VERSION "dbc-export 1 2025.20.8"

NS_ :

BS_:

BU_: BMS CC CMP CMPD CP DAS DI DIF DIR EPBL EPBR EVSE FC GTW HCML HCMR HVP ICR PCS PM PMF PMR PTC SCCM SCM SCS SDCR TAS UMC VC VCFRONT VCLEFT VCRIGHT VCSEC

BO_ 818 BMS_bmbMinMax: 6 BMS
 SG_ BMS_bmbMinMaxMultiplexer M : 0|2@1+ (1,0) [0|3] "" Vector__XXX
 SG_ BMS_thermistorNumTMin m0 : 2|4@1+ (1,0) [0|15] "" Vector__XXX
 SG_ BMS_thermistorNumTMax m0 : 8|4@1+ (1,0) [0|15] "" Vector__XXX
 SG_ BMS_thermistorTMax m0 : 16|8@1+ (0.5,-40) [-40|87.5] "DegC" Vector__XXX
 SG_ BMS_thermistorTMin m0 : 24|8@1+ (0.5,-40) [-40|87.5] "DegC" Vector__XXX
 SG_ BMS_thermistorTAvg m0 : 32|8@1+ (0.5,-40) [-40|87.5] "DegC" Vector__XXX
 SG_ BMS_brickVoltageMax m1 : 2|12@1+ (0.002,0) [0|5] "V" Vector__XXX
 SG_ BMS_brickVoltageMin m1 : 16|12@1+ (0.002,0) [0|5] "V" Vector__XXX
 SG_ BMS_brickNumVoltageMax m1 : 32|7@1+ (1,1) [1|128] "" Vector__XXX
 SG_ BMS_brickNumVoltageMin m1 : 40|7@1+ (1,1) [1|128] "" Vector__XXX

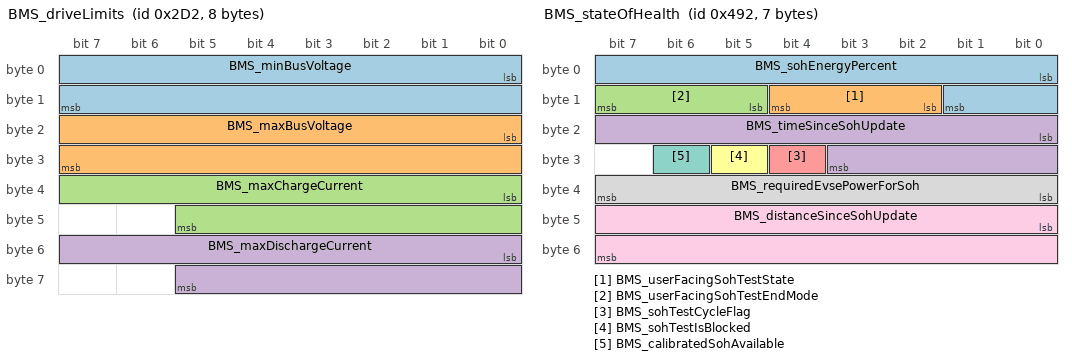
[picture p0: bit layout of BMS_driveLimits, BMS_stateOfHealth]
BO_ 722 BMS_driveLimits: 8 BMS
 SG_ BMS_minBusVoltage : 0|16@1+ (0.02,0) [0|1200] "V" Vector__XXX
 SG_ BMS_maxBusVoltage : 16|16@1+ (0.02,0) [0|1200] "V" Vector__XXX
 SG_ BMS_maxChargeCurrent : 32|14@1+ (0.1,0) [0|1638.2] "A" Vector__XXX
 SG_ BMS_maxDischargeCurrent : 48|14@1+ (0.15,0) [0|2455] "A" Vector__XXX

BO_ 850 BMS_energyStatus: 8 BMS
 SG_ BMS_energyStatusMultiplexer M : 0|2@1+ (1,0) [0|3] "" Vector__XXX
 SG_ BMS_nominalFullPackEnergy m0 : 16|16@1+ (0.02,0) [0|1310.68] "kWh" Vector__XXX
 SG_ BMS_nominalEnergyRemaining m0 : 32|16@1+ (0.02,0) [0|1310.68] "kWh" Vector__XXX
 SG_ BMS_idealEnergyRemaining m0 : 48|16@1+ (0.02,0) [0|1310.68] "kWh" Vector__XXX
 SG_ BMS_fullChargeComplete m1 : 15|1@1+ (1,0) [0|1] "" Vector__XXX
 SG_ BMS_energyBuffer m1 : 16|16@1+ (0.01,0) [0|655.34] "kWh" Vector__XXX
 SG_ BMS_expectedEnergyRemaining m1 : 32|16@1+ (0.02,0) [0|1310.68] "kWh" Vector__XXX
 SG_ BMS_energyToChargeComplete m1 : 48|16@1+ (0.02,0) [0|1310.68] "kWh" Vector__XXX
 SG_ BMS_energyRemainingDisplay m2 : 8|16@1+ (0.02,0) [0|1310.68] "kWh" Vector__XXX
 SG_ BMS_energyRemainingTDisplay m2 : 24|16@1+ (0.02,0) [0|1310.68] "kWh" Vector__XXX
 SG_ BMS_energyDisplayErrorBlendRate m2 : 40|12@1+ (0.0156288165599,0) [0|64] "%" Vector__XXX
 SG_ BMS_userFacingSoe m2 : 52|11@1+ (0.05,0) [0|100] "%" Vector__XXX

BO_ 768 BMS_info: 8 BMS
 SG_ BMS_infoIndex M : 0|8@1+ (1,0) [0|255] "" Vector__XXX
 SG_ BMS_buildType m10 : 8|3@1+ (1,0) [0|7] "" Vector__XXX
 SG_ BMS_buildConfigId m10 : 16|16@1+ (1,0) [0|65535] "" Vector__XXX
 SG_ BMS_hardwareId m10 : 32|16@1+ (1,0) [0|65535] "" Vector__XXX
 SG_ BMS_componentId m10 : 48|16@1+ (1,0) [0|65535] "" Vector__XXX
 SG_ BMS_pcbaId m11 : 16|8@1+ (1,0) [0|255] "" Vector__XXX
 SG_ BMS_assemblyId m11 : 24|8@1+ (1,0) [0|255] "" Vector__XXX
 SG_ BMS_usageId m11 : 32|16@1+ (1,0) [0|65535] "" Vector__XXX
 SG_ BMS_subUsageId m11 : 48|16@1+ (1,0) [0|65535] "" Vector__XXX
 SG_ BMS_platformType m13 : 8|8@1+ (1,0) [0|255] "" Vector__XXX
 SG_ BMS_appCrc m13 : 32|32@1+ (1,0) [0|4294967295] "" Vector__XXX
 SG_ BMS_appGitHash m17 : 8|56@1+ (1,0) [0|7.20575940379e+16] "" Vector__XXX
 SG_ BMS_bootGitHash m18 : 8|56@1+ (1,0) [0|7.20575940379e+16] "" Vector__XXX
 SG_ BMS_bootUdsProtoVersion m20 : 8|8@1+ (1,0) [0|255] "" Vector__XXX
 SG_ BMS_bootCrc m20 : 32|32@1+ (1,0) [0|4294967295] "" Vector__XXX

BO_ 978 BMS_kwhCounter: 8 BMS
 SG_ BMS_kwhDischargeTotal : 0|32@1+ (0.001,0) [0|268435.456] "KWh" Vector__XXX
 SG_ BMS_kwhChargeTotal : 32|32@1+ (0.001,0) [0|268435.456] "KWh" Vector__XXX

BO_ 1010 BMS_kwhCountersMultiplexed: 8 BMS
 SG_ BMS_kwhCounter_Id M : 0|4@1+ (1,0) [0|15] "" Vector__XXX
 SG_ BMS_acChargerKwhTotal m0 : 8|32@1+ (0.001,0) [0|268435.456] "KWh" Vector__XXX
 SG_ BMS_dcChargerKwhTotal m1 : 8|32@1+ (0.001,0) [0|268435.456] "KWh" Vector__XXX
 SG_ BMS_kwhRegenChargeTotal m2 : 8|32@1+ (0.001,0) [0|268435.456] "KWh" Vector__XXX
 SG_ BMS_kwhDriveDischargeTotal m3 : 8|32@1+ (0.001,0) [0|268435.456] "KWh" Vector__XXX
 SG_ BMS_kwhDischargeTotalModule1 m4 : 8|28@1+ (0.001,0) [0|268435.455] "KWh" Vector__XXX
 SG_ BMS_kwhChargeTotalModule1 m4 : 36|28@1+ (0.001,0) [0|268435.455] "KWh" Vector__XXX
 SG_ BMS_kwhAcChargeTotalModule1 m5 : 8|28@1+ (0.001,0) [0|268435.455] "KWh" Vector__XXX
 SG_ BMS_kwhDcChargeTotalModule1 m5 : 36|28@1+ (0.001,0) [0|268435.455] "KWh" Vector__XXX
 SG_ BMS_kwhDischargeTotalModule2 m6 : 8|28@1+ (0.001,0) [0|268435.455] "KWh" Vector__XXX
 SG_ BMS_kwhChargeTotalModule2 m6 : 36|28@1+ (0.001,0) [0|268435.455] "KWh" Vector__XXX
 SG_ BMS_kwhAcChargeTotalModule2 m7 : 8|28@1+ (0.001,0) [0|268435.455] "KWh" Vector__XXX
 SG_ BMS_kwhDcChargeTotalModule2 m7 : 36|28@1+ (0.001,0) [0|268435.455] "KWh" Vector__XXX
 SG_ BMS_kwhDischargeTotalModule3 m8 : 8|28@1+ (0.001,0) [0|268435.455] "KWh" Vector__XXX
 SG_ BMS_kwhChargeTotalModule3 m8 : 36|28@1+ (0.001,0) [0|268435.455] "KWh" Vector__XXX
 SG_ BMS_kwhAcChargeTotalModule3 m9 : 8|28@1+ (0.001,0) [0|268435.455] "KWh" Vector__XXX
 SG_ BMS_kwhDcChargeTotalModule3 m9 : 36|28@1+ (0.001,0) [0|268435.455] "KWh" Vector__XXX
 SG_ BMS_kwhDischargeTotalModule4 m10 : 8|28@1+ (0.001,0) [0|268435.455] "KWh" Vector__XXX
 SG_ BMS_kwhChargeTotalModule4 m10 : 36|28@1+ (0.001,0) [0|268435.455] "KWh" Vector__XXX
 SG_ BMS_kwhAcChargeTotalModule4 m11 : 8|28@1+ (0.001,0) [0|268435.455] "KWh" Vector__XXX
 SG_ BMS_kwhDcChargeTotalModule4 m11 : 36|28@1+ (0.001,0) [0|268435.455] "KWh" Vector__XXX

BO_ 1170 BMS_stateOfHealth: 7 BMS
 SG_ BMS_sohEnergyPercent : 0|10@1+ (0.1,0) [0|100] "%" Vector__XXX
 SG_ BMS_userFacingSohTestState : 10|3@1+ (1,0) [0|7] "" Vector__XXX
 SG_ BMS_userFacingSohTestEndMode : 13|3@1+ (1,0) [0|7] "" Vector__XXX
 SG_ BMS_timeSinceSohUpdate : 16|12@1+ (1,0) [0|3650] "days" Vector__XXX
 SG_ BMS_sohTestCycleFlag : 28|1@1+ (1,0) [0|1] "" Vector__XXX
 SG_ BMS_sohTestIsBlocked : 29|1@1+ (1,0) [0|1] "" Vector__XXX
 SG_ BMS_calibratedSohAvailable : 30|1@1+ (1,0) [0|1] "" Vector__XXX
 SG_ BMS_requiredEvsePowerForSoh : 32|8@1+ (0.125,0) [0|31.75] "kW" Vector__XXX
 SG_ BMS_distanceSinceSohUpdate : 40|16@1+ (1,0) [0|65534] "km" Vector__XXX

BO_ 1116 CC_alertLog: 8 CC
 SG_ CC_alertID M : 0|15@1+ (1,0) [0|32767] "" Vector__XXX
 SG_ CC_alertType : 15|1@1+ (1,0) [0|1] "" Vector__XXX
 SG_ CC_a001_groundResistance m1 : 16|12@1+ (1000,0) [0|4094000] "Ohm" Vector__XXX
 SG_ CC_a003_gfciRmsCurrent m3 : 16|12@1+ (0.001,0) [0|4.095] "A" Vector__XXX
 SG_ CC_a003_gfciRmsCurrentAvg m3 : 28|12@1+ (0.001,0) [0|4.095] "A" Vector__XXX
 SG_ CC_a003_dcGfciCurrent m3 : 40|10@1- (0.001,0) [-0.512|0.511] "A" Vector__XXX
 SG_ CC_a003_gfciFaultReason m3 : 50|4@1+ (1,0) [1|15] "" Vector__XXX
 SG_ CC_a003_gfciFaultBucket m3 : 56|4@1+ (1,0) [0|15] "" Vector__XXX
 SG_ CC_a004_gfciErrorReason m4 : 16|8@1+ (1,0) [1|255] "" Vector__XXX
 SG_ CC_a004_gfciAsicErrorBitfield m4 : 24|8@1+ (1,0) [0|255] "" Vector__XXX
 SG_ CC_a004_gfciSelfTestDuty m4 : 32|16@1- (0.0001,50) [46.7232|53.2767] "A" Vector__XXX
 SG_ CC_a004_gfciSelfTestCurrent m4 : 48|16@1- (0.0001,0) [-3.2768|3.2767] "A" Vector__XXX
 SG_ CC_a006_line1Current m6 : 16|16@1+ (0.01,0) [0|655.35] "A" Vector__XXX
 SG_ CC_a006_line2Current m6 : 32|16@1+ (0.01,0) [0|655.35] "A" Vector__XXX
 SG_ CC_a006_line3Current m6 : 48|16@1+ (0.01,0) [0|655.35] "A" Vector__XXX
 SG_ CC_a007_inputVoltage m7 : 16|16@1+ (0.01,0) [0|655.35] "V" Vector__XXX
 SG_ CC_a007_inputLineVoltage m7 : 32|16@1+ (0.01,0) [0|655.35] "V" Vector__XXX
 SG_ CC_a007_inputNeutralVoltage m7 : 48|16@1+ (0.01,0) [0|655.35] "V" Vector__XXX
 SG_ CC_a008_inputVoltage m8 : 16|16@1+ (0.01,0) [0|655.35] "V" Vector__XXX
 SG_ CC_a008_inputLineVoltage m8 : 32|16@1+ (0.01,0) [0|655.35] "V" Vector__XXX
 SG_ CC_a008_inputNeutralVoltage m8 : 48|16@1+ (0.01,0) [0|655.35] "V" Vector__XXX
 SG_ CC_a010_line1Voltage m10 : 16|12@1+ (0.1,0) [0|409.5] "V" Vector__XXX
 SG_ CC_a010_line2Voltage m10 : 28|12@1+ (0.1,0) [0|409.5] "V" Vector__XXX
 SG_ CC_a010_line3Voltage m10 : 40|12@1+ (0.1,0) [0|409.5] "V" Vector__XXX
 SG_ CC_a010_line1StuckClosed m10 : 52|1@1+ (1,0) [0|1] "" Vector__XXX
 SG_ CC_a010_line2StuckClosed m10 : 53|1@1+ (1,0) [0|1] "" Vector__XXX
 SG_ CC_a010_line3StuckClosed m10 : 54|1@1+ (1,0) [0|1] "" Vector__XXX
 SG_ CC_a011_pcbaTemp m11 : 16|9@1- (1,88) [-168|343] "DegC" Vector__XXX
 SG_ CC_a012_inputThermopile m12 : 16|12@1+ (1.0e-06,0) [0|0.004095] "V" Vector__XXX
 SG_ CC_a012_inputThermopileDvdt m12 : 28|12@1+ (1.0e-06,0) [0|0.004095] "V/sec" Vector__XXX
 SG_ CC_a013_handleTemp m13 : 16|9@1- (1,88) [-168|343] "DegC" Vector__XXX
 SG_ CC_a014_failureCause m14 : 16|9@1+ (1,0) [0|511] "" Vector__XXX
 SG_ CC_a014_meterFaultAddress m14 : 25|16@1+ (1,0) [0|65535] "" Vector__XXX
 SG_ CC_a014_meterFaultData m14 : 41|16@1+ (1,0) [0|65535] "" Vector__XXX
 SG_ CC_a014_meterRetryCount m14 : 57|4@1+ (1,0) [0|15] "" Vector__XXX
 SG_ CC_a015_pilotHighVolage m15 : 16|16@1+ (0.001,0) [0|65.535] "V" Vector__XXX
 SG_ CC_a015_smState m15 : 32|8@1+ (1,0) [0|255] "" Vector__XXX
 SG_ CC_a027_handleTemperature m27 : 16|12@1- (0.1,0) [-204.8|204.7] "DegC" Vector__XXX
 SG_ CC_a027_handleTempFaultReason m27 : 28|4@1+ (1,0) [0|15] "" Vector__XXX
 SG_ CC_a032_meteringSpiCommsFailure m32 : 16|1@1+ (1,0) [0|1] "" Vector__XXX
 SG_ CC_a032_meteringConfigMismatch m32 : 17|1@1+ (1,0) [0|1] "" Vector__XXX
 SG_ CC_a033_nominalVoltage m33 : 16|9@1+ (0.01,0) [0|5.11] "V" Vector__XXX
 SG_ CC_a033_measuredVoltage m33 : 25|9@1+ (0.01,0) [0|5.11] "V" Vector__XXX
 SG_ CC_a036_line1Voltage m36 : 16|12@1+ (0.1,0) [0|409.5] "V" Vector__XXX
 SG_ CC_a036_line2Voltage m36 : 28|12@1+ (0.1,0) [0|409.5] "V" Vector__XXX
 SG_ CC_a036_line3Voltage m36 : 40|12@1+ (0.1,0) [0|409.5] "V" Vector__XXX
 SG_ CC_a036_line1StuckOpen m36 : 52|1@1+ (1,0) [0|1] "" Vector__XXX
 SG_ CC_a036_line2StuckOpen m36 : 53|1@1+ (1,0) [0|1] "" Vector__XXX
 SG_ CC_a036_line3StuckOpen m36 : 54|1@1+ (1,0) [0|1] "" Vector__XXX
 SG_ CC_a037_expiredWatchdogModuleId m37 : 16|8@1+ (1,0) [0|255] "" Vector__XXX
 SG_ CC_a037_expiredWatchdogTaskId m37 : 24|8@1+ (1,0) [0|255] "" Vector__XXX
 SG_ CC_a037_expiredWatchdogAppCRC m37 : 32|32@1+ (1,0) [0|4294967295] "" Vector__XXX
 SG_ CC_a038_moduleMiaModuleId m38 : 16|8@1+ (1,0) [0|255] "" Vector__XXX
 SG_ CC_a038_moduleMiaTaskId m38 : 24|8@1+ (1,0) [0|255] "" Vector__XXX
 SG_ CC_a038_moduleMiaAppCRC m38 : 32|32@1+ (1,0) [0|4294967295] "" Vector__XXX
 SG_ CC_a039_intModuleTemperature m39 : 16|9@1- (1,88) [-168|343] "DegC" Vector__XXX
 SG_ CC_a040_handleTemperature m40 : 16|9@1- (1,88) [-168|343] "DegC" Vector__XXX
 SG_ CC_a041_inputThermopile m41 : 16|16@1- (1.0e-06,0) [-0.032768|0.032767] "V" Vector__XXX
 SG_ CC_a041_inputThermopileDvdt m41 : 32|16@1- (1.0e-06,0) [-0.032768|0.032767] "V/sec" Vector__XXX
 SG_ CC_a042_pcbaTemperature m42 : 16|9@1- (1,88) [-168|343] "DegC" Vector__XXX
 SG_ CC_a044_relayCoilVoltage m44 : 16|8@1+ (0.14,0) [0|35.7] "V" Vector__XXX
 SG_ CC_a044_pcbaTemperature m44 : 24|9@1- (1,88) [-168|343] "DegC" Vector__XXX

BO_ 1132 CC_alertMatrix1: 8 CC
 SG_ CC_a001_gndMonIntrptLineSide : 0|1@1+ (1,0) [0|1] "" Vector__XXX
 SG_ CC_a002_gndMonIntrptLoadSide : 1|1@1+ (1,0) [0|1] "" Vector__XXX
 SG_ CC_a003_CCIDTripped : 2|1@1+ (1,0) [0|1] "" Vector__XXX
 SG_ CC_a004_CCIDSelfTestFault : 3|1@1+ (1,0) [0|1] "" Vector__XXX
 SG_ CC_a005_groundedNeutral : 4|1@1+ (1,0) [0|1] "" Vector__XXX
 SG_ CC_a006_inputOverCurrent : 5|1@1+ (1,0) [0|1] "" Vector__XXX
 SG_ CC_a007_inputOverVoltage : 6|1@1+ (1,0) [0|1] "" Vector__XXX
 SG_ CC_a008_inputUnderVoltage : 7|1@1+ (1,0) [0|1] "" Vector__XXX
 SG_ CC_a009_inputMiswired : 8|1@1+ (1,0) [0|1] "" Vector__XXX
 SG_ CC_a010_contactorWelded : 9|1@1+ (1,0) [0|1] "" Vector__XXX
 SG_ CC_a011_ambientOT : 10|1@1+ (1,0) [0|1] "" Vector__XXX
 SG_ CC_a012_wallPlugOT : 11|1@1+ (1,0) [0|1] "" Vector__XXX
 SG_ CC_a013_vehConnOT : 12|1@1+ (1,0) [0|1] "" Vector__XXX
 SG_ CC_a014_mcuSelfTestFault : 13|1@1+ (1,0) [0|1] "" Vector__XXX
 SG_ CC_a015_PilotAFault : 14|1@1+ (1,0) [0|1] "" Vector__XXX
 SG_ CC_a016_PilotBFault : 15|1@1+ (1,0) [0|1] "" Vector__XXX
 SG_ CC_a017_PilotCFault : 16|1@1+ (1,0) [0|1] "" Vector__XXX
 SG_ CC_a018_PilotDFault : 17|1@1+ (1,0) [0|1] "" Vector__XXX
 SG_ CC_a019_proxDisconnected : 18|1@1+ (1,0) [0|1] "" Vector__XXX
 SG_ CC_a020_3vRailIncorrect : 19|1@1+ (1,0) [0|1] "" Vector__XXX
 SG_ CC_a021_CB_noMaster : 20|1@1+ (1,0) [0|1] "" Vector__XXX
 SG_ CC_a022_CB_tooManyMasters : 21|1@1+ (1,0) [0|1] "" Vector__XXX
 SG_ CC_a023_CB_tooManySlaves : 22|1@1+ (1,0) [0|1] "" Vector__XXX
 SG_ CC_a024_CB_masterISetTooLow : 23|1@1+ (1,0) [0|1] "" Vector__XXX
 SG_ CC_a025_evseTemp : 24|1@1+ (1,0) [0|1] "" Vector__XXX
 SG_ CC_a026_wallPlugTemp : 25|1@1+ (1,0) [0|1] "" Vector__XXX
 SG_ CC_a027_vehicleHandleTemp : 26|1@1+ (1,0) [0|1] "" Vector__XXX
 SG_ CC_a028_CB_rotarySelect : 27|1@1+ (1,0) [0|1] "" Vector__XXX
 SG_ CC_a029_PilotFFault : 28|1@1+ (1,0) [0|1] "" Vector__XXX
 SG_ CC_a030_masterSlaveMismatch : 29|1@1+ (1,0) [0|1] "" Vector__XXX
 SG_ CC_a031_pllLockLost : 30|1@1+ (1,0) [0|1] "" Vector__XXX
 SG_ CC_a032_meteringFailure : 31|1@1+ (1,0) [0|1] "" Vector__XXX
 SG_ CC_a033_vRefOutOfRange : 32|1@1+ (1,0) [0|1] "" Vector__XXX
 SG_ CC_a034_bootAlert : 33|1@1+ (1,0) [0|1] "" Vector__XXX
 SG_ CC_a035_CCIDCalibration : 34|1@1+ (1,0) [0|1] "" Vector__XXX
 SG_ CC_a036_contactorStuckOpen : 35|1@1+ (1,0) [0|1] "" Vector__XXX
 SG_ CC_a037_internalModuleWatchdogEx : 36|1@1+ (1,0) [0|1] "" Vector__XXX
 SG_ CC_a038_internalModuleMia : 37|1@1+ (1,0) [0|1] "" Vector__XXX
 SG_ CC_a039_internalModuleOverTemp : 38|1@1+ (1,0) [0|1] "" Vector__XXX
 SG_ CC_a040_handleTempFoldback : 39|1@1+ (1,0) [0|1] "" Vector__XXX
 SG_ CC_a041_inputWiringFoldback : 40|1@1+ (1,0) [0|1] "" Vector__XXX
 SG_ CC_a042_pcbaTempFoldback : 41|1@1+ (1,0) [0|1] "" Vector__XXX
 SG_ CC_a043_configurationRequired : 42|1@1+ (1,0) [0|1] "" Vector__XXX
 SG_ CC_a044_relayCoilVoltageRational : 43|1@1+ (1,0) [0|1] "" Vector__XXX
 SG_ CC_a045_ACPowerLoss : 44|1@1+ (1,0) [0|1] "" Vector__XXX
 SG_ CC_a046_GFCIConfigInvalid : 45|1@1+ (1,0) [0|1] "" Vector__XXX
 SG_ CC_a047_MDMotorContFault : 46|1@1+ (1,0) [0|1] "" Vector__XXX
 SG_ CC_a048_ACMDAdapterFault : 47|1@1+ (1,0) [0|1] "" Vector__XXX
 SG_ CC_a049_rs485Fault : 48|1@1+ (1,0) [0|1] "" Vector__XXX
 SG_ CC_a050_eFuseFault : 49|1@1+ (1,0) [0|1] "" Vector__XXX
 SG_ CC_a051_chcCriticalFault : 50|1@1+ (1,0) [0|1] "" Vector__XXX
 SG_ CC_a052_vRefOutOfRangePWM : 51|1@1+ (1,0) [0|1] "" Vector__XXX
 SG_ CC_a057_chcVitalsRequestFailure : 56|1@1+ (1,0) [0|1] "" Vector__XXX
 SG_ CC_a060_persistenceFault : 59|1@1+ (1,0) [0|1] "" Vector__XXX
 SG_ CC_a061_unfinishedCommissioning : 60|1@1+ (1,0) [0|1] "" Vector__XXX

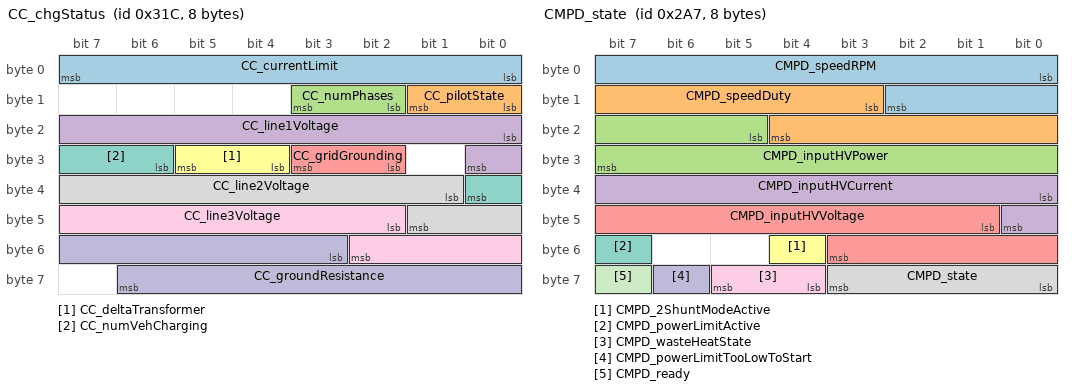
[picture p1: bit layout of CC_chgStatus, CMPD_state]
BO_ 796 CC_chgStatus: 8 CC
 SG_ CC_currentLimit : 0|8@1+ (0.5,0) [0|127] "A" Vector__XXX
 SG_ CC_pilotState : 8|2@1+ (1,0) [0|2] "" Vector__XXX
 SG_ CC_numPhases : 10|2@1+ (1,0) [1|3] "" Vector__XXX
 SG_ CC_line1Voltage : 16|9@1+ (1,0) [0|510] "V" Vector__XXX
 SG_ CC_gridGrounding : 26|2@1+ (1,0) [0|3] "" Vector__XXX
 SG_ CC_deltaTransformer : 28|2@1+ (1,0) [0|3] "" Vector__XXX
 SG_ CC_numVehCharging : 30|3@1+ (1,0) [0|7] "" Vector__XXX
 SG_ CC_line2Voltage : 33|9@1+ (1,0) [0|510] "V" Vector__XXX
 SG_ CC_line3Voltage : 42|9@1+ (1,0) [0|510] "V" Vector__XXX
 SG_ CC_groundResistance : 51|12@1+ (1,0) [0|4094] "kOhm" Vector__XXX

BO_ 812 CC_logData: 8 CC
 SG_ CC_logIndex M : 0|8@1+ (1,0) [0|255] "" Vector__XXX
 SG_ CC_activeConnectorID m0 : 8|8@1+ (1,0) [0|255] "" Vector__XXX
 SG_ CC_temperature1 m0 : 16|8@1- (1,88) [-40|215] "DegC" Vector__XXX
 SG_ CC_temperature2 m0 : 24|8@1- (1,88) [-40|215] "DegC" Vector__XXX
 SG_ CC_temperature3 m0 : 32|8@1- (1,88) [-40|215] "DegC" Vector__XXX
 SG_ CC_contactor1Closed m0 : 40|2@1+ (1,0) [0|3] "" Vector__XXX
 SG_ CC_contactor2Closed m0 : 42|2@1+ (1,0) [0|3] "" Vector__XXX
 SG_ CC_temperature4 m0 : 44|8@1- (1,88) [-40|215] "DegC" Vector__XXX
 SG_ CC_conn1Current m1 : 8|8@1+ (0.5,0) [0|127] "A" Vector__XXX
 SG_ CC_conn2Current m2 : 8|8@1+ (0.5,0) [0|127] "A" Vector__XXX
 SG_ CC_conn3Current m3 : 8|8@1+ (0.5,0) [0|127] "A" Vector__XXX
 SG_ CC_conn4Current m4 : 8|8@1+ (0.5,0) [0|127] "A" Vector__XXX
 SG_ CC_lifetimei2t m10 : 32|32@1+ (0.1,0) [0|429496729.5] "A2h" Vector__XXX
 SG_ CC_lifetimeCtrCycles m11 : 8|28@1+ (1,0) [0|268435455] "" Vector__XXX
 SG_ CC_lifetimeCtrCyclesLoaded m11 : 36|28@1+ (1,0) [0|268435455] "" Vector__XXX
 SG_ CC_lifetimeAlertCount m12 : 8|28@1+ (1,0) [0|268435455] "" Vector__XXX
 SG_ CC_lifetimeThermalFoldbacks m12 : 36|28@1+ (1,0) [0|268435455] "" Vector__XXX
 SG_ CC_lifetimeAvgStartupTemp m13 : 36|28@1- (0.1,0) [-13421772.8|13421772.7] "degC" Vector__XXX

BO_ 870 CMPD_info: 8 CMPD
 SG_ CMPD_infoIndex M : 0|8@1+ (1,0) [0|255] "" Vector__XXX
 SG_ CMPD_infoBuildType m10 : 8|8@1+ (1,0) [0|255] "" Vector__XXX
 SG_ CMPD_infoBuildConfigId m10 : 16|16@1+ (1,0) [0|65535] "" Vector__XXX
 SG_ CMPD_infoHardwareId m10 : 32|16@1+ (1,0) [0|65535] "" Vector__XXX
 SG_ CMPD_infoComponentId m10 : 48|16@1+ (1,0) [0|65535] "" Vector__XXX
 SG_ CMPD_infoPcbaId m11 : 16|8@1+ (1,0) [0|255] "" Vector__XXX
 SG_ CMPD_infoAssemblyId m11 : 24|8@1+ (1,0) [0|254] "" Vector__XXX
 SG_ CMPD_infoUsageId m11 : 32|16@1+ (1,0) [0|65535] "" Vector__XXX
 SG_ CMPD_infoSubUsageId m11 : 48|16@1+ (1,0) [0|65535] "" Vector__XXX

BO_ 679 CMPD_state: 8 CMPD
 SG_ CMPD_speedRPM : 0|11@1+ (10,0) [0|20000] "RPM" Vector__XXX
 SG_ CMPD_speedDuty : 11|10@1+ (0.1,0) [0|100] "%" Vector__XXX
 SG_ CMPD_inputHVPower : 21|11@1+ (10,0) [0|20000] "W" Vector__XXX
 SG_ CMPD_inputHVCurrent : 32|9@1+ (0.1,0) [0|50] "A" Vector__XXX
 SG_ CMPD_inputHVVoltage : 41|11@1+ (0.5,0) [0|1000] "V" Vector__XXX
 SG_ CMPD_2ShuntModeActive : 52|1@1+ (1,0) [0|1] "" Vector__XXX
 SG_ CMPD_powerLimitActive : 55|1@1+ (1,0) [0|1] "" Vector__XXX
 SG_ CMPD_state : 56|4@1+ (1,0) [0|14] "" Vector__XXX
 SG_ CMPD_wasteHeatState : 60|2@1+ (1,0) [0|3] "" Vector__XXX
 SG_ CMPD_powerLimitTooLowToStart : 62|1@1+ (1,0) [0|1] "" Vector__XXX
 SG_ CMPD_ready : 63|1@1+ (1,0) [0|1] "" Vector__XXX

BO_ 867 CMP_info: 8 CMP
 SG_ CMP_infoIndex M : 0|8@1+ (1,0) [0|255] "" Vector__XXX
 SG_ CMP_infoBuildType m10 : 8|8@1+ (1,0) [0|255] "" Vector__XXX
 SG_ CMP_infoBuildConfigId m10 : 16|16@1+ (1,0) [0|65535] "" Vector__XXX
 SG_ CMP_infoHardwareId m10 : 32|16@1+ (1,0) [0|65535] "" Vector__XXX
 SG_ CMP_infoComponentId m10 : 48|16@1+ (1,0) [0|65535] "" Vector__XXX
 SG_ CMP_infoPcbaId m11 : 16|8@1+ (1,0) [0|255] "" Vector__XXX
 SG_ CMP_infoAssemblyId m11 : 24|8@1+ (1,0) [0|254] "" Vector__XXX
 SG_ CMP_infoUsageId m11 : 32|16@1+ (1,0) [0|65535] "" Vector__XXX
 SG_ CMP_infoSubUsageId m11 : 48|16@1+ (1,0) [0|65535] "" Vector__XXX
 SG_ CMP_infoPlatformType m13 : 8|8@1+ (1,0) [0|255] "" Vector__XXX
 SG_ CMP_infoAppCrc m13 : 32|32@1+ (1,0) [0|4294967295] "" Vector__XXX
 SG_ CMP_infoBootUdsProtoVersion m20 : 8|8@1+ (1,0) [0|255] "" Vector__XXX
 SG_ CMP_infoBootCrc m20 : 32|32@1+ (1,0) [0|4294967295] "" Vector__XXX

BO_ 1767 CP_IsoTpPipeToPncd: 8 CP
 SG_ CP_isoTpToPncdData : 0|64@1+ (1,0) [0|1.84467440737e+19] "" Vector__XXX

BO_ 1342 CP_info: 8 CP
 SG_ CP_infoIndex M : 0|8@1+ (1,0) [0|255] "" Vector__XXX
 SG_ CP_buildType m10 : 8|3@1+ (1,0) [0|7] "" Vector__XXX
 SG_ CP_buildConfigId m10 : 16|16@1+ (1,0) [0|65535] "" Vector__XXX
 SG_ CP_hardwareId m10 : 32|16@1+ (1,0) [0|65535] "" Vector__XXX
 SG_ CP_componentId m10 : 48|16@1+ (1,0) [0|65535] "" Vector__XXX
 SG_ CP_pcbaId m11 : 16|8@1+ (1,0) [0|255] "" Vector__XXX
 SG_ CP_assemblyId m11 : 24|8@1+ (1,0) [0|255] "" Vector__XXX
 SG_ CP_usageId m11 : 32|16@1+ (1,0) [0|65535] "" Vector__XXX
 SG_ CP_subUsageId m11 : 48|16@1+ (1,0) [0|65535] "" Vector__XXX
 SG_ CP_platformType m13 : 8|8@1+ (1,0) [0|255] "" Vector__XXX
 SG_ CP_appCrc m13 : 32|32@1+ (1,0) [0|4294967295] "" Vector__XXX
 SG_ CP_appGitHash m17 : 8|56@1+ (1,0) [0|7.20575940379e+16] "" Vector__XXX
 SG_ CP_bootGitHash m18 : 8|56@1+ (1,0) [0|7.20575940379e+16] "" Vector__XXX
 SG_ CP_bootUdsProtoVersion m20 : 8|8@1+ (1,0) [0|255] "" Vector__XXX
 SG_ CP_bootCrc m20 : 32|32@1+ (1,0) [0|4294967295] "" Vector__XXX

BO_ 1001 DAS_bodyControls: 8 DAS
 SG_ DAS_headlightRequest : 0|2@1+ (1,0) [0|3] "" Vector__XXX
 SG_ DAS_hazardLightRequest : 2|2@1+ (1,0) [0|2] "" Vector__XXX
 SG_ DAS_wiperSpeed : 4|4@1+ (1,0) [0|15] "" Vector__XXX
 SG_ DAS_turnIndicatorRequest : 8|3@1+ (1,0) [0|7] "" Vector__XXX
 SG_ DAS_highLowBeamDecision : 11|2@1+ (1,0) [0|2] "" Vector__XXX
 SG_ DAS_heaterRequest : 13|2@1+ (1,0) [1|3] "" Vector__XXX
 SG_ DAS_highLowBeamOffReason : 15|3@1+ (1,0) [0|7] "" Vector__XXX
 SG_ DAS_forwardCamHeaterDutyCycle : 18|4@1+ (0.06666667,0) [0|1] "-" Vector__XXX
 SG_ DAS_dynamicBrakeLightRequest : 22|1@1+ (1,0) [0|1] "" Vector__XXX
 SG_ DAS_radarHeaterRequest : 23|1@1+ (1,0) [0|1] "" Vector__XXX
 SG_ DAS_ahlbOverride : 24|1@1+ (1,0) [0|1] "" Vector__XXX
 SG_ DAS_mirrorFoldRequest : 25|2@1+ (1,0) [0|2] "" Vector__XXX
 SG_ DAS_wiperWashRequest : 27|1@1+ (1,0) [0|1] "" Vector__XXX
 SG_ DAS_ulcConfirmationRequestActive : 28|1@1+ (1,0) [0|1] "" Vector__XXX
 SG_ DAS_overrideWiperSetting : 29|1@1+ (1,0) [0|1] "" Vector__XXX
 SG_ DAS_autoWiperState : 30|3@1+ (1,0) [0|7] "" Vector__XXX
 SG_ DAS_turnIndicatorRequestReason : 33|5@1+ (1,0) [0|31] "" Vector__XXX
 SG_ DAS_forwardRadarPowerRequest : 38|1@1+ (1,0) [0|1] "" Vector__XXX
 SG_ DAS_driverDomeLightRequest : 39|1@1+ (1,0) [0|1] "" Vector__XXX
 SG_ DAS_drivePowerStateRequest : 43|1@1+ (1,0) [0|1] "" Vector__XXX
 SG_ DAS_enableIcrDataCollection : 44|1@1+ (1,0) [0|1] "" Vector__XXX
 SG_ DAS_rPillarCamHeaterDutyCycle : 45|4@1+ (0.06666667,0) [0|1] "-" Vector__XXX
 SG_ DAS_adaptiveHighBeamIsFaulted : 49|1@1+ (1,0) [0|1] "" Vector__XXX
 SG_ DAS_restrictDoorReleaseLeft : 50|1@1+ (1,0) [0|1] "" Vector__XXX
 SG_ DAS_restrictDoorReleaseRight : 51|1@1+ (1,0) [0|1] "" Vector__XXX
 SG_ DAS_bodyControlsCounter : 52|4@1+ (1,0) [0|15] "" Vector__XXX
 SG_ DAS_bodyControlsChecksum : 56|8@1+ (1,0) [0|255] "" Vector__XXX

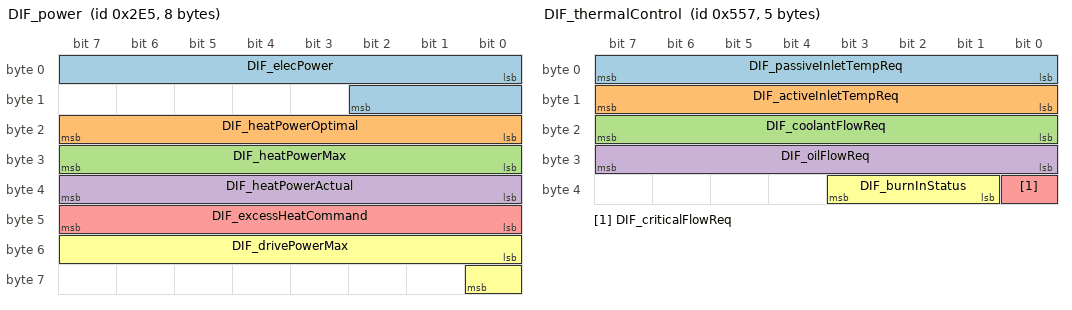
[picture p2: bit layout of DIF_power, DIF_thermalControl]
BO_ 741 DIF_power: 8 DIF
 SG_ DIF_elecPower : 0|11@1- (0.5,0) [-500|500] "kW" Vector__XXX
 SG_ DIF_heatPowerOptimal : 16|8@1+ (0.08,0) [0|20] "kW" Vector__XXX
 SG_ DIF_heatPowerMax : 24|8@1+ (0.08,0) [0|20] "kW" Vector__XXX
 SG_ DIF_heatPowerActual : 32|8@1+ (0.08,0) [0|20] "kW" Vector__XXX
 SG_ DIF_excessHeatCommand : 40|8@1+ (0.08,0) [0|20] "kW" Vector__XXX
 SG_ DIF_drivePowerMax : 48|9@1+ (1,0) [0|400] "kW" Vector__XXX

BO_ 1367 DIF_thermalControl: 5 DIF
 SG_ DIF_passiveInletTempReq : 0|8@1+ (1,-40) [-40|215] "DegC" Vector__XXX
 SG_ DIF_activeInletTempReq : 8|8@1+ (1,-40) [-40|215] "DegC" Vector__XXX
 SG_ DIF_coolantFlowReq : 16|8@1+ (0.2,0) [0|50] "LPM" Vector__XXX
 SG_ DIF_oilFlowReq : 24|8@1+ (0.1,0) [0|25.4] "LPM" Vector__XXX
 SG_ DIF_criticalFlowReq : 32|1@1+ (1,0) [0|1] "" Vector__XXX
 SG_ DIF_burnInStatus : 33|3@1+ (1,0) [0|7] "" Vector__XXX

BO_ 2005 DIR_debug: 8 DIR
 SG_ DIR_debugSelector M : 0|8@1+ (1,0) [0|255] "" Vector__XXX
 SG_ DIR_phaseOutBusbarTemp m70 : 8|8@1+ (1,-40) [-39|215] "DegC" Vector__XXX
 SG_ DIR_phaseOutBusbarWeldTemp m70 : 16|8@1+ (1,-40) [-39|215] "DegC" Vector__XXX
 SG_ DIR_phaseOutLugTemp m70 : 24|8@1+ (1,-40) [-39|215] "DegC" Vector__XXX
 SG_ DIR_dcLinkCapTemp m70 : 32|8@1+ (1,-40) [-39|215] "DegC" Vector__XXX
 SG_ DIR_hvDcCableTemp m70 : 40|8@1+ (1,-40) [-39|215] "DegC" Vector__XXX
 SG_ DIR_negDcBusbarTemp m70 : 48|8@1+ (1,-40) [-39|215] "DegC" Vector__XXX
 SG_ DIR_posDcBusbarTemp m70 : 56|8@1+ (1,-40) [-39|215] "DegC" Vector__XXX
 SG_ DIR_statorEndWindingTemp m72 : 8|8@1+ (1,-40) [-39|215] "DegC" Vector__XXX
 SG_ DIR_rotorMaxMagnetTemp m72 : 16|8@1+ (1,-40) [-39|215] "DegC" Vector__XXX
 SG_ DIR_lightSenseV m72 : 24|6@1+ (0.1,0) [0|3.3] "V" Vector__XXX
 SG_ DIR_pyroSenseV m72 : 30|8@1+ (0.02,0) [0|3.3] "V" Vector__XXX
 SG_ DIR_statorSlotWindingTemp m72 : 46|8@1+ (1,-40) [-39|215] "DegC" Vector__XXX
 SG_ DIR_intervalMaxHvBusV m72 : 54|10@1+ (1,0) [0|1023] "V" Vector__XXX

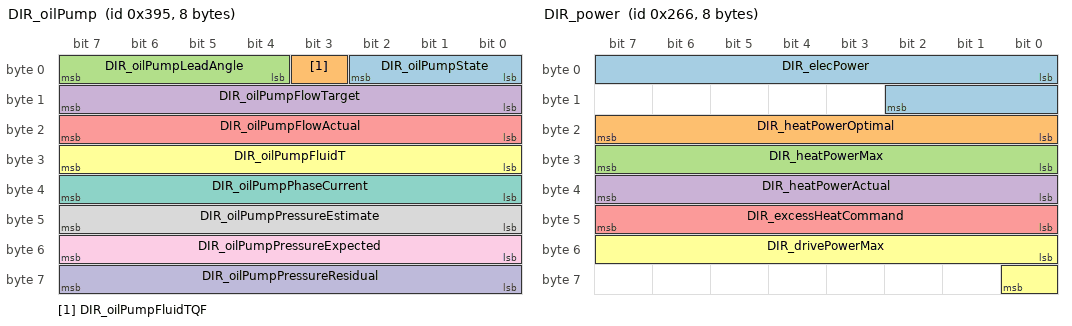
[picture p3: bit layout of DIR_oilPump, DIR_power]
BO_ 917 DIR_oilPump: 8 DIR
 SG_ DIR_oilPumpState : 0|3@1+ (1,0) [0|6] "" Vector__XXX
 SG_ DIR_oilPumpFluidTQF : 3|1@1+ (1,0) [0|1] "" Vector__XXX
 SG_ DIR_oilPumpLeadAngle : 4|4@1+ (1.875,0) [0|28.125] "degrees" Vector__XXX
 SG_ DIR_oilPumpFlowTarget : 8|8@1+ (0.1,0) [0|25.4] "LPM" Vector__XXX
 SG_ DIR_oilPumpFlowActual : 16|8@1+ (0.1,0) [0|25.4] "LPM" Vector__XXX
 SG_ DIR_oilPumpFluidT : 24|8@1+ (1,-40) [-40|214] "DegC" Vector__XXX
 SG_ DIR_oilPumpPhaseCurrent : 32|8@1+ (0.1,0) [0|25.4] "A" Vector__XXX
 SG_ DIR_oilPumpPressureEstimate : 40|8@1+ (2,0) [0|500] "kPa" Vector__XXX
 SG_ DIR_oilPumpPressureExpected : 48|8@1+ (2,0) [0|500] "kPa" Vector__XXX
 SG_ DIR_oilPumpPressureResidual : 56|8@1+ (4,-500) [-500|500] "kPa" Vector__XXX

BO_ 614 DIR_power: 8 DIR
 SG_ DIR_elecPower : 0|11@1- (0.5,0) [-500|500] "kW" Vector__XXX
 SG_ DIR_heatPowerOptimal : 16|8@1+ (0.08,0) [0|20] "kW" Vector__XXX
 SG_ DIR_heatPowerMax : 24|8@1+ (0.08,0) [0|20] "kW" Vector__XXX
 SG_ DIR_heatPowerActual : 32|8@1+ (0.08,0) [0|20] "kW" Vector__XXX
 SG_ DIR_excessHeatCommand : 40|8@1+ (0.08,0) [0|20] "kW" Vector__XXX
 SG_ DIR_drivePowerMax : 48|9@1+ (1,0) [0|400] "kW" Vector__XXX

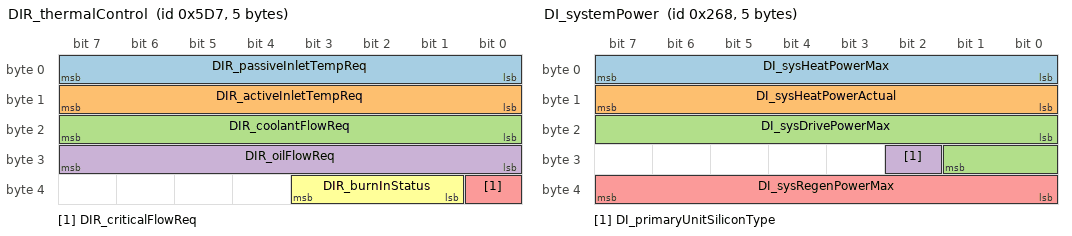
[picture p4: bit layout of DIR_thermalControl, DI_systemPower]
BO_ 1495 DIR_thermalControl: 5 DIR
 SG_ DIR_passiveInletTempReq : 0|8@1+ (1,-40) [-40|215] "DegC" Vector__XXX
 SG_ DIR_activeInletTempReq : 8|8@1+ (1,-40) [-40|215] "DegC" Vector__XXX
 SG_ DIR_coolantFlowReq : 16|8@1+ (0.2,0) [0|50] "LPM" Vector__XXX
 SG_ DIR_oilFlowReq : 24|8@1+ (0.1,0) [0|25.4] "LPM" Vector__XXX
 SG_ DIR_criticalFlowReq : 32|1@1+ (1,0) [0|1] "" Vector__XXX
 SG_ DIR_burnInStatus : 33|3@1+ (1,0) [0|7] "" Vector__XXX

BO_ 2007 DI_debug: 8 DI
 SG_ DI_debugSelector M : 0|8@1+ (1,0) [0|255] "" Vector__XXX
 SG_ DI_regenBackfillCmd m39 : 8|13@1+ (2,0) [0|16382] "Nm" Vector__XXX
 SG_ DI_regenBackfillUnavailableReaso m39 : 21|5@1+ (1,0) [0|31] "" Vector__XXX
 SG_ DI_regenBackfillAbsSatState m39 : 26|2@1+ (1,0) [0|3] "" Vector__XXX
 SG_ DI_sysHeatPowerOptimal m50 : 8|8@1+ (0.08,0) [0|20] "kW" Vector__XXX
 SG_ DI_sysPostPedalMinTorque m53 : 8|15@1+ (0.5,-13000) [-13000|0] "Nm" Vector__XXX
 SG_ DI_sysPostPedalMaxTorque m53 : 24|15@1+ (0.5,0) [0|13000] "Nm" Vector__XXX
 SG_ DI_systemTorqueCommand m53 : 40|16@1- (0.5,0) [-13000|13000] "Nm" Vector__XXX

BO_ 616 DI_systemPower: 5 DI
 SG_ DI_sysHeatPowerMax : 0|8@1+ (0.08,0) [0|20] "kW" Vector__XXX
 SG_ DI_sysHeatPowerActual : 8|8@1+ (0.08,0) [0|20] "kW" Vector__XXX
 SG_ DI_sysDrivePowerMax : 16|10@1+ (1,0) [0|1023] "kW" Vector__XXX
 SG_ DI_primaryUnitSiliconType : 26|1@1+ (1,0) [0|1] "" Vector__XXX
 SG_ DI_sysRegenPowerMax : 32|8@1+ (1,-100) [-100|0] "kW" Vector__XXX

BO_ 1992 EPBL_info: 8 EPBL
 SG_ EPBL_infoIndex M : 0|8@1+ (1,0) [0|255] "" Vector__XXX
 SG_ EPBL_infoBuildType m10 : 8|3@1+ (1,0) [0|7] "" Vector__XXX
 SG_ EPBL_infoBuildConfigId m10 : 16|16@1+ (1,0) [0|65535] "" Vector__XXX
 SG_ EPBL_infoHardwareId m10 : 32|16@1+ (1,0) [0|65535] "" Vector__XXX
 SG_ EPBL_infoComponentId m10 : 48|16@1+ (1,0) [0|65535] "" Vector__XXX
 SG_ EPBL_infoPcbaId m11 : 8|8@1+ (1,0) [0|255] "" Vector__XXX
 SG_ EPBL_infoAssemblyId m11 : 16|8@1+ (1,0) [0|254] "" Vector__XXX
 SG_ EPBL_infoUsageId m11 : 24|16@1+ (1,0) [0|65535] "" Vector__XXX
 SG_ EPBL_infoSubUsageId m11 : 40|16@1+ (1,0) [0|65535] "" Vector__XXX
 SG_ EPBL_infoAppCrc m13 : 8|32@1+ (1,0) [0|4294967295] "" Vector__XXX
 SG_ EPBL_infoAppGitHash m17 : 8|56@1+ (1,0) [0|7.20575940379e+16] "" Vector__XXX
 SG_ EPBL_infoBootGitHash m18 : 8|56@1+ (1,0) [0|7.20575940379e+16] "" Vector__XXX
 SG_ EPBL_infoPlatformType m19 : 8|8@1+ (1,0) [0|255] "" Vector__XXX
 SG_ EPBL_infoBootUdsProtoVersion m20 : 8|16@1+ (1,0) [0|65535] "" Vector__XXX
 SG_ EPBL_infoBootCrc m20 : 24|32@1+ (1,0) [0|4294967295] "" Vector__XXX

BO_ 648 EPBL_internalStatus: 8 EPBL
 SG_ EPBL_unitStatus : 0|5@1+ (1,0) [0|31] "" Vector__XXX
 SG_ EPBL_unitFaultStatus : 5|2@1+ (1,0) [0|3] "" Vector__XXX
 SG_ EPBL_summonState : 8|3@1+ (1,0) [0|7] "" Vector__XXX
 SG_ EPBL_disconnected : 11|1@1+ (1,0) [0|1] "" Vector__XXX
 SG_ EPBL_pistonTouchingRotor : 12|1@1+ (1,0) [0|1] "" Vector__XXX
 SG_ EPBL_csmFaultReason : 13|5@1+ (1,0) [0|31] "" Vector__XXX
 SG_ EPBL_esmOperationTrigger : 18|6@1+ (1,0) [0|63] "" Vector__XXX
 SG_ EPBL_summonFaultReason : 24|5@1+ (1,0) [0|31] "" Vector__XXX
 SG_ EPBL_localServiceModeActive : 29|1@1+ (1,0) [0|1] "" Vector__XXX
 SG_ EPBL_localCdpState : 30|2@1+ (1,0) [0|3] "" Vector__XXX
 SG_ EPBL_chimeRequestLocal : 33|3@1+ (1,0) [0|7] "" Vector__XXX
 SG_ EPBL_telltaleLocal : 39|3@1+ (1,0) [0|6] "" Vector__XXX
 SG_ EPBL_driverIsLeavingLocal : 42|1@1+ (1,0) [0|1] "" Vector__XXX
 SG_ EPBL_driverIsLeavingAnySpeedLoca : 43|1@1+ (1,0) [0|1] "" Vector__XXX
 SG_ EPBL_internalCDPRequest : 44|1@1+ (1,0) [0|1] "" Vector__XXX
 SG_ EPBL_esmSpeedClass : 45|3@1+ (1,0) [0|7] "" Vector__XXX
 SG_ EPBL_learnedEpbConfig : 48|4@1+ (1,0) [0|15] "" Vector__XXX
 SG_ EPBL_internalStatusCounter : 52|4@1+ (1,0) [0|15] "" Vector__XXX
 SG_ EPBL_internalStatusChecksum : 56|8@1+ (1,0) [0|255] "" Vector__XXX

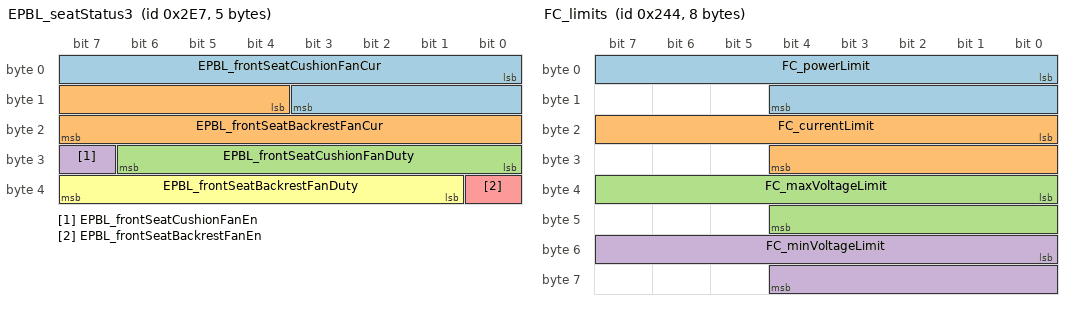
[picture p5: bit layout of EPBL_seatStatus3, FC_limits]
BO_ 743 EPBL_seatStatus3: 5 EPBL
 SG_ EPBL_frontSeatCushionFanCur : 0|12@1+ (0.01,0) [0|40.95] "A" Vector__XXX
 SG_ EPBL_frontSeatBackrestFanCur : 12|12@1+ (0.01,0) [0|40.95] "A" Vector__XXX
 SG_ EPBL_frontSeatCushionFanDuty : 24|7@1+ (1,0) [0|100] "%" Vector__XXX
 SG_ EPBL_frontSeatCushionFanEn : 31|1@1+ (1,0) [0|1] "" Vector__XXX
 SG_ EPBL_frontSeatBackrestFanEn : 32|1@1+ (1,0) [0|1] "" Vector__XXX
 SG_ EPBL_frontSeatBackrestFanDuty : 33|7@1+ (1,0) [0|100] "%" Vector__XXX

BO_ 2024 EPBR_info: 8 EPBR
 SG_ EPBR_infoIndex M : 0|8@1+ (1,0) [0|255] "" Vector__XXX
 SG_ EPBR_infoBuildType m10 : 8|3@1+ (1,0) [0|7] "" Vector__XXX
 SG_ EPBR_infoBuildConfigId m10 : 16|16@1+ (1,0) [0|65535] "" Vector__XXX
 SG_ EPBR_infoHardwareId m10 : 32|16@1+ (1,0) [0|65535] "" Vector__XXX
 SG_ EPBR_infoComponentId m10 : 48|16@1+ (1,0) [0|65535] "" Vector__XXX
 SG_ EPBR_infoPcbaId m11 : 8|8@1+ (1,0) [0|255] "" Vector__XXX
 SG_ EPBR_infoAssemblyId m11 : 16|8@1+ (1,0) [0|254] "" Vector__XXX
 SG_ EPBR_infoUsageId m11 : 24|16@1+ (1,0) [0|65535] "" Vector__XXX
 SG_ EPBR_infoSubUsageId m11 : 40|16@1+ (1,0) [0|65535] "" Vector__XXX
 SG_ EPBR_infoAppCrc m13 : 8|32@1+ (1,0) [0|4294967295] "" Vector__XXX
 SG_ EPBR_infoAppGitHash m17 : 8|56@1+ (1,0) [0|7.20575940379e+16] "" Vector__XXX
 SG_ EPBR_infoBootGitHash m18 : 8|56@1+ (1,0) [0|7.20575940379e+16] "" Vector__XXX
 SG_ EPBR_infoPlatformType m19 : 8|8@1+ (1,0) [0|255] "" Vector__XXX
 SG_ EPBR_infoBootUdsProtoVersion m20 : 8|16@1+ (1,0) [0|65535] "" Vector__XXX
 SG_ EPBR_infoBootCrc m20 : 24|32@1+ (1,0) [0|4294967295] "" Vector__XXX

BO_ 552 EPBR_internalStatus: 8 EPBR
 SG_ EPBR_unitStatus : 0|5@1+ (1,0) [0|31] "" Vector__XXX
 SG_ EPBR_unitFaultStatus : 5|2@1+ (1,0) [0|3] "" Vector__XXX
 SG_ EPBR_summonState : 8|3@1+ (1,0) [0|7] "" Vector__XXX
 SG_ EPBR_disconnected : 11|1@1+ (1,0) [0|1] "" Vector__XXX
 SG_ EPBR_pistonTouchingRotor : 12|1@1+ (1,0) [0|1] "" Vector__XXX
 SG_ EPBR_csmFaultReason : 13|5@1+ (1,0) [0|31] "" Vector__XXX
 SG_ EPBR_esmOperationTrigger : 18|6@1+ (1,0) [0|63] "" Vector__XXX
 SG_ EPBR_summonFaultReason : 24|5@1+ (1,0) [0|31] "" Vector__XXX
 SG_ EPBR_localServiceModeActive : 29|1@1+ (1,0) [0|1] "" Vector__XXX
 SG_ EPBR_localCdpState : 30|2@1+ (1,0) [0|3] "" Vector__XXX
 SG_ EPBR_chimeRequestLocal : 33|3@1+ (1,0) [0|7] "" Vector__XXX
 SG_ EPBR_telltaleLocal : 39|3@1+ (1,0) [0|6] "" Vector__XXX
 SG_ EPBR_driverIsLeavingLocal : 42|1@1+ (1,0) [0|1] "" Vector__XXX
 SG_ EPBR_driverIsLeavingAnySpeedLoca : 43|1@1+ (1,0) [0|1] "" Vector__XXX
 SG_ EPBR_internalCDPRequest : 44|1@1+ (1,0) [0|1] "" Vector__XXX
 SG_ EPBR_esmSpeedClass : 45|3@1+ (1,0) [0|7] "" Vector__XXX
 SG_ EPBR_learnedEpbConfig : 48|4@1+ (1,0) [0|15] "" Vector__XXX
 SG_ EPBR_internalStatusCounter : 52|4@1+ (1,0) [0|15] "" Vector__XXX
 SG_ EPBR_internalStatusChecksum : 56|8@1+ (1,0) [0|255] "" Vector__XXX

BO_ 1662 EVSE_isoTpToVeh: 8 EVSE
 SG_ EVSE_isoTpToVehData : 0|64@1+ (1,0) [0|1.84467440737e+19] "" Vector__XXX

BO_ 1322 FC_alertLog: 8 FC
 SG_ FC_alertID M : 0|15@1+ (1,0) [0|32767] "" Vector__XXX
 SG_ FC_alertType : 15|1@1+ (1,0) [0|1] "" Vector__XXX
 SG_ FC_a130_CA_flybackSwOvType m130 : 16|1@1+ (1,0) [0|1] "" Vector__XXX
 SG_ FC_a146_CA_flybackOnTime m146 : 16|16@1+ (0.0007629511,0) [0|50.0000003385] "uS" Vector__XXX
 SG_ FC_a146_CA_flybackV m146 : 32|16@1+ (0.0128332730383,0) [0|841.028548565] "V" Vector__XXX
 SG_ FC_a146_CA_flybackTargetV m146 : 48|16@1+ (0.0128332730383,0) [0|841.028548565] "V" Vector__XXX
 SG_ FC_a159_CA_wdtTaskList1 m159 : 16|16@1+ (1,0) [0|65535] "" Vector__XXX
 SG_ FC_a159_CA_wdtTaskList2 m159 : 32|16@1+ (1,0) [0|65535] "" Vector__XXX

BO_ 895 FC_alertMatrix3: 8 FC
 SG_ FC_a129_CA_flyback_HW_OC : 0|1@1+ (1,0) [0|1] "" Vector__XXX
 SG_ FC_a130_CA_flyback_SW_OV : 1|1@1+ (1,0) [0|1] "" Vector__XXX
 SG_ FC_a131_CA_flyback_HW_OV : 2|1@1+ (1,0) [0|1] "" Vector__XXX
 SG_ FC_a132_CA_bmsMia : 3|1@1+ (1,0) [0|1] "" Vector__XXX
 SG_ FC_a133_CA_evseMia : 4|1@1+ (1,0) [0|1] "" Vector__XXX
 SG_ FC_a134_CA_vehTxBufOvf : 5|1@1+ (1,0) [0|1] "" Vector__XXX
 SG_ FC_a135_CA_vehRxBufOvf : 6|1@1+ (1,0) [0|1] "" Vector__XXX
 SG_ FC_a136_CA_evseTxBufOvf : 7|1@1+ (1,0) [0|1] "" Vector__XXX
 SG_ FC_a137_CA_evseRxBufOvf : 8|1@1+ (1,0) [0|1] "" Vector__XXX
 SG_ FC_a138_CA_hwProxTrip : 9|1@1+ (1,0) [0|1] "" Vector__XXX
 SG_ FC_a139_CA_ss2NotLow : 10|1@1+ (1,0) [0|1] "" Vector__XXX
 SG_ FC_a140_CA_bmsIncompatible : 11|1@1+ (1,0) [0|1] "" Vector__XXX
 SG_ FC_a141_CA_vehConn_OT : 12|1@1+ (1,0) [0|1] "" Vector__XXX
 SG_ FC_a142_CA_evseConn_OT : 13|1@1+ (1,0) [0|1] "" Vector__XXX
 SG_ FC_a143_CA_pcb_OT : 14|1@1+ (1,0) [0|1] "" Vector__XXX
 SG_ FC_a144_CA_flybackUnstable : 15|1@1+ (1,0) [0|1] "" Vector__XXX
 SG_ FC_a145_CA_flybackDataStale : 16|1@1+ (1,0) [0|1] "" Vector__XXX
 SG_ FC_a146_CA_flybackBusLoadHi : 17|1@1+ (1,0) [0|1] "" Vector__XXX
 SG_ FC_a147_CA_vehConn_UT : 18|1@1+ (1,0) [0|1] "" Vector__XXX
 SG_ FC_a148_CA_evseConn_UT : 19|1@1+ (1,0) [0|1] "" Vector__XXX
 SG_ FC_a149_CA_pcb_UT : 20|1@1+ (1,0) [0|1] "" Vector__XXX
 SG_ FC_a150_CA_vehToEvseDeltaHi : 21|1@1+ (1,0) [0|1] "" Vector__XXX
 SG_ FC_a151_CA_vehToEvseDeltaLo : 22|1@1+ (1,0) [0|1] "" Vector__XXX
 SG_ FC_a152_CA_vehToPcbDeltaHi : 23|1@1+ (1,0) [0|1] "" Vector__XXX
 SG_ FC_a153_CA_evseToPcbDeltaHi : 24|1@1+ (1,0) [0|1] "" Vector__XXX
 SG_ FC_a154_CA_vehToPcbDeltaLo : 25|1@1+ (1,0) [0|1] "" Vector__XXX
 SG_ FC_a155_CA_evseToPcbDeltaLo : 26|1@1+ (1,0) [0|1] "" Vector__XXX
 SG_ FC_a156_CA_flybackRunTimeout : 27|1@1+ (1,0) [0|1] "" Vector__XXX
 SG_ FC_a157_CA_unused : 28|1@1+ (1,0) [0|1] "" Vector__XXX
 SG_ FC_a158_CA_evseOverCurrent : 29|1@1+ (1,0) [0|1] "" Vector__XXX
 SG_ FC_a159_CA_wdtExpired : 30|1@1+ (1,0) [0|1] "" Vector__XXX
 SG_ FC_a160_CA_ss2Deasserted : 31|1@1+ (1,0) [0|1] "" Vector__XXX
 SG_ FC_a161_CA_vehTempHiFoldBk : 32|1@1+ (1,0) [0|1] "" Vector__XXX
 SG_ FC_a162_CA_evseTempHiFoldBk : 33|1@1+ (1,0) [0|1] "" Vector__XXX
 SG_ FC_a163_CA_pcbTempHiFoldBk : 34|1@1+ (1,0) [0|1] "" Vector__XXX
 SG_ FC_a164_CA_proxDisconnected : 35|1@1+ (1,0) [0|1] "" Vector__XXX
 SG_ FC_a165_CA_evseConnUnlocked : 36|1@1+ (1,0) [0|1] "" Vector__XXX
 SG_ FC_a166_CA_vehConnUnlocked : 37|1@1+ (1,0) [0|1] "" Vector__XXX
 SG_ FC_a167_CA_isoVoltageLow : 38|1@1+ (1,0) [0|1] "" Vector__XXX
 SG_ FC_a168_CA_proxTimeout : 39|1@1+ (1,0) [0|1] "" Vector__XXX
 SG_ FC_a169_CA_pilotAcceptTimeout : 40|1@1+ (1,0) [0|1] "" Vector__XXX
 SG_ FC_a170_CA_vehDataTimeout : 41|1@1+ (1,0) [0|1] "" Vector__XXX
 SG_ FC_a171_CA_vehConLockTimeout : 42|1@1+ (1,0) [0|1] "" Vector__XXX
 SG_ FC_a172_CA_ss2LowTimeout : 43|1@1+ (1,0) [0|1] "" Vector__XXX
 SG_ FC_a173_CA_evseDataTimeout : 44|1@1+ (1,0) [0|1] "" Vector__XXX
 SG_ FC_a174_CA_vehReadyTimeout : 45|1@1+ (1,0) [0|1] "" Vector__XXX
 SG_ FC_a175_CA_evseIsoTestTimeout : 46|1@1+ (1,0) [0|1] "" Vector__XXX
 SG_ FC_a176_CA_chargingBusTimeout : 47|1@1+ (1,0) [0|1] "" Vector__XXX
 SG_ FC_a177_CA_bmsCtrCloseTimeout : 48|1@1+ (1,0) [0|1] "" Vector__XXX
 SG_ FC_a178_CA_evseStartTimeout : 49|1@1+ (1,0) [0|1] "" Vector__XXX
 SG_ FC_a179_CA_startupProblem : 50|1@1+ (1,0) [0|1] "" Vector__XXX
 SG_ FC_a180_CA_chargingProblem : 51|1@1+ (1,0) [0|1] "" Vector__XXX
 SG_ FC_a181_CA_vRegBrownout : 52|1@1+ (1,0) [0|1] "" Vector__XXX
 SG_ FC_a182_CA_evseChrMalfunc : 53|1@1+ (1,0) [0|1] "" Vector__XXX
 SG_ FC_a183_CA_evseBatIncompat : 54|1@1+ (1,0) [0|1] "" Vector__XXX
 SG_ FC_a184_CA_evseBatMalfunc : 55|1@1+ (1,0) [0|1] "" Vector__XXX
 SG_ FC_a185_CA_vehReadyDeasserted : 56|1@1+ (1,0) [0|1] "" Vector__XXX
 SG_ FC_a186_CA_fcContOpenTimeout : 57|1@1+ (1,0) [0|1] "" Vector__XXX
 SG_ FC_a187_CA_evseConLockTimeout : 58|1@1+ (1,0) [0|1] "" Vector__XXX

BO_ 927 FC_alertMatrix4: 8 FC
 SG_ FC_a193_FCAlertPlaceholder : 0|1@1+ (1,0) [0|1] "" Vector__XXX

BO_ 958 FC_alertMatrix5: 8 FC
 SG_ FC_a257_GB_bmsMia : 0|1@1+ (1,0) [0|1] "" Vector__XXX
 SG_ FC_a258_GB_evseMia : 1|1@1+ (1,0) [0|1] "" Vector__XXX
 SG_ FC_a259_GB_vehTxBufOvf : 2|1@1+ (1,0) [0|1] "" Vector__XXX
 SG_ FC_a260_GB_vehRxBufOvf : 3|1@1+ (1,0) [0|1] "" Vector__XXX
 SG_ FC_a261_GB_evseTxBufOvf : 4|1@1+ (1,0) [0|1] "" Vector__XXX
 SG_ FC_a262_GB_evseRxBufOvf : 5|1@1+ (1,0) [0|1] "" Vector__XXX
 SG_ FC_a263_GB_hwProxTrip : 6|1@1+ (1,0) [0|1] "" Vector__XXX
 SG_ FC_a264_GB_timeoutCHM : 7|1@1+ (1,0) [0|1] "" Vector__XXX
 SG_ FC_a265_GB_bmsIncompatible : 8|1@1+ (1,0) [0|1] "" Vector__XXX
 SG_ FC_a266_GB_negPin_OT : 9|1@1+ (1,0) [0|1] "" Vector__XXX
 SG_ FC_a267_GB_posPin_OT : 10|1@1+ (1,0) [0|1] "" Vector__XXX
 SG_ FC_a268_GB_pcb_OT : 11|1@1+ (1,0) [0|1] "" Vector__XXX
 SG_ FC_a269_GB_timeoutCRM : 12|1@1+ (1,0) [0|1] "" Vector__XXX
 SG_ FC_a270_GB_timeoutCML : 13|1@1+ (1,0) [0|1] "" Vector__XXX
 SG_ FC_a271_GB_timeoutCRO : 14|1@1+ (1,0) [0|1] "" Vector__XXX
 SG_ FC_a272_GB_negToPosDeltaHi : 15|1@1+ (1,0) [0|1] "" Vector__XXX
 SG_ FC_a273_GB_negToPosDeltaLo : 16|1@1+ (1,0) [0|1] "" Vector__XXX
 SG_ FC_a274_GB_negToPcbDeltaHi : 17|1@1+ (1,0) [0|1] "" Vector__XXX
 SG_ FC_a275_GB_posToPcbDeltaHi : 18|1@1+ (1,0) [0|1] "" Vector__XXX
 SG_ FC_a276_GB_negToPcbDeltaLo : 19|1@1+ (1,0) [0|1] "" Vector__XXX
 SG_ FC_a277_GB_posToPcbDeltaLo : 20|1@1+ (1,0) [0|1] "" Vector__XXX
 SG_ FC_a278_GB_timeoutCCS : 21|1@1+ (1,0) [0|1] "" Vector__XXX
 SG_ FC_a279_GB_evseOverCurrent : 22|1@1+ (1,0) [0|1] "" Vector__XXX
 SG_ FC_a280_GB_retryLimitExceeded : 23|1@1+ (1,0) [0|1] "" Vector__XXX
 SG_ FC_a281_GB_evseOutOfService : 24|1@1+ (1,0) [0|1] "" Vector__XXX
 SG_ FC_a282_GB_negTempHiFoldBk : 25|1@1+ (1,0) [0|1] "" Vector__XXX
 SG_ FC_a283_GB_posTempHiFoldBk : 26|1@1+ (1,0) [0|1] "" Vector__XXX
 SG_ FC_a284_GB_pcbTempHiFoldBk : 27|1@1+ (1,0) [0|1] "" Vector__XXX
 SG_ FC_a285_GB_proxDisconnected : 28|1@1+ (1,0) [0|1] "" Vector__XXX
 SG_ FC_a286_GB_evseConnUnlocked : 29|1@1+ (1,0) [0|1] "" Vector__XXX
 SG_ FC_a287_GB_vehConnUnlocked : 30|1@1+ (1,0) [0|1] "" Vector__XXX
 SG_ FC_a288_GB_evseAbnormalStopReq : 31|1@1+ (1,0) [0|1] "" Vector__XXX
 SG_ FC_a289_GB_proxTimeout : 32|1@1+ (1,0) [0|1] "" Vector__XXX
 SG_ FC_a290_GB_pilotAcceptTimeout : 33|1@1+ (1,0) [0|1] "" Vector__XXX
 SG_ FC_a291_GB_vehDataTimeout : 34|1@1+ (1,0) [0|1] "" Vector__XXX
 SG_ FC_a292_GB_vehConLockTimeout : 35|1@1+ (1,0) [0|1] "" Vector__XXX
 SG_ FC_a293_GB_proxRationality : 36|1@1+ (1,0) [0|1] "" Vector__XXX
 SG_ FC_a294_GB_unused : 37|1@1+ (1,0) [0|1] "" Vector__XXX
 SG_ FC_a295_GB_pilotRationality : 38|1@1+ (1,0) [0|1] "" Vector__XXX
 SG_ FC_a296_GB_invalidPilotTransitio : 39|1@1+ (1,0) [0|1] "" Vector__XXX
 SG_ FC_a297_GB_unused : 40|1@1+ (1,0) [0|1] "" Vector__XXX
 SG_ FC_a298_GB_bmsCtrCloseTimeout : 41|1@1+ (1,0) [0|1] "" Vector__XXX
 SG_ FC_a299_GB_evseReadyTimeout : 42|1@1+ (1,0) [0|1] "" Vector__XXX
 SG_ FC_a300_GB_unused : 43|1@1+ (1,0) [0|1] "" Vector__XXX
 SG_ FC_a301_GB_unused : 44|1@1+ (1,0) [0|1] "" Vector__XXX
 SG_ FC_a302_GB_unused : 45|1@1+ (1,0) [0|1] "" Vector__XXX
 SG_ FC_a303_GB_negRecogTimeout : 46|1@1+ (1,0) [0|1] "" Vector__XXX
 SG_ FC_a304_GB_unused : 47|1@1+ (1,0) [0|1] "" Vector__XXX
 SG_ FC_a305_GB_posRecogTimeout : 48|1@1+ (1,0) [0|1] "" Vector__XXX
 SG_ FC_a306_GB_vehReadyDeasserted : 49|1@1+ (1,0) [0|1] "" Vector__XXX
 SG_ FC_a307_GB_fcContOpenTimeout : 50|1@1+ (1,0) [0|1] "" Vector__XXX
 SG_ FC_a308_GB_evseConLockTimeout : 51|1@1+ (1,0) [0|1] "" Vector__XXX
 SG_ FC_a309_GB_unused : 52|1@1+ (1,0) [0|1] "" Vector__XXX
 SG_ FC_a310_GB_unused : 53|1@1+ (1,0) [0|1] "" Vector__XXX
 SG_ FC_a311_GB_battParamsTimeout : 54|1@1+ (1,0) [0|1] "" Vector__XXX
 SG_ FC_a312_GB_evseLimitsTimeout : 55|1@1+ (1,0) [0|1] "" Vector__XXX
 SG_ FC_a313_GB_inputVoltageRailOv : 56|1@1+ (1,0) [0|1] "" Vector__XXX

BO_ 990 FC_alertMatrix6: 8 FC
 SG_ FC_a321_FCAlertPlaceholder : 0|1@1+ (1,0) [0|1] "" Vector__XXX

BO_ 1117 FC_evseBilling: 8 FC
 SG_ FC_evseBillingDataSelect M : 0|1@1+ (1,0) [0|1] "" Vector__XXX
 SG_ FC_evseBillingEnergy m0 : 4|20@1+ (0.001,0) [0|1048.575] "kWh" Vector__XXX
 SG_ FC_evseMeterPower m0 : 24|20@1+ (0.001,0) [0|1048.575] "kW" Vector__XXX
 SG_ FC_evseMeterCurrent m0 : 44|10@1+ (1,0) [0|1023] "A" Vector__XXX
 SG_ FC_evseMeterVoltage m0 : 54|10@1+ (1,0) [0|1023] "V" Vector__XXX
 SG_ FC_evseMeterFwGitHash m1 : 4|56@1+ (1,0) [0|7.20575940379e+16] "" Vector__XXX

BO_ 1334 FC_evseBilling2: 8 FC
 SG_ FC_evseBilling2DataSelect M : 0|4@1+ (1,0) [0|15] "" Vector__XXX
 SG_ FC_evsePpuEnabled m0 : 4|1@1+ (1,0) [0|1] "" Vector__XXX
 SG_ FC_evseBillingEnergyHighRes m0 : 8|24@1+ (0.0001,0) [0|1677.7214] "kWh" Vector__XXX

BO_ 1303 FC_identifier: 8 FC
 SG_ FC_id : 0|32@1+ (1,0) [0|4294967295] "" Vector__XXX
 SG_ FC_sessionId : 32|32@1+ (1,0) [0|4294967295] "" Vector__XXX

BO_ 1310 FC_info: 8 FC
 SG_ FC_infoIndex M : 0|8@1+ (1,0) [0|255] "" Vector__XXX
 SG_ FC_infoBuildType m10 : 8|8@1+ (1,0) [0|255] "" Vector__XXX
 SG_ FC_infoBuildConfigID m10 : 16|16@1+ (1,0) [0|65535] "" Vector__XXX
 SG_ FC_infoHardwareID m10 : 32|16@1+ (1,0) [0|65535] "" Vector__XXX
 SG_ FC_infoComponentID m10 : 48|16@1+ (1,0) [0|65535] "" Vector__XXX
 SG_ FC_infoPcbaID m11 : 16|8@1+ (1,0) [0|255] "" Vector__XXX
 SG_ FC_infoAssemblyID m11 : 24|8@1+ (1,0) [0|255] "" Vector__XXX
 SG_ FC_infoUsageID m11 : 32|16@1+ (1,0) [0|65535] "" Vector__XXX
 SG_ FC_infoSubUsageID m11 : 48|16@1+ (1,0) [0|65535] "" Vector__XXX
 SG_ FC_infoApplicationCRC m13 : 32|32@1+ (1,0) [0|4294967295] "" Vector__XXX
 SG_ FC_infoAppGitHashBytes m17 : 8|56@1+ (1,0) [0|7.20575940379e+16] "" Vector__XXX
 SG_ FC_infoBootGitHashBytes m18 : 8|56@1+ (1,0) [0|7.20575940379e+16] "" Vector__XXX
 SG_ FC_infoPlatformType m19 : 8|8@1+ (1,0) [0|255] "" Vector__XXX
 SG_ FC_infoMajorVersion m19 : 16|8@1+ (1,0) [0|255] "" Vector__XXX
 SG_ FC_infoBranchOrigin m19 : 24|8@1+ (1,0) [0|255] "" Vector__XXX
 SG_ FC_infoMaturity m19 : 32|8@1+ (1,0) [0|255] "" Vector__XXX
 SG_ FC_infoHardwareRevision m19 : 40|8@1+ (1,0) [0|255] "" Vector__XXX
 SG_ FC_partNumChar01 m25 : 8|8@1+ (1,0) [0|255] "" Vector__XXX
 SG_ FC_partNumChar02 m25 : 16|8@1+ (1,0) [0|255] "" Vector__XXX
 SG_ FC_partNumChar03 m25 : 24|8@1+ (1,0) [0|255] "" Vector__XXX
 SG_ FC_partNumChar04 m25 : 32|8@1+ (1,0) [0|255] "" Vector__XXX
 SG_ FC_partNumChar05 m25 : 40|8@1+ (1,0) [0|255] "" Vector__XXX
 SG_ FC_partNumChar06 m25 : 48|8@1+ (1,0) [0|255] "" Vector__XXX
 SG_ FC_partNumChar07 m25 : 56|8@1+ (1,0) [0|255] "" Vector__XXX
 SG_ FC_partNumChar08 m26 : 8|8@1+ (1,0) [0|255] "" Vector__XXX
 SG_ FC_partNumChar09 m26 : 16|8@1+ (1,0) [0|255] "" Vector__XXX
 SG_ FC_partNumChar10 m26 : 24|8@1+ (1,0) [0|255] "" Vector__XXX
 SG_ FC_partNumChar11 m26 : 32|8@1+ (1,0) [0|255] "" Vector__XXX
 SG_ FC_partNumChar12 m26 : 40|8@1+ (1,0) [0|255] "" Vector__XXX
 SG_ FC_partNumChar13 m26 : 48|8@1+ (1,0) [0|255] "" Vector__XXX
 SG_ FC_partNumChar14 m26 : 56|8@1+ (1,0) [0|255] "" Vector__XXX
 SG_ FC_partNumChar15 m27 : 8|8@1+ (1,0) [0|255] "" Vector__XXX
 SG_ FC_partNumChar16 m27 : 16|8@1+ (1,0) [0|255] "" Vector__XXX
 SG_ FC_partNumChar17 m27 : 24|8@1+ (1,0) [0|255] "" Vector__XXX
 SG_ FC_partNumChar18 m27 : 32|8@1+ (1,0) [0|255] "" Vector__XXX
 SG_ FC_partNumChar19 m27 : 40|8@1+ (1,0) [0|255] "" Vector__XXX
 SG_ FC_partNumChar20 m27 : 48|8@1+ (1,0) [0|255] "" Vector__XXX

BO_ 580 FC_limits: 8 FC
 SG_ FC_powerLimit : 0|13@1+ (0.06225586,0) [0|509.8754934] "kW" Vector__XXX
 SG_ FC_currentLimit : 16|13@1+ (0.07324219,0) [0|599.8535361] "A" Vector__XXX
 SG_ FC_maxVoltageLimit : 32|13@1+ (0.07324219,0) [0|599.8535361] "V" Vector__XXX
 SG_ FC_minVoltageLimit : 48|13@1+ (0.07324219,0) [0|599.8535361] "V" Vector__XXX

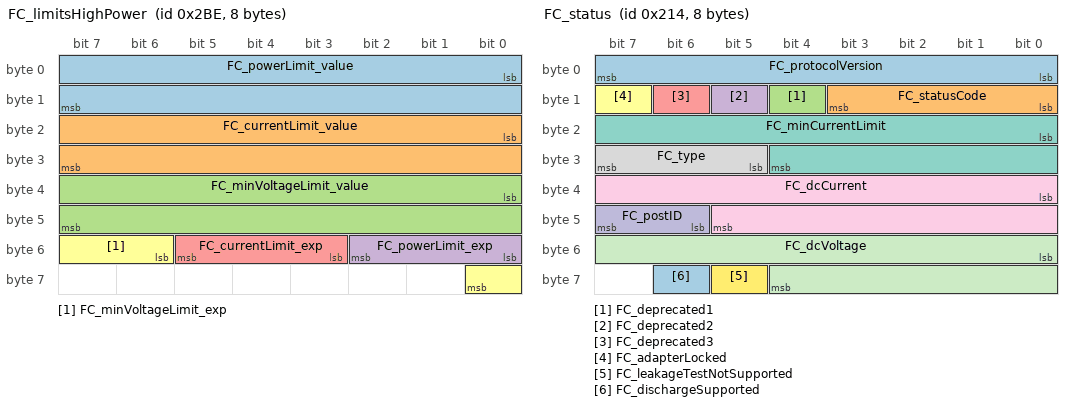
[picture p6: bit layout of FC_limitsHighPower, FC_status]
BO_ 702 FC_limitsHighPower: 8 FC
 SG_ FC_powerLimit_value : 0|16@1- (1,0) [-32767|32767] "*10^exp kW" Vector__XXX
 SG_ FC_currentLimit_value : 16|16@1- (1,0) [-32767|32767] "*10^exp A" Vector__XXX
 SG_ FC_minVoltageLimit_value : 32|16@1- (1,0) [-32767|32767] "*10^exp V" Vector__XXX
 SG_ FC_powerLimit_exp : 48|3@1- (1,0) [-4|3] "" Vector__XXX
 SG_ FC_currentLimit_exp : 51|3@1- (1,0) [-4|3] "" Vector__XXX
 SG_ FC_minVoltageLimit_exp : 54|3@1- (1,0) [-4|3] "" Vector__XXX

BO_ 1345 FC_maxLimits: 8 FC
 SG_ FC_maxPowerLimit : 0|13@1+ (0.06225586,0) [0|509.8754934] "kW" Vector__XXX
 SG_ FC_maxCurrentLimit : 16|13@1+ (0.07324219,0) [0|599.8535361] "A" Vector__XXX

BO_ 1300 FC_serial: 8 FC
 SG_ FC_serialDataSelect M : 0|7@1+ (1,0) [0|127] "" Vector__XXX
 SG_ FC_serialChar01 m0 : 8|8@1+ (1,0) [0|255] "" Vector__XXX
 SG_ FC_serialChar02 m0 : 16|8@1+ (1,0) [0|255] "" Vector__XXX
 SG_ FC_serialChar03 m0 : 24|8@1+ (1,0) [0|255] "" Vector__XXX
 SG_ FC_serialChar04 m0 : 32|8@1+ (1,0) [0|255] "" Vector__XXX
 SG_ FC_serialChar05 m0 : 40|8@1+ (1,0) [0|255] "" Vector__XXX
 SG_ FC_serialChar06 m0 : 48|8@1+ (1,0) [0|255] "" Vector__XXX
 SG_ FC_serialChar07 m0 : 56|8@1+ (1,0) [0|255] "" Vector__XXX
 SG_ FC_serialChar08 m1 : 8|8@1+ (1,0) [0|255] "" Vector__XXX
 SG_ FC_serialChar09 m1 : 16|8@1+ (1,0) [0|255] "" Vector__XXX
 SG_ FC_serialChar10 m1 : 24|8@1+ (1,0) [0|255] "" Vector__XXX
 SG_ FC_serialChar11 m1 : 32|8@1+ (1,0) [0|255] "" Vector__XXX
 SG_ FC_serialChar12 m1 : 40|8@1+ (1,0) [0|255] "" Vector__XXX
 SG_ FC_serialChar13 m1 : 48|8@1+ (1,0) [0|255] "" Vector__XXX
 SG_ FC_serialChar14 m1 : 56|8@1+ (1,0) [0|255] "" Vector__XXX
 SG_ FC_serialChar15 m2 : 8|8@1+ (1,0) [0|255] "" Vector__XXX
 SG_ FC_serialChar16 m2 : 16|8@1+ (1,0) [0|255] "" Vector__XXX
 SG_ FC_serialChar17 m2 : 24|8@1+ (1,0) [0|255] "" Vector__XXX

BO_ 532 FC_status: 8 FC
 SG_ FC_protocolVersion : 0|8@1+ (1,0) [0|255] "" Vector__XXX
 SG_ FC_statusCode : 8|4@1+ (1,0) [1|15] "" Vector__XXX
 SG_ FC_deprecated1 : 12|1@1+ (1,0) [0|1] "" Vector__XXX
 SG_ FC_deprecated2 : 13|1@1+ (1,0) [0|1] "" Vector__XXX
 SG_ FC_deprecated3 : 14|1@1+ (1,0) [0|1] "" Vector__XXX
 SG_ FC_adapterLocked : 15|1@1+ (1,0) [0|1] "" Vector__XXX
 SG_ FC_minCurrentLimit : 16|13@1+ (0.1,0) [0|600] "A" Vector__XXX
 SG_ FC_type : 29|3@1+ (1,0) [0|6] "" Vector__XXX
 SG_ FC_dcCurrent : 32|14@1- (0.07324219,0) [-600|599.92675781] "A" Vector__XXX
 SG_ FC_postID : 46|2@1+ (1,0) [0|2] "" Vector__XXX
 SG_ FC_dcVoltage : 48|13@1+ (0.07324219,0) [0|599.92675822] "V" Vector__XXX
 SG_ FC_leakageTestNotSupported : 61|1@1+ (1,0) [0|1] "" Vector__XXX
 SG_ FC_dischargeSupported : 62|1@1+ (1,0) [0|1] "" Vector__XXX

BO_ 533 FC_status2: 1 FC
 SG_ FC_externalIsolationResistance : 0|8@1+ (40,0) [0|10160] "kOhm" Vector__XXX

BO_ 535 FC_status3: 8 FC
 SG_ FC_status3DataSelect M : 0|7@1+ (1,0) [0|127] "" Vector__XXX
 SG_ FC_status3DummySig : 7|1@1+ (1,0) [0|1] "" Vector__XXX
 SG_ FC_class m0 : 8|8@1+ (1,0) [1|255] "" Vector__XXX
 SG_ FC_brand m0 : 16|4@1+ (1,0) [1|15] "" Vector__XXX
 SG_ FC_coolingType m0 : 20|4@1+ (1,0) [1|15] "" Vector__XXX
 SG_ FC_uiStopType m0 : 24|4@1+ (1,0) [1|15] "" Vector__XXX
 SG_ FC_emergencyShutdownSupported m0 : 28|1@1+ (1,0) [0|1] "" Vector__XXX
 SG_ FC_generation m0 : 32|8@1+ (1,0) [1|255] "" Vector__XXX

BO_ 1650 HCML_info: 8 HCML
 SG_ VC_hcmlInfoIndex M : 0|4@1+ (1,0) [0|15] "" Vector__XXX
 SG_ VC_infoHCMLBuildConfigId m0 : 8|16@1+ (1,0) [0|65535] "" Vector__XXX
 SG_ VC_leftHeadlampLMMVariant m0 : 24|2@1+ (1,0) [1|3] "" Vector__XXX
 SG_ VC_infoHCMLAssemblyId m1 : 8|16@1+ (1,0) [0|65535] "" Vector__XXX
 SG_ VC_infoHCMLPcbaId m1 : 24|16@1+ (1,0) [0|65535] "" Vector__XXX
 SG_ VC_infoHCMLUsageId m1 : 40|16@1+ (1,0) [0|65535] "" Vector__XXX

BO_ 1980 HCMR_info: 8 HCMR
 SG_ VC_hcmrInfoIndex M : 0|4@1+ (1,0) [0|15] "" Vector__XXX
 SG_ VC_infoHCMRBuildConfigId m0 : 8|16@1+ (1,0) [0|65535] "" Vector__XXX
 SG_ VC_rightHeadlampLMMVariant m0 : 24|2@1+ (1,0) [1|3] "" Vector__XXX
 SG_ VC_infoHCMRAssemblyId m1 : 8|16@1+ (1,0) [0|65535] "" Vector__XXX
 SG_ VC_infoHCMRPcbaId m1 : 24|16@1+ (1,0) [0|65535] "" Vector__XXX
 SG_ VC_infoHCMRUsageId m1 : 40|16@1+ (1,0) [0|65535] "" Vector__XXX

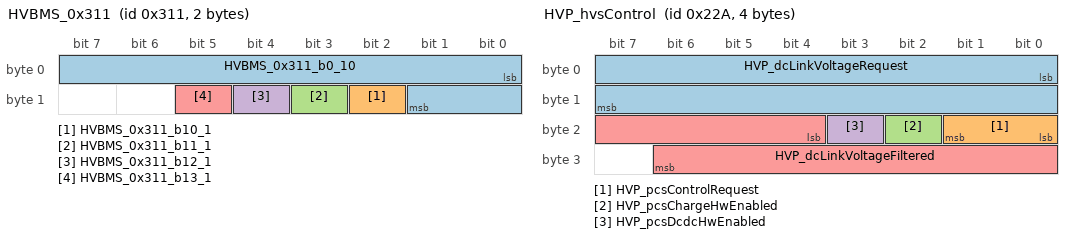
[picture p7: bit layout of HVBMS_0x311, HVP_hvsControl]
BO_ 785 HVBMS_0x311: 2 Vector__XXX
 SG_ HVBMS_0x311_b0_10 : 0|10@1+ (1,0) [0|1023] "" Vector__XXX
 SG_ HVBMS_0x311_b10_1 : 10|1@1+ (1,0) [0|1] "" Vector__XXX
 SG_ HVBMS_0x311_b11_1 : 11|1@1+ (1,0) [0|1] "" Vector__XXX
 SG_ HVBMS_0x311_b12_1 : 12|1@1+ (1,0) [0|1] "" Vector__XXX
 SG_ HVBMS_0x311_b13_1 : 13|1@1+ (1,0) [0|1] "" Vector__XXX

BO_ 1106 HVBMS_0x452: 3 Vector__XXX
 SG_ HVBMS_0x452_b0_10 : 0|10@1+ (1,0) [0|1023] "" Vector__XXX

BO_ 554 HVP_hvsControl: 4 HVP
 SG_ HVP_dcLinkVoltageRequest : 0|16@1- (0.1,0) [-550|550] "V" Vector__XXX
 SG_ HVP_pcsControlRequest : 16|2@1+ (1,0) [0|3] "" Vector__XXX
 SG_ HVP_pcsChargeHwEnabled : 18|1@1+ (1,0) [0|1] "" Vector__XXX
 SG_ HVP_pcsDcdcHwEnabled : 19|1@1+ (1,0) [0|1] "" Vector__XXX
 SG_ HVP_dcLinkVoltageFiltered : 20|11@1- (1,0) [-550|550] "V" Vector__XXX

BO_ 784 HVP_info: 8 HVP
 SG_ HVP_infoIndex M : 0|8@1+ (1,0) [0|255] "" Vector__XXX
 SG_ HVP_buildType m10 : 8|3@1+ (1,0) [0|7] "" Vector__XXX
 SG_ HVP_buildConfigId m10 : 16|16@1+ (1,0) [0|65535] "" Vector__XXX
 SG_ HVP_hardwareId m10 : 32|16@1+ (1,0) [0|65535] "" Vector__XXX
 SG_ HVP_componentId m10 : 48|16@1+ (1,0) [0|65535] "" Vector__XXX
 SG_ HVP_pcbaId m11 : 16|8@1+ (1,0) [0|255] "" Vector__XXX
 SG_ HVP_assemblyId m11 : 24|8@1+ (1,0) [0|255] "" Vector__XXX
 SG_ HVP_usageId m11 : 32|16@1+ (1,0) [0|65535] "" Vector__XXX
 SG_ HVP_subUsageId m11 : 48|16@1+ (1,0) [0|65535] "" Vector__XXX
 SG_ HVP_platformType m13 : 8|8@1+ (1,0) [0|255] "" Vector__XXX
 SG_ HVP_appCrc m13 : 32|32@1+ (1,0) [0|4294967295] "" Vector__XXX
 SG_ HVP_appGitHash m17 : 8|56@1+ (1,0) [0|7.20575940379e+16] "" Vector__XXX
 SG_ HVP_bootGitHash m18 : 8|56@1+ (1,0) [0|7.20575940379e+16] "" Vector__XXX
 SG_ HVP_bootUdsProtoVersion m20 : 8|8@1+ (1,0) [0|255] "" Vector__XXX
 SG_ HVP_bootCrc m20 : 32|32@1+ (1,0) [0|4294967295] "" Vector__XXX

BO_ 1914 HVP_log1hz: 8 HVP
 SG_ HVP_log1HzIndex M : 0|3@1+ (1,0) [0|7] "" Vector__XXX
 SG_ HVP_bmbAsicType m0 : 3|2@1+ (1,0) [0|3] "" Vector__XXX
 SG_ HVP_shuntCurrentAuxLog m0 : 8|24@1- (0.001,0) [-8388.607|8388.607] "A" Vector__XXX
 SG_ HVP_pyroSquibResistance m0 : 32|16@1+ (0.001,0) [0|65.534] "Ohm" Vector__XXX
 SG_ HVP_shuntAsicChipXCoordinate m0 : 48|8@1+ (1,0) [0|255] "" Vector__XXX
 SG_ HVP_shuntAsicChipYCoordinate m0 : 56|8@1+ (1,0) [0|255] "" Vector__XXX
 SG_ HVP_hvilCalType m1 : 3|2@1+ (1,0) [0|3] "" Vector__XXX
 SG_ HVP_gpioPcsDcdcPwmEnable m1 : 5|1@1+ (1,0) [0|1] "" Vector__XXX
 SG_ HVP_gpioPcsChargePwmEnable m1 : 6|1@1+ (1,0) [0|1] "" Vector__XXX
 SG_ HVP_gpioPcsEnable m1 : 7|1@1+ (1,0) [0|1] "" Vector__XXX
 SG_ HVP_shuntAsicChipWaferNumber m1 : 8|8@1+ (1,0) [0|255] "" Vector__XXX
 SG_ HVP_energyReserveMin m1 : 16|16@1- (0.001,0) [-32.768|32.767] "V" Vector__XXX
 SG_ HVP_energyReserveMax m1 : 32|16@1- (0.001,0) [-32.768|32.767] "V" Vector__XXX
 SG_ HVP_energyReserveAvg m1 : 48|16@1- (0.001,0) [-32.768|32.767] "V" Vector__XXX

BO_ 941 ICR_info: 8 ICR
 SG_ ICR_infoIndex M : 0|8@1+ (1,0) [0|255] "" Vector__XXX
 SG_ ICR_infoBuildType m10 : 8|3@1+ (1,0) [0|7] "" Vector__XXX
 SG_ ICR_infoPcbaId m11 : 32|8@1+ (1,0) [0|255] "" Vector__XXX
 SG_ ICR_infoAssemblyId m11 : 40|8@1+ (1,0) [0|255] "" Vector__XXX
 SG_ ICR_infoUsageId m11 : 48|16@1+ (1,0) [0|65535] "" Vector__XXX
 SG_ ICR_infoAppCrc m13 : 8|32@1+ (1,0) [0|4294967295] "" Vector__XXX
 SG_ ICR_infoBoardPartNumber17 m25 : 8|56@1+ (1,0) [0|7.20575940379e+16] "" Vector__XXX
 SG_ ICR_infoBoardPartNumber814 m26 : 8|56@1+ (1,0) [0|7.20575940379e+16] "" Vector__XXX
 SG_ ICR_infoBoardPartNumber1520 m27 : 8|48@1+ (1,0) [0|281474976710655] "" Vector__XXX

BO_TX_BU_ 818 : BMS;
BO_TX_BU_ 722 : BMS;
BO_TX_BU_ 850 : BMS;
BO_TX_BU_ 768 : BMS;
BO_TX_BU_ 978 : BMS;
BO_TX_BU_ 1010 : BMS;
BO_TX_BU_ 1170 : BMS;
BO_TX_BU_ 1116 : CC;
BO_TX_BU_ 1132 : CC;
BO_TX_BU_ 796 : CC;
BO_TX_BU_ 812 : CC;
BO_TX_BU_ 870 : CMPD;
BO_TX_BU_ 679 : CMPD;
BO_TX_BU_ 867 : CMP;
BO_TX_BU_ 1767 : CP;
BO_TX_BU_ 1342 : CP;
BO_TX_BU_ 1001 : DAS;
BO_TX_BU_ 741 : DIF;
BO_TX_BU_ 1367 : DIF;
BO_TX_BU_ 2005 : DIR;
BO_TX_BU_ 917 : DIR;
BO_TX_BU_ 614 : DIR;
BO_TX_BU_ 1495 : DIR;
BO_TX_BU_ 2007 : DI;
BO_TX_BU_ 616 : DI;
BO_TX_BU_ 1992 : EPBL;
BO_TX_BU_ 648 : EPBL;
BO_TX_BU_ 743 : EPBL;
BO_TX_BU_ 2024 : EPBR;
BO_TX_BU_ 552 : EPBR;
BO_TX_BU_ 1662 : EVSE;
BO_TX_BU_ 1322 : FC;
BO_TX_BU_ 895 : FC;
BO_TX_BU_ 927 : FC;
BO_TX_BU_ 958 : FC;
BO_TX_BU_ 990 : FC;
BO_TX_BU_ 1117 : FC;
BO_TX_BU_ 1334 : FC;
BO_TX_BU_ 1303 : FC;
BO_TX_BU_ 1310 : FC;
BO_TX_BU_ 580 : FC;
BO_TX_BU_ 702 : FC;
BO_TX_BU_ 1345 : FC;
BO_TX_BU_ 1300 : FC;
BO_TX_BU_ 532 : FC;
BO_TX_BU_ 533 : FC;
BO_TX_BU_ 535 : FC;
BO_TX_BU_ 1650 : HCML;
BO_TX_BU_ 1980 : HCMR;
BO_TX_BU_ 554 : HVP;
BO_TX_BU_ 784 : HVP;
BO_TX_BU_ 1914 : HVP;
BO_TX_BU_ 941 : ICR;

CM_ "Tesla Model 3 / Model Y CAN bus database; bus VEH (vehicle CAN); firmware 2025.20.8. Decoded CAN signal definitions (layout, scaling, units, value tables).";
CM_ BU_ BMS "High-voltage battery management system";
CM_ BU_ CC "Charge cable controller";
CM_ BU_ CMP "A/C compressor";
CM_ BU_ CMPD "CMPD ECU";
CM_ BU_ CP "Charge port controller";
CM_ BU_ DAS "Driver assistance computer";
CM_ BU_ DI "Drive inverter";
CM_ BU_ DIF "Front drive inverter";
CM_ BU_ DIR "Rear drive inverter";
CM_ BU_ EPBL "Left electric parking brake";
CM_ BU_ EPBR "Right electric parking brake";
CM_ BU_ EVSE "EVSE ECU";
CM_ BU_ FC "FC ECU";
CM_ BU_ GTW "Gateway";
CM_ BU_ HCML "HCML ECU";
CM_ BU_ HCMR "HCMR ECU";
CM_ BU_ HVP "High-voltage processor (pack contactor and isolation controller)";
CM_ BU_ ICR "ICR ECU";
CM_ BU_ PCS "Power conversion system (on-board charger and DC-DC converter)";
CM_ BU_ PM "PM ECU";
CM_ BU_ PMF "PMF ECU";
CM_ BU_ PMR "PMR ECU";
CM_ BU_ PTC "Cabin heater";
CM_ BU_ SCCM "Steering column control module";
CM_ BU_ SCM "SCM ECU";
CM_ BU_ SCS "SCS ECU";
CM_ BU_ SDCR "SDCR ECU";
CM_ BU_ TAS "Air suspension controller";
CM_ BU_ UMC "UMC ECU";
CM_ BU_ VC "VC ECU";
CM_ BU_ VCFRONT "Front body controller";
CM_ BU_ VCLEFT "Left body controller";
CM_ BU_ VCRIGHT "Right body controller";
CM_ BU_ VCSEC "Vehicle security controller";
CM_ BO_ 818 "High-voltage battery management system message: bmb min max; frame length observed on a vehicle bus";
CM_ SG_ 818 BMS_bmbMinMaxMultiplexer "High-voltage battery management system: bmb min max multiplexer";
CM_ SG_ 818 BMS_thermistorNumTMin "BMB module number with minimum temperature.";
CM_ SG_ 818 BMS_thermistorNumTMax "BMB module number with maximum temperature.";
CM_ SG_ 818 BMS_thermistorTMax "Max temperature of all valid filtered thermistors";
CM_ SG_ 818 BMS_thermistorTMin "Min temperature of all valid filtered thermistors";
CM_ SG_ 818 BMS_thermistorTAvg "Average temperature of all valid filtered thermistors";
CM_ SG_ 818 BMS_brickVoltageMax "Brick voltage maximum.";
CM_ SG_ 818 BMS_brickVoltageMin "Brick voltage minimum.";
CM_ SG_ 818 BMS_brickNumVoltageMax "Brick number with maximum voltage (1 indexed)";
CM_ SG_ 818 BMS_brickNumVoltageMin "Brick number with minimum voltage (1 indexed)";
CM_ BO_ 722 "High-voltage battery management system message: drive limits; frame length observed on a vehicle bus";
CM_ SG_ 722 BMS_minBusVoltage "Calculated min bus voltage limit";
CM_ SG_ 722 BMS_maxBusVoltage "Calculated max bus voltage limit for the pack";
CM_ SG_ 722 BMS_maxChargeCurrent "Calculated max charge current limit for the pack";
CM_ SG_ 722 BMS_maxDischargeCurrent "Calculated max discharge current limit for the pack";
CM_ BO_ 850 "High-voltage battery management system message: energy status; frame length observed on a vehicle bus";
CM_ SG_ 850 BMS_energyStatusMultiplexer "High-voltage battery management system: energy status multiplexer";
CM_ SG_ 850 BMS_nominalFullPackEnergy "Full pack energy based on calculated pack energy from the full pack discharge energy walk; raw 65535 = signal not available (SNA)";
CM_ SG_ 850 BMS_nominalEnergyRemaining "Nominal energy remaining based on calculated pack energy from the nominal discharge energy walk; raw 65535 = signal not available (SNA)";
CM_ SG_ 850 BMS_idealEnergyRemaining "Ideal energy remaining based on calculated pack energy from ideal discharge energy walk; raw 65535 = signal not available (SNA)";
CM_ SG_ 850 BMS_fullChargeComplete "Indicates BMS is fully charged";
CM_ SG_ 850 BMS_energyBuffer "Rough indication of confidence in the energy estimation; raw 65535 = signal not available (SNA)";
CM_ SG_ 850 BMS_expectedEnergyRemaining "High-voltage battery management system: expected energy remaining; raw 65535 = signal not available (SNA)";
CM_ SG_ 850 BMS_energyToChargeComplete "Calculated energy required to reach charge complete; raw 65535 = signal not available (SNA)";
CM_ SG_ 850 BMS_energyRemainingDisplay "Rubber-banding energy remaining to be used for the UI facing miles remaining display; raw 65535 = signal not available (SNA)";
CM_ SG_ 850 BMS_energyRemainingTDisplay "Rubber-banding energy remaining to be used for the UI facing miles remaining display; raw 65535 = signal not available (SNA)";
CM_ SG_ 850 BMS_energyDisplayErrorBlendRate "Rubber-banding blend rate to be used to ensure consistency between the gauge display and UI energy algorithms";
CM_ SG_ 850 BMS_userFacingSoe "User facing state of energy; raw 2047 = signal not available (SNA)";
CM_ BO_ 768 "High-voltage battery management system message: info; frame length observed on a vehicle bus";
CM_ SG_ 768 BMS_infoIndex "High-voltage battery management system: info index";
CM_ SG_ 768 BMS_buildType "High-voltage battery management system: build type";
CM_ SG_ 768 BMS_buildConfigId "High-voltage battery management system: build config id";
CM_ SG_ 768 BMS_hardwareId "High-voltage battery management system: hardware id";
CM_ SG_ 768 BMS_componentId "High-voltage battery management system: component id";
CM_ SG_ 768 BMS_pcbaId "BMS' assigned PCBA ID";
CM_ SG_ 768 BMS_assemblyId "BMS' assigned assembly ID";
CM_ SG_ 768 BMS_usageId "BMS' assigned usage ID";
CM_ SG_ 768 BMS_subUsageId "BMS' assigned subusage ID";
CM_ SG_ 768 BMS_platformType "High-voltage battery management system: platform type";
CM_ SG_ 768 BMS_appCrc "High-voltage battery management system: app crc";
CM_ SG_ 768 BMS_appGitHash "High-voltage battery management system: app git hash";
CM_ SG_ 768 BMS_bootGitHash "High-voltage battery management system: boot git hash";
CM_ SG_ 768 BMS_bootUdsProtoVersion "High-voltage battery management system: boot uds proto version";
CM_ SG_ 768 BMS_bootCrc "High-voltage battery management system: boot crc";
CM_ BO_ 978 "High-voltage battery management system message: kwh counter; frame length observed on a vehicle bus";
CM_ SG_ 978 BMS_kwhDischargeTotal "Total energy-lost kWh count during discharging";
CM_ SG_ 978 BMS_kwhChargeTotal "Total energy-gained kWh count during charging";
CM_ BO_ 1010 "High-voltage battery management system message: kwh counters multiplexed; frame length observed on a vehicle bus";
CM_ SG_ 1010 BMS_kwhCounter_Id "High-voltage battery management system: kwh counter id";
CM_ SG_ 1010 BMS_acChargerKwhTotal "Total energy-gained kWh count during AC charge";
CM_ SG_ 1010 BMS_dcChargerKwhTotal "Total energy-gained kWh count during DC charging";
CM_ SG_ 1010 BMS_kwhRegenChargeTotal "Total energy-gained kWh count during charging with regen";
CM_ SG_ 1010 BMS_kwhDriveDischargeTotal "Total energy-lost kWh count during discharging while driving";
CM_ SG_ 1010 BMS_kwhDischargeTotalModule1 "Total energy-lost kWh count during discharging for module number (1 indexed)";
CM_ SG_ 1010 BMS_kwhChargeTotalModule1 "Total energy-gained kWh count for module number (1 indexed)";
CM_ SG_ 1010 BMS_kwhAcChargeTotalModule1 "Total energy-gained kWh count during AC charge for module number (1 indexed)";
CM_ SG_ 1010 BMS_kwhDcChargeTotalModule1 "Total energy-gained kWh count during DC charge for module number (1 indexed)";
CM_ SG_ 1010 BMS_kwhDischargeTotalModule2 "Total energy-lost kWh count during discharging for module number (1 indexed)";
CM_ SG_ 1010 BMS_kwhChargeTotalModule2 "Total energy-gained kWh count for module number (1 indexed)";
CM_ SG_ 1010 BMS_kwhAcChargeTotalModule2 "Total energy-gained kWh count during AC charge for module number (1 indexed)";
CM_ SG_ 1010 BMS_kwhDcChargeTotalModule2 "Total energy-gained kWh count during DC charge for module number (1 indexed)";
CM_ SG_ 1010 BMS_kwhDischargeTotalModule3 "Total energy-lost kWh count during discharging for module number (1 indexed)";
CM_ SG_ 1010 BMS_kwhChargeTotalModule3 "Total energy-gained kWh count for module number (1 indexed)";
CM_ SG_ 1010 BMS_kwhAcChargeTotalModule3 "Total energy-gained kWh count during AC charge for module number (1 indexed)";
CM_ SG_ 1010 BMS_kwhDcChargeTotalModule3 "Total energy-gained kWh count during DC charge for module number (1 indexed)";
CM_ SG_ 1010 BMS_kwhDischargeTotalModule4 "Total energy-lost kWh count during discharging for module number (1 indexed)";
CM_ SG_ 1010 BMS_kwhChargeTotalModule4 "Total energy-gained kWh count for module number (1 indexed)";
CM_ SG_ 1010 BMS_kwhAcChargeTotalModule4 "Total energy-gained kWh count during AC charge for module number (1 indexed)";
CM_ SG_ 1010 BMS_kwhDcChargeTotalModule4 "Total energy-gained kWh count during DC charge for module number (1 indexed)";
CM_ BO_ 1170 "High-voltage battery management system message: state of health; frame length observed on a vehicle bus";
CM_ SG_ 1170 BMS_sohEnergyPercent "Estimate of battery SOH Energy % based on the most accurate capacity estimates the BMS has available; raw 1023 = signal not available (SNA)";
CM_ SG_ 1170 BMS_userFacingSohTestState "High-voltage battery management system: user facing soh test state";
CM_ SG_ 1170 BMS_userFacingSohTestEndMode "High-voltage battery management system: user facing soh test end mode";
CM_ SG_ 1170 BMS_timeSinceSohUpdate "Days since last successful SOH test; raw 4095 = signal not available (SNA)";
CM_ SG_ 1170 BMS_sohTestCycleFlag "Flag that is True from the start of an SOH test until it ends and all relevant signals have been logged";
CM_ SG_ 1170 BMS_sohTestIsBlocked "High-voltage battery management system: soh test is blocked";
CM_ SG_ 1170 BMS_calibratedSohAvailable "SOH Energy is based on valid results from the SOH capacity test";
CM_ SG_ 1170 BMS_requiredEvsePowerForSoh "High-voltage battery management system: required evse power for soh; raw 255 = signal not available (SNA)";
CM_ SG_ 1170 BMS_distanceSinceSohUpdate "Distance since the last State of Health update in km; raw 65535 = signal not available (SNA)";
CM_ BO_ 1116 "Charge cable controller message: alert log; frame length from the layout, not yet observed on a vehicle bus";
CM_ SG_ 1116 CC_alertID "Charge cable controller: alert ID";
CM_ SG_ 1116 CC_alertType "Charge cable controller: alert type";
CM_ SG_ 1116 CC_a001_groundResistance "Charge cable controller: a001 ground resistance; raw 4095 = signal not available (SNA)";
CM_ SG_ 1116 CC_a003_gfciRmsCurrent "Charge cable controller: a003 gfci rms current";
CM_ SG_ 1116 CC_a003_gfciRmsCurrentAvg "Charge cable controller: a003 gfci rms current avg";
CM_ SG_ 1116 CC_a003_dcGfciCurrent "Charge cable controller: a003 dc gfci current";
CM_ SG_ 1116 CC_a003_gfciFaultReason "Charge cable controller: a003 gfci fault reason; raw 0 = signal not available (SNA)";
CM_ SG_ 1116 CC_a003_gfciFaultBucket "Charge cable controller: a003 gfci fault bucket";
CM_ SG_ 1116 CC_a004_gfciErrorReason "Charge cable controller: a004 gfci error reason; raw 0 = signal not available (SNA)";
CM_ SG_ 1116 CC_a004_gfciAsicErrorBitfield "Charge cable controller: a004 gfci asic error bitfield";
CM_ SG_ 1116 CC_a004_gfciSelfTestDuty "Charge cable controller: a004 gfci self test duty";
CM_ SG_ 1116 CC_a004_gfciSelfTestCurrent "Charge cable controller: a004 gfci self test current";
CM_ SG_ 1116 CC_a006_line1Current "Charge cable controller: a006 line1 current";
CM_ SG_ 1116 CC_a006_line2Current "Charge cable controller: a006 line2 current";
CM_ SG_ 1116 CC_a006_line3Current "Charge cable controller: a006 line3 current";
CM_ SG_ 1116 CC_a007_inputVoltage "Charge cable controller: a007 input voltage";
CM_ SG_ 1116 CC_a007_inputLineVoltage "Charge cable controller: a007 input line voltage";
CM_ SG_ 1116 CC_a007_inputNeutralVoltage "Charge cable controller: a007 input neutral voltage";
CM_ SG_ 1116 CC_a008_inputVoltage "Charge cable controller: a008 input voltage";
CM_ SG_ 1116 CC_a008_inputLineVoltage "Charge cable controller: a008 input line voltage";
CM_ SG_ 1116 CC_a008_inputNeutralVoltage "Charge cable controller: a008 input neutral voltage";
CM_ SG_ 1116 CC_a010_line1Voltage "Charge cable controller: a010 line1 voltage";
CM_ SG_ 1116 CC_a010_line2Voltage "Charge cable controller: a010 line2 voltage";
CM_ SG_ 1116 CC_a010_line3Voltage "Charge cable controller: a010 line3 voltage";
CM_ SG_ 1116 CC_a010_line1StuckClosed "Charge cable controller: a010 line1 stuck closed";
CM_ SG_ 1116 CC_a010_line2StuckClosed "Charge cable controller: a010 line2 stuck closed";
CM_ SG_ 1116 CC_a010_line3StuckClosed "Charge cable controller: a010 line3 stuck closed";
CM_ SG_ 1116 CC_a011_pcbaTemp "Charge cable controller: a011 pcba temp";
CM_ SG_ 1116 CC_a012_inputThermopile "Charge cable controller: a012 input thermopile";
CM_ SG_ 1116 CC_a012_inputThermopileDvdt "Charge cable controller: a012 input thermopile dvdt";
CM_ SG_ 1116 CC_a013_handleTemp "Charge cable controller: a013 handle temp";
CM_ SG_ 1116 CC_a014_failureCause "Charge cable controller: a014 failure cause";
CM_ SG_ 1116 CC_a014_meterFaultAddress "Charge cable controller: a014 meter fault address";
CM_ SG_ 1116 CC_a014_meterFaultData "Charge cable controller: a014 meter fault data";
CM_ SG_ 1116 CC_a014_meterRetryCount "Charge cable controller: a014 meter retry count";
CM_ SG_ 1116 CC_a015_pilotHighVolage "Charge cable controller: a015 pilot high volage";
CM_ SG_ 1116 CC_a015_smState "Charge cable controller: a015 sm state";
CM_ SG_ 1116 CC_a027_handleTemperature "Charge cable controller: a027 handle temperature";
CM_ SG_ 1116 CC_a027_handleTempFaultReason "Charge cable controller: a027 handle temp fault reason";
CM_ SG_ 1116 CC_a032_meteringSpiCommsFailure "Charge cable controller: a032 metering spi comms failure";
CM_ SG_ 1116 CC_a032_meteringConfigMismatch "Charge cable controller: a032 metering config mismatch";
CM_ SG_ 1116 CC_a033_nominalVoltage "Charge cable controller: a033 nominal voltage";
CM_ SG_ 1116 CC_a033_measuredVoltage "Charge cable controller: a033 measured voltage";
CM_ SG_ 1116 CC_a036_line1Voltage "Charge cable controller: a036 line1 voltage";
CM_ SG_ 1116 CC_a036_line2Voltage "Charge cable controller: a036 line2 voltage";
CM_ SG_ 1116 CC_a036_line3Voltage "Charge cable controller: a036 line3 voltage";
CM_ SG_ 1116 CC_a036_line1StuckOpen "Charge cable controller: a036 line1 stuck open";
CM_ SG_ 1116 CC_a036_line2StuckOpen "Charge cable controller: a036 line2 stuck open";
CM_ SG_ 1116 CC_a036_line3StuckOpen "Charge cable controller: a036 line3 stuck open";
CM_ SG_ 1116 CC_a037_expiredWatchdogModuleId "Charge cable controller: a037 expired watchdog module id";
CM_ SG_ 1116 CC_a037_expiredWatchdogTaskId "Charge cable controller: a037 expired watchdog task id";
CM_ SG_ 1116 CC_a037_expiredWatchdogAppCRC "Charge cable controller: a037 expired watchdog app CRC";
CM_ SG_ 1116 CC_a038_moduleMiaModuleId "Charge cable controller: a038 module mia module id";
CM_ SG_ 1116 CC_a038_moduleMiaTaskId "Charge cable controller: a038 module mia task id";
CM_ SG_ 1116 CC_a038_moduleMiaAppCRC "Charge cable controller: a038 module mia app CRC";
CM_ SG_ 1116 CC_a039_intModuleTemperature "Charge cable controller: a039 int module temperature";
CM_ SG_ 1116 CC_a040_handleTemperature "Charge cable controller: a040 handle temperature";
CM_ SG_ 1116 CC_a041_inputThermopile "Charge cable controller: a041 input thermopile";
CM_ SG_ 1116 CC_a041_inputThermopileDvdt "Charge cable controller: a041 input thermopile dvdt";
CM_ SG_ 1116 CC_a042_pcbaTemperature "Charge cable controller: a042 pcba temperature";
CM_ SG_ 1116 CC_a044_relayCoilVoltage "Charge cable controller: a044 relay coil voltage";
CM_ SG_ 1116 CC_a044_pcbaTemperature "Charge cable controller: a044 pcba temperature";
CM_ BO_ 1132 "Charge cable controller message: alert matrix1; frame length from the layout, not yet observed on a vehicle bus";
CM_ SG_ 1132 CC_a001_gndMonIntrptLineSide "Charge cable controller: a001 gnd mon intrpt line side";
CM_ SG_ 1132 CC_a002_gndMonIntrptLoadSide "Charge cable controller: a002 gnd mon intrpt load side";
CM_ SG_ 1132 CC_a003_CCIDTripped "Charge cable controller: a003 CCID tripped";
CM_ SG_ 1132 CC_a004_CCIDSelfTestFault "Charge cable controller: a004 CCID self test fault";
CM_ SG_ 1132 CC_a005_groundedNeutral "Charge cable controller: a005 grounded neutral";
CM_ SG_ 1132 CC_a006_inputOverCurrent "Charge cable controller: a006 input over current";
CM_ SG_ 1132 CC_a007_inputOverVoltage "Charge cable controller: a007 input over voltage";
CM_ SG_ 1132 CC_a008_inputUnderVoltage "Charge cable controller: a008 input under voltage";
CM_ SG_ 1132 CC_a009_inputMiswired "Charge cable controller: a009 input miswired";
CM_ SG_ 1132 CC_a010_contactorWelded "Charge cable controller: a010 contactor welded";
CM_ SG_ 1132 CC_a011_ambientOT "Charge cable controller: a011 ambient OT";
CM_ SG_ 1132 CC_a012_wallPlugOT "Charge cable controller: a012 wall plug OT";
CM_ SG_ 1132 CC_a013_vehConnOT "Charge cable controller: a013 veh conn OT";
CM_ SG_ 1132 CC_a014_mcuSelfTestFault "Charge cable controller: a014 mcu self test fault";
CM_ SG_ 1132 CC_a015_PilotAFault "Charge cable controller: a015 pilot a fault";
CM_ SG_ 1132 CC_a016_PilotBFault "Charge cable controller: a016 pilot b fault";
CM_ SG_ 1132 CC_a017_PilotCFault "Charge cable controller: a017 pilot c fault";
CM_ SG_ 1132 CC_a018_PilotDFault "Charge cable controller: a018 pilot d fault";
CM_ SG_ 1132 CC_a019_proxDisconnected "Charge cable controller: a019 prox disconnected";
CM_ SG_ 1132 CC_a020_3vRailIncorrect "Charge cable controller: a020 3v rail incorrect";
CM_ SG_ 1132 CC_a021_CB_noMaster "Charge cable controller: a021 CB no master";
CM_ SG_ 1132 CC_a022_CB_tooManyMasters "Charge cable controller: a022 CB too many masters";
CM_ SG_ 1132 CC_a023_CB_tooManySlaves "Charge cable controller: a023 CB too many slaves";
CM_ SG_ 1132 CC_a024_CB_masterISetTooLow "Charge cable controller: a024 CB master i set too low";
CM_ SG_ 1132 CC_a025_evseTemp "Charge cable controller: a025 evse temp";
CM_ SG_ 1132 CC_a026_wallPlugTemp "Charge cable controller: a026 wall plug temp";
CM_ SG_ 1132 CC_a027_vehicleHandleTemp "Charge cable controller: a027 vehicle handle temp";
CM_ SG_ 1132 CC_a028_CB_rotarySelect "Charge cable controller: a028 CB rotary select";
CM_ SG_ 1132 CC_a029_PilotFFault "Charge cable controller: a029 pilot f fault";
CM_ SG_ 1132 CC_a030_masterSlaveMismatch "Charge cable controller: a030 master slave mismatch";
CM_ SG_ 1132 CC_a031_pllLockLost "Charge cable controller: a031 pll lock lost";
CM_ SG_ 1132 CC_a032_meteringFailure "Charge cable controller: a032 metering failure";
CM_ SG_ 1132 CC_a033_vRefOutOfRange "Charge cable controller: a033 v ref out of range";
CM_ SG_ 1132 CC_a034_bootAlert "Charge cable controller: a034 boot alert";
CM_ SG_ 1132 CC_a035_CCIDCalibration "Charge cable controller: a035 CCID calibration";
CM_ SG_ 1132 CC_a036_contactorStuckOpen "Charge cable controller: a036 contactor stuck open";
CM_ SG_ 1132 CC_a037_internalModuleWatchdogEx "Charge cable controller: a037 internal module watchdog expired";
CM_ SG_ 1132 CC_a038_internalModuleMia "Charge cable controller: a038 internal module mia";
CM_ SG_ 1132 CC_a039_internalModuleOverTemp "Charge cable controller: a039 internal module over temp";
CM_ SG_ 1132 CC_a040_handleTempFoldback "Charge cable controller: a040 handle temp foldback";
CM_ SG_ 1132 CC_a041_inputWiringFoldback "Charge cable controller: a041 input wiring foldback";
CM_ SG_ 1132 CC_a042_pcbaTempFoldback "Charge cable controller: a042 pcba temp foldback";
CM_ SG_ 1132 CC_a043_configurationRequired "Charge cable controller: a043 configuration required";
CM_ SG_ 1132 CC_a044_relayCoilVoltageRational "Charge cable controller: a044 relay coil voltage rationality";
CM_ SG_ 1132 CC_a045_ACPowerLoss "Charge cable controller: a045 AC power loss";
CM_ SG_ 1132 CC_a046_GFCIConfigInvalid "Charge cable controller: a046 GFCI config invalid";
CM_ SG_ 1132 CC_a047_MDMotorContFault "Charge cable controller: a047 MD motor cont fault";
CM_ SG_ 1132 CC_a048_ACMDAdapterFault "Charge cable controller: a048 ACMD adapter fault";
CM_ SG_ 1132 CC_a049_rs485Fault "Charge cable controller: a049 rs485 fault";
CM_ SG_ 1132 CC_a050_eFuseFault "Charge cable controller: a050 e fuse fault";
CM_ SG_ 1132 CC_a051_chcCriticalFault "Charge cable controller: a051 chc critical fault";
CM_ SG_ 1132 CC_a052_vRefOutOfRangePWM "Charge cable controller: a052 v ref out of range PWM";
CM_ SG_ 1132 CC_a057_chcVitalsRequestFailure "Charge cable controller: a057 chc vitals request failure";
CM_ SG_ 1132 CC_a060_persistenceFault "Charge cable controller: a060 persistence fault";
CM_ SG_ 1132 CC_a061_unfinishedCommissioning "Charge cable controller: a061 unfinished commissioning";
CM_ BO_ 796 "Charge cable controller message: chg status; frame length from the layout, not yet observed on a vehicle bus";
CM_ SG_ 796 CC_currentLimit "Maximum allowable AC current the wall connector is willing to provide; raw 255 = signal not available (SNA)";
CM_ SG_ 796 CC_pilotState "State of pilot signal reported by the wall connector; raw 3 = signal not available (SNA)";
CM_ SG_ 796 CC_numPhases "Number of AC phases expected by wall connector; raw 0 = signal not available (SNA)";
CM_ SG_ 796 CC_line1Voltage "RMS voltage on L1 terminal of wall connector; raw 511 = signal not available (SNA)";
CM_ SG_ 796 CC_gridGrounding "Grouding scheme expected by the wall connector; raw 2 = signal not available (SNA)";
CM_ SG_ 796 CC_deltaTransformer "Grid configuration expected by the wall connector";
CM_ SG_ 796 CC_numVehCharging "Number of vehicles charging in wall connector load sharing group";
CM_ SG_ 796 CC_line2Voltage "RMS voltage on L2 terminal of wall connector; raw 511 = signal not available (SNA)";
CM_ SG_ 796 CC_line3Voltage "RMS voltage on L3 terminal of wall connector; raw 511 = signal not available (SNA)";
CM_ SG_ 796 CC_groundResistance "Charge cable controller: ground resistance; raw 4095 = signal not available (SNA)";
CM_ BO_ 812 "Charge cable controller message: log data; frame length from the layout, not yet observed on a vehicle bus";
CM_ SG_ 812 CC_logIndex "Charge cable controller: log index";
CM_ SG_ 812 CC_activeConnectorID "Site identifier of active charge connector";
CM_ SG_ 812 CC_temperature1 "Charge cable vehicle connector temperature";
CM_ SG_ 812 CC_temperature2 "Charge cable vehicle connector temperature";
CM_ SG_ 812 CC_temperature3 "Charge cable vehicle connector temperature";
CM_ SG_ 812 CC_contactor1Closed "State of contactor 1 in wall connector";
CM_ SG_ 812 CC_contactor2Closed "State of contactor 1 in wall connector";
CM_ SG_ 812 CC_temperature4 "Charge cable vehicle connector temperature";
CM_ SG_ 812 CC_conn1Current "AC current on connector 1 in wall charger load sharing group; raw 255 = signal not available (SNA)";
CM_ SG_ 812 CC_conn2Current "AC current on connector 2 in wall charger load sharing group; raw 255 = signal not available (SNA)";
CM_ SG_ 812 CC_conn3Current "AC current on connector 3 in wall charger load sharing group; raw 255 = signal not available (SNA)";
CM_ SG_ 812 CC_conn4Current "AC current on connector 4 in wall charger load sharing group; raw 255 = signal not available (SNA)";
CM_ SG_ 812 CC_lifetimei2t "Charge cable controller: lifetimei2t";
CM_ SG_ 812 CC_lifetimeCtrCycles "Charge cable controller: lifetime ctr cycles";
CM_ SG_ 812 CC_lifetimeCtrCyclesLoaded "Charge cable controller: lifetime ctr cycles loaded";
CM_ SG_ 812 CC_lifetimeAlertCount "Charge cable controller: lifetime alert count";
CM_ SG_ 812 CC_lifetimeThermalFoldbacks "Charge cable controller: lifetime thermal foldbacks";
CM_ SG_ 812 CC_lifetimeAvgStartupTemp "Charge cable controller: lifetime avg startup temp";
CM_ BO_ 870 "CMPD ECU message: info; frame length from the layout, not yet observed on a vehicle bus";
CM_ SG_ 870 CMPD_infoIndex "CMPD ECU: info index";
CM_ SG_ 870 CMPD_infoBuildType "CMPD ECU: info build type";
CM_ SG_ 870 CMPD_infoBuildConfigId "CMPD ECU: info build config id";
CM_ SG_ 870 CMPD_infoHardwareId "CMPD ECU: info hardware id";
CM_ SG_ 870 CMPD_infoComponentId "CMPD ECU: info component id";
CM_ SG_ 870 CMPD_infoPcbaId "CMPD ECU: info pcba id";
CM_ SG_ 870 CMPD_infoAssemblyId "CMPD ECU: info assembly id; raw 255 = signal not available (SNA)";
CM_ SG_ 870 CMPD_infoUsageId "CMPD ECU: info usage id";
CM_ SG_ 870 CMPD_infoSubUsageId "CMPD ECU: info sub usage id";
CM_ BO_ 679 "CMPD ECU message: state; frame length from the layout, not yet observed on a vehicle bus";
CM_ SG_ 679 CMPD_speedRPM "Reports compressor speed.";
CM_ SG_ 679 CMPD_speedDuty "Reports compressor speed duty cycle percentage.";
CM_ SG_ 679 CMPD_inputHVPower "Measures compressor input high voltage (HV) power consumption.";
CM_ SG_ 679 CMPD_inputHVCurrent "Measures compressor input high voltage (HV) current draw.";
CM_ SG_ 679 CMPD_inputHVVoltage "Measures compressor input high voltage (HV) level.";
CM_ SG_ 679 CMPD_2ShuntModeActive "Indicates the compressor motor control is running using only two current shunt resistors instead of three.";
CM_ SG_ 679 CMPD_powerLimitActive "Indicates the compressor power limit is active.";
CM_ SG_ 679 CMPD_state "Reports compressor operational state; raw 15 = signal not available (SNA)";
CM_ SG_ 679 CMPD_wasteHeatState "Reports compressor waste heat recovery state.";
CM_ SG_ 679 CMPD_powerLimitTooLowToStart "Indicates the compressor power limit is too low to start the compressor.";
CM_ SG_ 679 CMPD_ready "Indicates the compressor is ready to start.";
CM_ BO_ 867 "A/C compressor message: info; frame length from the layout, not yet observed on a vehicle bus";
CM_ SG_ 867 CMP_infoIndex "A/C compressor: info index";
CM_ SG_ 867 CMP_infoBuildType "A/C compressor: info build type";
CM_ SG_ 867 CMP_infoBuildConfigId "A/C compressor: info build config id";
CM_ SG_ 867 CMP_infoHardwareId "A/C compressor: info hardware id";
CM_ SG_ 867 CMP_infoComponentId "A/C compressor: info component id";
CM_ SG_ 867 CMP_infoPcbaId "A/C compressor: info pcba id";
CM_ SG_ 867 CMP_infoAssemblyId "A/C compressor: info assembly id; raw 255 = signal not available (SNA)";
CM_ SG_ 867 CMP_infoUsageId "A/C compressor: info usage id";
CM_ SG_ 867 CMP_infoSubUsageId "A/C compressor: info sub usage id";
CM_ SG_ 867 CMP_infoPlatformType "A/C compressor: info platform type";
CM_ SG_ 867 CMP_infoAppCrc "A/C compressor: info app crc";
CM_ SG_ 867 CMP_infoBootUdsProtoVersion "A/C compressor: info boot uds proto version";
CM_ SG_ 867 CMP_infoBootCrc "A/C compressor: info boot crc";
CM_ BO_ 1767 "Charge port controller message: iso tp pipe to pncd; frame length from the layout, not yet observed on a vehicle bus";
CM_ SG_ 1767 CP_isoTpToPncdData "Charge port controller: iso tp to pncd data";
CM_ BO_ 1342 "Charge port controller message: info; frame length observed on a vehicle bus";
CM_ SG_ 1342 CP_infoIndex "Charge port controller: info index";
CM_ SG_ 1342 CP_buildType "Charge port controller: build type";
CM_ SG_ 1342 CP_buildConfigId "Charge port controller: build config id";
CM_ SG_ 1342 CP_hardwareId "Charge port controller: hardware id";
CM_ SG_ 1342 CP_componentId "Charge port controller: component id";
CM_ SG_ 1342 CP_pcbaId "Charge port controller: pcba id";
CM_ SG_ 1342 CP_assemblyId "Charge port controller: assembly id";
CM_ SG_ 1342 CP_usageId "Charge port controller: usage id";
CM_ SG_ 1342 CP_subUsageId "Charge port controller: sub usage id";
CM_ SG_ 1342 CP_platformType "Charge port controller: platform type";
CM_ SG_ 1342 CP_appCrc "Charge port controller: app crc";
CM_ SG_ 1342 CP_appGitHash "Charge port controller: app git hash";
CM_ SG_ 1342 CP_bootGitHash "Charge port controller: boot git hash";
CM_ SG_ 1342 CP_bootUdsProtoVersion "Charge port controller: boot uds proto version";
CM_ SG_ 1342 CP_bootCrc "Charge port controller: boot crc";
CM_ BO_ 1001 "Driver assistance computer message: body controls; frame length observed on a vehicle bus";
CM_ SG_ 1001 DAS_headlightRequest "The DAS request to the body controls ecu to turn on headlights.";
CM_ SG_ 1001 DAS_hazardLightRequest "The command from DAS to body controls to turn on the hazard lights; raw 3 = signal not available (SNA)";
CM_ SG_ 1001 DAS_wiperSpeed "The auto wiper algorithm speed request to the body controller.";
CM_ SG_ 1001 DAS_turnIndicatorRequest "Reports Driver Assistance System (DAS) request to body controls to turn on/off the left or right turn indicator.";
CM_ SG_ 1001 DAS_highLowBeamDecision "The output of the automatic high beam algorithm, to turn the highbeams on or off; raw 3 = signal not available (SNA)";
CM_ SG_ 1001 DAS_heaterRequest "The DAS request to the body controller to turn on the front glass heater in front of the triple camera; raw 0 = signal not available (SNA)";
CM_ SG_ 1001 DAS_highLowBeamOffReason "The reason why automatic high beams are surpressed; raw 5 = signal not available (SNA)";
CM_ SG_ 1001 DAS_forwardCamHeaterDutyCycle "Supplies the requested duty cycle of the front windshield camera heater";
CM_ SG_ 1001 DAS_dynamicBrakeLightRequest "Indicates if the dynamic brake light alogirthm is requesting pulsing brake lights.";
CM_ SG_ 1001 DAS_radarHeaterRequest "Reports the request from Driver Assistance System (DAS) to body controls to turn on heater to clear out fascia in front of the radar.";
CM_ SG_ 1001 DAS_ahlbOverride "Indicates if body controller should override UI switch and stalk state to allow auto high beam functionality";
CM_ SG_ 1001 DAS_mirrorFoldRequest "DAS request to fold or present mirrors; raw 3 = signal not available (SNA)";
CM_ SG_ 1001 DAS_wiperWashRequest "Autowiper requests that the windshield be washed";
CM_ SG_ 1001 DAS_ulcConfirmationRequestActive "Driver assistance computer: ulc confirmation request active";
CM_ SG_ 1001 DAS_overrideWiperSetting "Autopilot wants to override the user's wiper setting to enable auto-wiper";
CM_ SG_ 1001 DAS_autoWiperState "DAS auto wiper internal state; raw 5 = signal not available (SNA)";
CM_ SG_ 1001 DAS_turnIndicatorRequestReason "Reports the reason that Driver Assistance System (DAS) is requesting a change to the turn indicator state from body controls.";
CM_ SG_ 1001 DAS_forwardRadarPowerRequest "Driver assistance computer: forward radar power request";
CM_ SG_ 1001 DAS_driverDomeLightRequest "DAS requests that driver side dome light be illuminated";
CM_ SG_ 1001 DAS_drivePowerStateRequest "Reports DAS request for vehicle power state Drive.";
CM_ SG_ 1001 DAS_enableIcrDataCollection "Driver assistance computer: enable icr data collection";
CM_ SG_ 1001 DAS_rPillarCamHeaterDutyCycle "Supplies the requested duty cycle of the right pillar camera heater";
CM_ SG_ 1001 DAS_adaptiveHighBeamIsFaulted "Indicates malfunctioning or unavailable input to the Adaptive High Beam system.";
CM_ SG_ 1001 DAS_restrictDoorReleaseLeft "Reports requests to inhibit left doors from being released.";
CM_ SG_ 1001 DAS_restrictDoorReleaseRight "Reports requests to inhibit right doors from being released.";
CM_ SG_ 1001 DAS_bodyControlsCounter "Driver assistance computer: body controls counter";
CM_ SG_ 1001 DAS_bodyControlsChecksum "Driver assistance computer: body controls checksum";
CM_ BO_ 741 "Front drive inverter message: power; frame length from the layout, not yet observed on a vehicle bus";
CM_ SG_ 741 DIF_elecPower "Front drive inverter: elec power; raw 1024 = signal not available (SNA)";
CM_ SG_ 741 DIF_heatPowerOptimal "Front drive inverter: heat power optimal";
CM_ SG_ 741 DIF_heatPowerMax "Drive Inverter maximum heat power capability";
CM_ SG_ 741 DIF_heatPowerActual "Drive Inverter heat power";
CM_ SG_ 741 DIF_excessHeatCommand "Drive Inverter excess heat command";
CM_ SG_ 741 DIF_drivePowerMax "Front drive inverter: drive power max; raw 511 = signal not available (SNA)";
CM_ BO_ 1367 "Front drive inverter message: thermal control; frame length from the layout, not yet observed on a vehicle bus";
CM_ SG_ 1367 DIF_passiveInletTempReq "Front drive inverter: passive inlet temp req";
CM_ SG_ 1367 DIF_activeInletTempReq "Front drive inverter: active inlet temp req";
CM_ SG_ 1367 DIF_coolantFlowReq "Coolant flow requested";
CM_ SG_ 1367 DIF_oilFlowReq "Front drive inverter: oil flow req; raw 255 = signal not available (SNA)";
CM_ SG_ 1367 DIF_criticalFlowReq "Front drive inverter: critical flow req";
CM_ SG_ 1367 DIF_burnInStatus "Front drive inverter: burn in status";
CM_ BO_ 2005 "Rear drive inverter message: debug; frame length from the layout, not yet observed on a vehicle bus";
CM_ SG_ 2005 DIR_debugSelector "Rear drive inverter: debug selector";
CM_ SG_ 2005 DIR_phaseOutBusbarTemp "Rear drive inverter: phase out busbar temp; raw 0 = signal not available (SNA)";
CM_ SG_ 2005 DIR_phaseOutBusbarWeldTemp "Rear drive inverter: phase out busbar weld temp; raw 0 = signal not available (SNA)";
CM_ SG_ 2005 DIR_phaseOutLugTemp "Rear drive inverter: phase out lug temp; raw 0 = signal not available (SNA)";
CM_ SG_ 2005 DIR_dcLinkCapTemp "Rear drive inverter: dc link cap temp; raw 0 = signal not available (SNA)";
CM_ SG_ 2005 DIR_hvDcCableTemp "Rear drive inverter: hv dc cable temp; raw 0 = signal not available (SNA)";
CM_ SG_ 2005 DIR_negDcBusbarTemp "Rear drive inverter: neg dc busbar temp; raw 0 = signal not available (SNA)";
CM_ SG_ 2005 DIR_posDcBusbarTemp "Rear drive inverter: pos dc busbar temp; raw 0 = signal not available (SNA)";
CM_ SG_ 2005 DIR_statorEndWindingTemp "Rear drive inverter: stator end winding temp; raw 0 = signal not available (SNA)";
CM_ SG_ 2005 DIR_rotorMaxMagnetTemp "Reports the maximum temperature of the rotor magnet; raw 0 = signal not available (SNA)";
CM_ SG_ 2005 DIR_lightSenseV "Rear drive inverter: light sense v";
CM_ SG_ 2005 DIR_pyroSenseV "Rear drive inverter: pyro sense v";
CM_ SG_ 2005 DIR_statorSlotWindingTemp "Rear drive inverter: stator slot winding temp; raw 0 = signal not available (SNA)";
CM_ SG_ 2005 DIR_intervalMaxHvBusV "Rear drive inverter: interval max hv bus v";
CM_ BO_ 917 "Rear drive inverter message: oil pump; frame length from the layout, not yet observed on a vehicle bus";
CM_ SG_ 917 DIR_oilPumpState "Reports the state of the oil pump; raw 7 = signal not available (SNA)";
CM_ SG_ 917 DIR_oilPumpFluidTQF "Rear drive inverter: oil pump fluid TQF";
CM_ SG_ 917 DIR_oilPumpLeadAngle "Rear drive inverter: oil pump lead angle";
CM_ SG_ 917 DIR_oilPumpFlowTarget "Detects oil pump flow target; raw 255 = signal not available (SNA)";
CM_ SG_ 917 DIR_oilPumpFlowActual "Detects oil pump flow; raw 255 = signal not available (SNA)";
CM_ SG_ 917 DIR_oilPumpFluidT "Detects oil pump fluid tester; raw 255 = signal not available (SNA)";
CM_ SG_ 917 DIR_oilPumpPhaseCurrent "Rear drive inverter: oil pump phase current; raw 255 = signal not available (SNA)";
CM_ SG_ 917 DIR_oilPumpPressureEstimate "Oil pump pressure estimate; raw 255 = signal not available (SNA)";
CM_ SG_ 917 DIR_oilPumpPressureExpected "Oil pump pressure expected; raw 255 = signal not available (SNA)";
CM_ SG_ 917 DIR_oilPumpPressureResidual "Oil pressure error outside of allowed tolerance; raw 255 = signal not available (SNA)";
CM_ BO_ 614 "Rear drive inverter message: power; frame length from the layout, not yet observed on a vehicle bus";
CM_ SG_ 614 DIR_elecPower "Rear drive inverter: elec power; raw 1024 = signal not available (SNA)";
CM_ SG_ 614 DIR_heatPowerOptimal "Rear drive inverter: heat power optimal";
CM_ SG_ 614 DIR_heatPowerMax "Drive Inverter maximum heat power capability";
CM_ SG_ 614 DIR_heatPowerActual "Drive Inverter heat power";
CM_ SG_ 614 DIR_excessHeatCommand "Drive Inverter excess heat command";
CM_ SG_ 614 DIR_drivePowerMax "Rear drive inverter: drive power max; raw 511 = signal not available (SNA)";
CM_ BO_ 1495 "Rear drive inverter message: thermal control; frame length from the layout, not yet observed on a vehicle bus";
CM_ SG_ 1495 DIR_passiveInletTempReq "Rear drive inverter: passive inlet temp req";
CM_ SG_ 1495 DIR_activeInletTempReq "Rear drive inverter: active inlet temp req";
CM_ SG_ 1495 DIR_coolantFlowReq "Coolant flow requested";
CM_ SG_ 1495 DIR_oilFlowReq "Rear drive inverter: oil flow req; raw 255 = signal not available (SNA)";
CM_ SG_ 1495 DIR_criticalFlowReq "Rear drive inverter: critical flow req";
CM_ SG_ 1495 DIR_burnInStatus "Rear drive inverter: burn in status";
CM_ BO_ 2007 "Drive inverter message: debug; frame length from the layout, not yet observed on a vehicle bus";
CM_ SG_ 2007 DI_debugSelector "Drive inverter: debug selector";
CM_ SG_ 2007 DI_regenBackfillCmd "Drive inverter: regen backfill cmd";
CM_ SG_ 2007 DI_regenBackfillUnavailableReaso "Drive inverter: regen backfill unavailable reason";
CM_ SG_ 2007 DI_regenBackfillAbsSatState "Drive inverter: regen backfill abs sat state";
CM_ SG_ 2007 DI_sysHeatPowerOptimal "Drive inverter: sys heat power optimal";
CM_ SG_ 2007 DI_sysPostPedalMinTorque "Drive inverter: sys post pedal min torque";
CM_ SG_ 2007 DI_sysPostPedalMaxTorque "Drive inverter: sys post pedal max torque";
CM_ SG_ 2007 DI_systemTorqueCommand "Drive inverter: system torque command";
CM_ BO_ 616 "Drive inverter message: system power; frame length from the layout, not yet observed on a vehicle bus";
CM_ SG_ 616 DI_sysHeatPowerMax "Drive inverter: sys heat power max";
CM_ SG_ 616 DI_sysHeatPowerActual "Drive Inverter system heat power";
CM_ SG_ 616 DI_sysDrivePowerMax "Maximum drive power output total for all motors; raw 511 = signal not available (SNA)";
CM_ SG_ 616 DI_primaryUnitSiliconType "Drive inverter: primary unit silicon type";
CM_ SG_ 616 DI_sysRegenPowerMax "Maximum regen power output total for all motors; raw 255 = signal not available (SNA)";
CM_ BO_ 1992 "Left electric parking brake message: info; frame length observed on a vehicle bus";
CM_ SG_ 1992 EPBL_infoIndex "Left electric parking brake: info index";
CM_ SG_ 1992 EPBL_infoBuildType "Left electric parking brake: info build type";
CM_ SG_ 1992 EPBL_infoBuildConfigId "Left electric parking brake: info build config id";
CM_ SG_ 1992 EPBL_infoHardwareId "Left electric parking brake: info hardware id";
CM_ SG_ 1992 EPBL_infoComponentId "Left electric parking brake: info component id";
CM_ SG_ 1992 EPBL_infoPcbaId "Left electric parking brake: info pcba id";
CM_ SG_ 1992 EPBL_infoAssemblyId "Left electric parking brake: info assembly id; raw 255 = signal not available (SNA)";
CM_ SG_ 1992 EPBL_infoUsageId "Left electric parking brake: info usage id";
CM_ SG_ 1992 EPBL_infoSubUsageId "Left electric parking brake: info sub usage id";
CM_ SG_ 1992 EPBL_infoAppCrc "Left electric parking brake: info app crc";
CM_ SG_ 1992 EPBL_infoAppGitHash "Left electric parking brake: info app git hash";
CM_ SG_ 1992 EPBL_infoBootGitHash "Left electric parking brake: info boot git hash";
CM_ SG_ 1992 EPBL_infoPlatformType "Left electric parking brake: info platform type";
CM_ SG_ 1992 EPBL_infoBootUdsProtoVersion "Left electric parking brake: info boot uds proto version";
CM_ SG_ 1992 EPBL_infoBootCrc "Left electric parking brake: info boot crc";
CM_ BO_ 648 "Left electric parking brake message: internal status; frame length observed on a vehicle bus";
CM_ SG_ 648 EPBL_unitStatus "Electronic Parking Brake's unit state.";
CM_ SG_ 648 EPBL_unitFaultStatus "Left electric parking brake: unit fault status";
CM_ SG_ 648 EPBL_summonState "Left electric parking brake: summon state";
CM_ SG_ 648 EPBL_disconnected "Left electric parking brake: disconnected";
CM_ SG_ 648 EPBL_pistonTouchingRotor "Left electric parking brake: piston touching rotor";
CM_ SG_ 648 EPBL_csmFaultReason "Left electric parking brake: csm fault reason";
CM_ SG_ 648 EPBL_esmOperationTrigger "Left electric parking brake: esm operation trigger";
CM_ SG_ 648 EPBL_summonFaultReason "Error code associated with previous summon failure.";
CM_ SG_ 648 EPBL_localServiceModeActive "Signal reported by Left electric parking brake";
CM_ SG_ 648 EPBL_localCdpState "Left electric parking brake: local cdp state";
CM_ SG_ 648 EPBL_chimeRequestLocal "Left electric parking brake: chime request local";
CM_ SG_ 648 EPBL_telltaleLocal "Left electric parking brake: telltale local; raw 7 = signal not available (SNA)";
CM_ SG_ 648 EPBL_driverIsLeavingLocal "Left electric parking brake: driver is leaving local";
CM_ SG_ 648 EPBL_driverIsLeavingAnySpeedLoca "Left electric parking brake: driver is leaving any speed local";
CM_ SG_ 648 EPBL_internalCDPRequest "Left electric parking brake: internal CDP request";
CM_ SG_ 648 EPBL_esmSpeedClass "Left electric parking brake: esm speed class";
CM_ SG_ 648 EPBL_learnedEpbConfig "Left electric parking brake: learned epb config";
CM_ SG_ 648 EPBL_internalStatusCounter "Left electric parking brake: internal status counter";
CM_ SG_ 648 EPBL_internalStatusChecksum "Left electric parking brake: internal status checksum";
CM_ BO_ 743 "Left electric parking brake message: seat status3; frame length from the layout, not yet observed on a vehicle bus";
CM_ SG_ 743 EPBL_frontSeatCushionFanCur "Left electric parking brake: front seat cushion fan cur";
CM_ SG_ 743 EPBL_frontSeatBackrestFanCur "Left electric parking brake: front seat backrest fan cur";
CM_ SG_ 743 EPBL_frontSeatCushionFanDuty "Left electric parking brake: front seat cushion fan duty";
CM_ SG_ 743 EPBL_frontSeatCushionFanEn "Left electric parking brake: front seat cushion fan en";
CM_ SG_ 743 EPBL_frontSeatBackrestFanEn "Left electric parking brake: front seat backrest fan en";
CM_ SG_ 743 EPBL_frontSeatBackrestFanDuty "Left electric parking brake: front seat backrest fan duty";
CM_ BO_ 2024 "Right electric parking brake message: info; frame length observed on a vehicle bus";
CM_ SG_ 2024 EPBR_infoIndex "Right electric parking brake: info index";
CM_ SG_ 2024 EPBR_infoBuildType "Right electric parking brake: info build type";
CM_ SG_ 2024 EPBR_infoBuildConfigId "Right electric parking brake: info build config id";
CM_ SG_ 2024 EPBR_infoHardwareId "Right electric parking brake: info hardware id";
CM_ SG_ 2024 EPBR_infoComponentId "Right electric parking brake: info component id";
CM_ SG_ 2024 EPBR_infoPcbaId "Right electric parking brake: info pcba id";
CM_ SG_ 2024 EPBR_infoAssemblyId "Right electric parking brake: info assembly id; raw 255 = signal not available (SNA)";
CM_ SG_ 2024 EPBR_infoUsageId "Right electric parking brake: info usage id";
CM_ SG_ 2024 EPBR_infoSubUsageId "Right electric parking brake: info sub usage id";
CM_ SG_ 2024 EPBR_infoAppCrc "Right electric parking brake: info app crc";
CM_ SG_ 2024 EPBR_infoAppGitHash "Right electric parking brake: info app git hash";
CM_ SG_ 2024 EPBR_infoBootGitHash "Right electric parking brake: info boot git hash";
CM_ SG_ 2024 EPBR_infoPlatformType "Right electric parking brake: info platform type";
CM_ SG_ 2024 EPBR_infoBootUdsProtoVersion "Right electric parking brake: info boot uds proto version";
CM_ SG_ 2024 EPBR_infoBootCrc "Right electric parking brake: info boot crc";
CM_ BO_ 552 "Right electric parking brake message: internal status; frame length observed on a vehicle bus";
CM_ SG_ 552 EPBR_unitStatus "Electronic Parking Brake's unit state.";
CM_ SG_ 552 EPBR_unitFaultStatus "Right electric parking brake: unit fault status";
CM_ SG_ 552 EPBR_summonState "Right electric parking brake: summon state";
CM_ SG_ 552 EPBR_disconnected "Right electric parking brake: disconnected";
CM_ SG_ 552 EPBR_pistonTouchingRotor "Right electric parking brake: piston touching rotor";
CM_ SG_ 552 EPBR_csmFaultReason "Right electric parking brake: csm fault reason";
CM_ SG_ 552 EPBR_esmOperationTrigger "Right electric parking brake: esm operation trigger";
CM_ SG_ 552 EPBR_summonFaultReason "Error code associated with previous summon failure.";
CM_ SG_ 552 EPBR_localServiceModeActive "Signal reported by Right electric parking brake";
CM_ SG_ 552 EPBR_localCdpState "Right electric parking brake: local cdp state";
CM_ SG_ 552 EPBR_chimeRequestLocal "Right electric parking brake: chime request local";
CM_ SG_ 552 EPBR_telltaleLocal "Right electric parking brake: telltale local; raw 7 = signal not available (SNA)";
CM_ SG_ 552 EPBR_driverIsLeavingLocal "Right electric parking brake: driver is leaving local";
CM_ SG_ 552 EPBR_driverIsLeavingAnySpeedLoca "Right electric parking brake: driver is leaving any speed local";
CM_ SG_ 552 EPBR_internalCDPRequest "Right electric parking brake: internal CDP request";
CM_ SG_ 552 EPBR_esmSpeedClass "Right electric parking brake: esm speed class";
CM_ SG_ 552 EPBR_learnedEpbConfig "Right electric parking brake: learned epb config";
CM_ SG_ 552 EPBR_internalStatusCounter "Right electric parking brake: internal status counter";
CM_ SG_ 552 EPBR_internalStatusChecksum "Right electric parking brake: internal status checksum";
CM_ BO_ 1662 "EVSE ECU message: iso tp to veh; frame length from the layout, not yet observed on a vehicle bus";
CM_ SG_ 1662 EVSE_isoTpToVehData "EVSE ECU: iso tp to veh data";
CM_ BO_ 1322 "FC ECU message: alert log; frame length from the layout, not yet observed on a vehicle bus";
CM_ SG_ 1322 FC_alertID "FC ECU: alert ID";
CM_ SG_ 1322 FC_alertType "FC ECU: alert type";
CM_ SG_ 1322 FC_a130_CA_flybackSwOvType "FC ECU: a130 CA flyback sw ov type";
CM_ SG_ 1322 FC_a146_CA_flybackOnTime "FC ECU: a146 CA flyback on time";
CM_ SG_ 1322 FC_a146_CA_flybackV "FC ECU: a146 CA flyback v";
CM_ SG_ 1322 FC_a146_CA_flybackTargetV "FC ECU: a146 CA flyback target v";
CM_ SG_ 1322 FC_a159_CA_wdtTaskList1 "FC ECU: a159 CA wdt task list1";
CM_ SG_ 1322 FC_a159_CA_wdtTaskList2 "FC ECU: a159 CA wdt task list2";
CM_ BO_ 895 "FC ECU message: alert matrix3; frame length from the layout, not yet observed on a vehicle bus";
CM_ SG_ 895 FC_a129_CA_flyback_HW_OC "FC ECU: a129 CA flyback HW OC";
CM_ SG_ 895 FC_a130_CA_flyback_SW_OV "FC ECU: a130 CA flyback SW OV";
CM_ SG_ 895 FC_a131_CA_flyback_HW_OV "FC ECU: a131 CA flyback HW OV";
CM_ SG_ 895 FC_a132_CA_bmsMia "FC ECU: a132 CA bms mia";
CM_ SG_ 895 FC_a133_CA_evseMia "FC ECU: a133 CA evse mia";
CM_ SG_ 895 FC_a134_CA_vehTxBufOvf "FC ECU: a134 CA veh tx buf ovf";
CM_ SG_ 895 FC_a135_CA_vehRxBufOvf "FC ECU: a135 CA veh rx buf ovf";
CM_ SG_ 895 FC_a136_CA_evseTxBufOvf "FC ECU: a136 CA evse tx buf ovf";
CM_ SG_ 895 FC_a137_CA_evseRxBufOvf "FC ECU: a137 CA evse rx buf ovf";
CM_ SG_ 895 FC_a138_CA_hwProxTrip "FC ECU: a138 CA hw prox trip";
CM_ SG_ 895 FC_a139_CA_ss2NotLow "FC ECU: a139 CA ss2 not low";
CM_ SG_ 895 FC_a140_CA_bmsIncompatible "FC ECU: a140 CA bms incompatible";
CM_ SG_ 895 FC_a141_CA_vehConn_OT "FC ECU: a141 CA veh conn OT";
CM_ SG_ 895 FC_a142_CA_evseConn_OT "FC ECU: a142 CA evse conn OT";
CM_ SG_ 895 FC_a143_CA_pcb_OT "FC ECU: a143 CA pcb OT";
CM_ SG_ 895 FC_a144_CA_flybackUnstable "FC ECU: a144 CA flyback unstable";
CM_ SG_ 895 FC_a145_CA_flybackDataStale "FC ECU: a145 CA flyback data stale";
CM_ SG_ 895 FC_a146_CA_flybackBusLoadHi "FC ECU: a146 CA flyback bus load hi";
CM_ SG_ 895 FC_a147_CA_vehConn_UT "FC ECU: a147 CA veh conn UT";
CM_ SG_ 895 FC_a148_CA_evseConn_UT "FC ECU: a148 CA evse conn UT";
CM_ SG_ 895 FC_a149_CA_pcb_UT "FC ECU: a149 CA pcb UT";
CM_ SG_ 895 FC_a150_CA_vehToEvseDeltaHi "FC ECU: a150 CA veh to evse delta hi";
CM_ SG_ 895 FC_a151_CA_vehToEvseDeltaLo "FC ECU: a151 CA veh to evse delta lo";
CM_ SG_ 895 FC_a152_CA_vehToPcbDeltaHi "FC ECU: a152 CA veh to pcb delta hi";
CM_ SG_ 895 FC_a153_CA_evseToPcbDeltaHi "FC ECU: a153 CA evse to pcb delta hi";
CM_ SG_ 895 FC_a154_CA_vehToPcbDeltaLo "FC ECU: a154 CA veh to pcb delta lo";
CM_ SG_ 895 FC_a155_CA_evseToPcbDeltaLo "FC ECU: a155 CA evse to pcb delta lo";
CM_ SG_ 895 FC_a156_CA_flybackRunTimeout "FC ECU: a156 CA flyback run timeout";
CM_ SG_ 895 FC_a157_CA_unused "FC ECU: a157 CA unused";
CM_ SG_ 895 FC_a158_CA_evseOverCurrent "FC ECU: a158 CA evse over current";
CM_ SG_ 895 FC_a159_CA_wdtExpired "FC ECU: a159 CA wdt expired";
CM_ SG_ 895 FC_a160_CA_ss2Deasserted "FC ECU: a160 CA ss2 deasserted";
CM_ SG_ 895 FC_a161_CA_vehTempHiFoldBk "FC ECU: a161 CA veh temp hi fold bk";
CM_ SG_ 895 FC_a162_CA_evseTempHiFoldBk "FC ECU: a162 CA evse temp hi fold bk";
CM_ SG_ 895 FC_a163_CA_pcbTempHiFoldBk "FC ECU: a163 CA pcb temp hi fold bk";
CM_ SG_ 895 FC_a164_CA_proxDisconnected "FC ECU: a164 CA prox disconnected";
CM_ SG_ 895 FC_a165_CA_evseConnUnlocked "FC ECU: a165 CA evse conn unlocked";
CM_ SG_ 895 FC_a166_CA_vehConnUnlocked "FC ECU: a166 CA veh conn unlocked";
CM_ SG_ 895 FC_a167_CA_isoVoltageLow "FC ECU: a167 CA iso voltage low";
CM_ SG_ 895 FC_a168_CA_proxTimeout "FC ECU: a168 CA prox timeout";
CM_ SG_ 895 FC_a169_CA_pilotAcceptTimeout "FC ECU: a169 CA pilot accept timeout";
CM_ SG_ 895 FC_a170_CA_vehDataTimeout "FC ECU: a170 CA veh data timeout";
CM_ SG_ 895 FC_a171_CA_vehConLockTimeout "FC ECU: a171 CA veh con lock timeout";
CM_ SG_ 895 FC_a172_CA_ss2LowTimeout "FC ECU: a172 CA ss2 low timeout";
CM_ SG_ 895 FC_a173_CA_evseDataTimeout "FC ECU: a173 CA evse data timeout";
CM_ SG_ 895 FC_a174_CA_vehReadyTimeout "FC ECU: a174 CA veh ready timeout";
CM_ SG_ 895 FC_a175_CA_evseIsoTestTimeout "FC ECU: a175 CA evse iso test timeout";
CM_ SG_ 895 FC_a176_CA_chargingBusTimeout "FC ECU: a176 CA charging bus timeout";
CM_ SG_ 895 FC_a177_CA_bmsCtrCloseTimeout "FC ECU: a177 CA bms ctr close timeout";
CM_ SG_ 895 FC_a178_CA_evseStartTimeout "FC ECU: a178 CA evse start timeout";
CM_ SG_ 895 FC_a179_CA_startupProblem "FC ECU: a179 CA startup problem";
CM_ SG_ 895 FC_a180_CA_chargingProblem "FC ECU: a180 CA charging problem";
CM_ SG_ 895 FC_a181_CA_vRegBrownout "FC ECU: a181 CA v reg brownout";
CM_ SG_ 895 FC_a182_CA_evseChrMalfunc "FC ECU: a182 CA evse chr malfunc";
CM_ SG_ 895 FC_a183_CA_evseBatIncompat "FC ECU: a183 CA evse bat incompat";
CM_ SG_ 895 FC_a184_CA_evseBatMalfunc "FC ECU: a184 CA evse bat malfunc";
CM_ SG_ 895 FC_a185_CA_vehReadyDeasserted "FC ECU: a185 CA veh ready deasserted";
CM_ SG_ 895 FC_a186_CA_fcContOpenTimeout "FC ECU: a186 CA fc cont open timeout";
CM_ SG_ 895 FC_a187_CA_evseConLockTimeout "FC ECU: a187 CA evse con lock timeout";
CM_ BO_ 927 "FC ECU message: alert matrix4; frame length from the layout, not yet observed on a vehicle bus";
CM_ SG_ 927 FC_a193_FCAlertPlaceholder "FC ECU: a193 FC alert placeholder";
CM_ BO_ 958 "FC ECU message: alert matrix5; frame length from the layout, not yet observed on a vehicle bus";
CM_ SG_ 958 FC_a257_GB_bmsMia "FC ECU: a257 GB bms mia";
CM_ SG_ 958 FC_a258_GB_evseMia "FC ECU: a258 GB evse mia";
CM_ SG_ 958 FC_a259_GB_vehTxBufOvf "FC ECU: a259 GB veh tx buf ovf";
CM_ SG_ 958 FC_a260_GB_vehRxBufOvf "FC ECU: a260 GB veh rx buf ovf";
CM_ SG_ 958 FC_a261_GB_evseTxBufOvf "FC ECU: a261 GB evse tx buf ovf";
CM_ SG_ 958 FC_a262_GB_evseRxBufOvf "FC ECU: a262 GB evse rx buf ovf";
CM_ SG_ 958 FC_a263_GB_hwProxTrip "FC ECU: a263 GB hw prox trip";
CM_ SG_ 958 FC_a264_GB_timeoutCHM "FC ECU: a264 GB timeout CHM";
CM_ SG_ 958 FC_a265_GB_bmsIncompatible "FC ECU: a265 GB bms incompatible";
CM_ SG_ 958 FC_a266_GB_negPin_OT "FC ECU: a266 GB neg pin OT";
CM_ SG_ 958 FC_a267_GB_posPin_OT "FC ECU: a267 GB pos pin OT";
CM_ SG_ 958 FC_a268_GB_pcb_OT "FC ECU: a268 GB pcb OT";
CM_ SG_ 958 FC_a269_GB_timeoutCRM "FC ECU: a269 GB timeout CRM";
CM_ SG_ 958 FC_a270_GB_timeoutCML "FC ECU: a270 GB timeout CML";
CM_ SG_ 958 FC_a271_GB_timeoutCRO "FC ECU: a271 GB timeout CRO";
CM_ SG_ 958 FC_a272_GB_negToPosDeltaHi "FC ECU: a272 GB neg to pos delta hi";
CM_ SG_ 958 FC_a273_GB_negToPosDeltaLo "FC ECU: a273 GB neg to pos delta lo";
CM_ SG_ 958 FC_a274_GB_negToPcbDeltaHi "FC ECU: a274 GB neg to pcb delta hi";
CM_ SG_ 958 FC_a275_GB_posToPcbDeltaHi "FC ECU: a275 GB pos to pcb delta hi";
CM_ SG_ 958 FC_a276_GB_negToPcbDeltaLo "FC ECU: a276 GB neg to pcb delta lo";
CM_ SG_ 958 FC_a277_GB_posToPcbDeltaLo "FC ECU: a277 GB pos to pcb delta lo";
CM_ SG_ 958 FC_a278_GB_timeoutCCS "FC ECU: a278 GB timeout CCS";
CM_ SG_ 958 FC_a279_GB_evseOverCurrent "FC ECU: a279 GB evse over current";
CM_ SG_ 958 FC_a280_GB_retryLimitExceeded "FC ECU: a280 GB retry limit exceeded";
CM_ SG_ 958 FC_a281_GB_evseOutOfService "FC ECU: a281 GB evse out of service";
CM_ SG_ 958 FC_a282_GB_negTempHiFoldBk "FC ECU: a282 GB neg temp hi fold bk";
CM_ SG_ 958 FC_a283_GB_posTempHiFoldBk "FC ECU: a283 GB pos temp hi fold bk";
CM_ SG_ 958 FC_a284_GB_pcbTempHiFoldBk "FC ECU: a284 GB pcb temp hi fold bk";
CM_ SG_ 958 FC_a285_GB_proxDisconnected "FC ECU: a285 GB prox disconnected";
CM_ SG_ 958 FC_a286_GB_evseConnUnlocked "FC ECU: a286 GB evse conn unlocked";
CM_ SG_ 958 FC_a287_GB_vehConnUnlocked "FC ECU: a287 GB veh conn unlocked";
CM_ SG_ 958 FC_a288_GB_evseAbnormalStopReq "FC ECU: a288 GB evse abnormal stop req";
CM_ SG_ 958 FC_a289_GB_proxTimeout "FC ECU: a289 GB prox timeout";
CM_ SG_ 958 FC_a290_GB_pilotAcceptTimeout "FC ECU: a290 GB pilot accept timeout";
CM_ SG_ 958 FC_a291_GB_vehDataTimeout "FC ECU: a291 GB veh data timeout";
CM_ SG_ 958 FC_a292_GB_vehConLockTimeout "FC ECU: a292 GB veh con lock timeout";
CM_ SG_ 958 FC_a293_GB_proxRationality "FC ECU: a293 GB prox rationality";
CM_ SG_ 958 FC_a294_GB_unused "FC ECU: a294 GB unused";
CM_ SG_ 958 FC_a295_GB_pilotRationality "FC ECU: a295 GB pilot rationality";
CM_ SG_ 958 FC_a296_GB_invalidPilotTransitio "FC ECU: a296 GB invalid pilot transitio";
CM_ SG_ 958 FC_a297_GB_unused "FC ECU: a297 GB unused";
CM_ SG_ 958 FC_a298_GB_bmsCtrCloseTimeout "FC ECU: a298 GB bms ctr close timeout";
CM_ SG_ 958 FC_a299_GB_evseReadyTimeout "FC ECU: a299 GB evse ready timeout";
CM_ SG_ 958 FC_a300_GB_unused "FC ECU: a300 GB unused";
CM_ SG_ 958 FC_a301_GB_unused "FC ECU: a301 GB unused";
CM_ SG_ 958 FC_a302_GB_unused "FC ECU: a302 GB unused";
CM_ SG_ 958 FC_a303_GB_negRecogTimeout "FC ECU: a303 GB neg recog timeout";
CM_ SG_ 958 FC_a304_GB_unused "FC ECU: a304 GB unused";
CM_ SG_ 958 FC_a305_GB_posRecogTimeout "FC ECU: a305 GB pos recog timeout";
CM_ SG_ 958 FC_a306_GB_vehReadyDeasserted "FC ECU: a306 GB veh ready deasserted";
CM_ SG_ 958 FC_a307_GB_fcContOpenTimeout "FC ECU: a307 GB fc cont open timeout";
CM_ SG_ 958 FC_a308_GB_evseConLockTimeout "FC ECU: a308 GB evse con lock timeout";
CM_ SG_ 958 FC_a309_GB_unused "FC ECU: a309 GB unused";
CM_ SG_ 958 FC_a310_GB_unused "FC ECU: a310 GB unused";
CM_ SG_ 958 FC_a311_GB_battParamsTimeout "FC ECU: a311 GB batt params timeout";
CM_ SG_ 958 FC_a312_GB_evseLimitsTimeout "FC ECU: a312 GB evse limits timeout";
CM_ SG_ 958 FC_a313_GB_inputVoltageRailOv "FC ECU: a313 GB input voltage rail ov";
CM_ BO_ 990 "FC ECU message: alert matrix6; frame length from the layout, not yet observed on a vehicle bus";
CM_ SG_ 990 FC_a321_FCAlertPlaceholder "FC ECU: a321 FC alert placeholder";
CM_ BO_ 1117 "FC ECU message: evse billing; frame length from the layout, not yet observed on a vehicle bus";
CM_ SG_ 1117 FC_evseBillingDataSelect "FC ECU: evse billing data select";
CM_ SG_ 1117 FC_evseBillingEnergy "FC ECU: evse billing energy";
CM_ SG_ 1117 FC_evseMeterPower "FC ECU: evse meter power";
CM_ SG_ 1117 FC_evseMeterCurrent "FC ECU: evse meter current";
CM_ SG_ 1117 FC_evseMeterVoltage "FC ECU: evse meter voltage";
CM_ SG_ 1117 FC_evseMeterFwGitHash "FC ECU: evse meter fw git hash";
CM_ BO_ 1334 "FC ECU message: evse billing2; frame length from the layout, not yet observed on a vehicle bus";
CM_ SG_ 1334 FC_evseBilling2DataSelect "FC ECU: evse billing2 data select";
CM_ SG_ 1334 FC_evsePpuEnabled "FC ECU: evse ppu enabled";
CM_ SG_ 1334 FC_evseBillingEnergyHighRes "FC ECU: evse billing energy high res; raw 16777215 = signal not available (SNA)";
CM_ BO_ 1303 "FC ECU message: identifier; frame length from the layout, not yet observed on a vehicle bus";
CM_ SG_ 1303 FC_id "Fast charger identifying number";
CM_ SG_ 1303 FC_sessionId "Fast charge session ID";
CM_ BO_ 1310 "FC ECU message: info; frame length from the layout, not yet observed on a vehicle bus";
CM_ SG_ 1310 FC_infoIndex "FC ECU: info index";
CM_ SG_ 1310 FC_infoBuildType "FC ECU: info build type";
CM_ SG_ 1310 FC_infoBuildConfigID "FC ECU: info build config ID";
CM_ SG_ 1310 FC_infoHardwareID "FC ECU: info hardware ID";
CM_ SG_ 1310 FC_infoComponentID "FC ECU: info component ID";
CM_ SG_ 1310 FC_infoPcbaID "FC ECU: info pcba ID";
CM_ SG_ 1310 FC_infoAssemblyID "FC ECU: info assembly ID";
CM_ SG_ 1310 FC_infoUsageID "FC ECU: info usage ID";
CM_ SG_ 1310 FC_infoSubUsageID "FC ECU: info sub usage ID";
CM_ SG_ 1310 FC_infoApplicationCRC "FC ECU: info application CRC";
CM_ SG_ 1310 FC_infoAppGitHashBytes "FC ECU: info app git hash bytes";
CM_ SG_ 1310 FC_infoBootGitHashBytes "FC ECU: info boot git hash bytes";
CM_ SG_ 1310 FC_infoPlatformType "FC ECU: info platform type";
CM_ SG_ 1310 FC_infoMajorVersion "Fast charger firmware major version number";
CM_ SG_ 1310 FC_infoBranchOrigin "Fast charger branch origin";
CM_ SG_ 1310 FC_infoMaturity "Fast charger firmware info";
CM_ SG_ 1310 FC_infoHardwareRevision "FC ECU: info hardware revision";
CM_ SG_ 1310 FC_partNumChar01 "FC ECU: part num char01";
CM_ SG_ 1310 FC_partNumChar02 "FC ECU: part num char02";
CM_ SG_ 1310 FC_partNumChar03 "FC ECU: part num char03";
CM_ SG_ 1310 FC_partNumChar04 "FC ECU: part num char04";
CM_ SG_ 1310 FC_partNumChar05 "FC ECU: part num char05";
CM_ SG_ 1310 FC_partNumChar06 "FC ECU: part num char06";
CM_ SG_ 1310 FC_partNumChar07 "FC ECU: part num char07";
CM_ SG_ 1310 FC_partNumChar08 "FC ECU: part num char08";
CM_ SG_ 1310 FC_partNumChar09 "FC ECU: part num char09";
CM_ SG_ 1310 FC_partNumChar10 "FC ECU: part num char10";
CM_ SG_ 1310 FC_partNumChar11 "FC ECU: part num char11";
CM_ SG_ 1310 FC_partNumChar12 "FC ECU: part num char12";
CM_ SG_ 1310 FC_partNumChar13 "FC ECU: part num char13";
CM_ SG_ 1310 FC_partNumChar14 "FC ECU: part num char14";
CM_ SG_ 1310 FC_partNumChar15 "FC ECU: part num char15";
CM_ SG_ 1310 FC_partNumChar16 "FC ECU: part num char16";
CM_ SG_ 1310 FC_partNumChar17 "FC ECU: part num char17";
CM_ SG_ 1310 FC_partNumChar18 "FC ECU: part num char18";
CM_ SG_ 1310 FC_partNumChar19 "FC ECU: part num char19";
CM_ SG_ 1310 FC_partNumChar20 "FC ECU: part num char20";
CM_ BO_ 580 "FC ECU message: limits; frame length from the layout, not yet observed on a vehicle bus";
CM_ SG_ 580 FC_powerLimit "Instantaneous power charger can deliver; raw 8191 = signal not available (SNA)";
CM_ SG_ 580 FC_currentLimit "Instantaneous current charger can deliver; raw 8191 = signal not available (SNA)";
CM_ SG_ 580 FC_maxVoltageLimit "Max voltage charger can deliver. 600/65536; raw 8191 = signal not available (SNA)";
CM_ SG_ 580 FC_minVoltageLimit "Measures Electric Vehicle Supply Equipment (EVSE) minimum current limit; raw 8191 = signal not available (SNA)";
CM_ BO_ 702 "FC ECU message: limits high power; frame length from the layout, not yet observed on a vehicle bus";
CM_ SG_ 702 FC_powerLimit_value "Instantaneous power charger can deliver. Mantissa portion of extended range version of legacy signal, used with protocol versions 9+. FC_powerLimit = value * 10^exp; raw 32768 = signal not available (SNA)";
CM_ SG_ 702 FC_currentLimit_value "FC ECU: current limit value; raw 32768 = signal not available (SNA)";
CM_ SG_ 702 FC_minVoltageLimit_value "FC ECU: min voltage limit value; raw 32768 = signal not available (SNA)";
CM_ SG_ 702 FC_powerLimit_exp "Instantaneous power charger can deliver. Exponent portion of extended ragne version of legacy signal, used with protocol versions 9+. FC_powerLimit = value * 10^exp.";
CM_ SG_ 702 FC_currentLimit_exp "FC ECU: current limit exp";
CM_ SG_ 702 FC_minVoltageLimit_exp "FC ECU: min voltage limit exp";
CM_ BO_ 1345 "FC ECU message: max limits; frame length from the layout, not yet observed on a vehicle bus";
CM_ SG_ 1345 FC_maxPowerLimit "Max power charger can deliver; raw 8191 = signal not available (SNA)";
CM_ SG_ 1345 FC_maxCurrentLimit "Max current charger can deliver; raw 8191 = signal not available (SNA)";
CM_ BO_ 1300 "FC ECU message: serial; frame length from the layout, not yet observed on a vehicle bus";
CM_ SG_ 1300 FC_serialDataSelect "FC ECU: serial data select";
CM_ SG_ 1300 FC_serialChar01 "FC ECU: serial char01";
CM_ SG_ 1300 FC_serialChar02 "FC ECU: serial char02";
CM_ SG_ 1300 FC_serialChar03 "FC ECU: serial char03";
CM_ SG_ 1300 FC_serialChar04 "FC ECU: serial char04";
CM_ SG_ 1300 FC_serialChar05 "FC ECU: serial char05";
CM_ SG_ 1300 FC_serialChar06 "FC ECU: serial char06";
CM_ SG_ 1300 FC_serialChar07 "FC ECU: serial char07";
CM_ SG_ 1300 FC_serialChar08 "FC ECU: serial char08";
CM_ SG_ 1300 FC_serialChar09 "FC ECU: serial char09";
CM_ SG_ 1300 FC_serialChar10 "FC ECU: serial char10";
CM_ SG_ 1300 FC_serialChar11 "FC ECU: serial char11";
CM_ SG_ 1300 FC_serialChar12 "FC ECU: serial char12";
CM_ SG_ 1300 FC_serialChar13 "FC ECU: serial char13";
CM_ SG_ 1300 FC_serialChar14 "FC ECU: serial char14";
CM_ SG_ 1300 FC_serialChar15 "FC ECU: serial char15";
CM_ SG_ 1300 FC_serialChar16 "FC ECU: serial char16";
CM_ SG_ 1300 FC_serialChar17 "FC ECU: serial char17";
CM_ BO_ 532 "FC ECU message: status; frame length from the layout, not yet observed on a vehicle bus";
CM_ SG_ 532 FC_protocolVersion "FC ECU: protocol version";
CM_ SG_ 532 FC_statusCode "Fast charger status code; raw 0 = signal not available (SNA)";
CM_ SG_ 532 FC_deprecated1 "FC ECU: deprecated1";
CM_ SG_ 532 FC_deprecated2 "FC ECU: deprecated2";
CM_ SG_ 532 FC_deprecated3 "FC ECU: deprecated3";
CM_ SG_ 532 FC_adapterLocked "Indicates if the DC adapter is secure or not";
CM_ SG_ 532 FC_minCurrentLimit "Fast charger min current limit";
CM_ SG_ 532 FC_type "Type of EVSE connected that supports digital communication; raw 7 = signal not available (SNA)";
CM_ SG_ 532 FC_dcCurrent "Fast charger DC output current";
CM_ SG_ 532 FC_postID "Fast charger charging post ID; raw 3 = signal not available (SNA)";
CM_ SG_ 532 FC_dcVoltage "Fast charger DC voltage";
CM_ SG_ 532 FC_leakageTestNotSupported "Indicates if the S/X leakage test can be run on this supercharger";
CM_ SG_ 532 FC_dischargeSupported "FC ECU: discharge supported";
CM_ BO_ 533 "FC ECU message: status2; frame length from the layout, not yet observed on a vehicle bus";
CM_ SG_ 533 FC_externalIsolationResistance "Fast charger external isolation resistance; raw 255 = signal not available (SNA)";
CM_ BO_ 535 "FC ECU message: status3; frame length from the layout, not yet observed on a vehicle bus";
CM_ SG_ 535 FC_status3DataSelect "FC ECU: status3 data select";
CM_ SG_ 535 FC_status3DummySig "FC ECU: status3 dummy sig";
CM_ SG_ 535 FC_class "FC ECU: class; raw 0 = signal not available (SNA)";
CM_ SG_ 535 FC_brand "Fast charger brand; raw 0 = signal not available (SNA)";
CM_ SG_ 535 FC_coolingType "Type of cooling used for the supercharger; raw 0 = signal not available (SNA)";
CM_ SG_ 535 FC_uiStopType "Type of stop type supported from the UI; raw 0 = signal not available (SNA)";
CM_ SG_ 535 FC_emergencyShutdownSupported "Indicates if the supercharger supports fast emergency shutdown requests from vehicle";
CM_ SG_ 535 FC_generation "Hardware generation of the Tesla EVSE; raw 0 = signal not available (SNA)";
CM_ BO_ 1650 "HCML ECU message: info; frame length observed on a vehicle bus";
CM_ SG_ 1650 VC_hcmlInfoIndex "HCML ECU: hcml info index";
CM_ SG_ 1650 VC_infoHCMLBuildConfigId "HCM Diagnostic Field.";
CM_ SG_ 1650 VC_leftHeadlampLMMVariant "Reports the detected left headlamp LED Matrix Manager (LMM) variant; raw 0 = signal not available (SNA)";
CM_ SG_ 1650 VC_infoHCMLAssemblyId "HCM Diagnostic Field.";
CM_ SG_ 1650 VC_infoHCMLPcbaId "HCM Diagnostic Field.";
CM_ SG_ 1650 VC_infoHCMLUsageId "HCM Diagnostic Field.";
CM_ BO_ 1980 "HCMR ECU message: info; frame length observed on a vehicle bus";
CM_ SG_ 1980 VC_hcmrInfoIndex "HCMR ECU: hcmr info index";
CM_ SG_ 1980 VC_infoHCMRBuildConfigId "HCM Diagnostic Field.";
CM_ SG_ 1980 VC_rightHeadlampLMMVariant "Reports the detected right headlamp LED Matrix Manager (LMM) variant; raw 0 = signal not available (SNA)";
CM_ SG_ 1980 VC_infoHCMRAssemblyId "HCM Diagnostic Field.";
CM_ SG_ 1980 VC_infoHCMRPcbaId "HCM Diagnostic Field.";
CM_ SG_ 1980 VC_infoHCMRUsageId "HCM Diagnostic Field.";
CM_ BO_ 785 "Vector__XXX ECU message: 0x311; frame length observed on a vehicle bus";
CM_ SG_ 785 HVBMS_0x311_b0_10 "Battery computer field at bits 0-9; position from firmware, meaning not yet known";
CM_ SG_ 785 HVBMS_0x311_b10_1 "Battery computer field at bits 10-10; position from firmware, meaning not yet known";
CM_ SG_ 785 HVBMS_0x311_b11_1 "Battery computer field at bits 11-11; position from firmware, meaning not yet known";
CM_ SG_ 785 HVBMS_0x311_b12_1 "Battery computer field at bits 12-12; position from firmware, meaning not yet known";
CM_ SG_ 785 HVBMS_0x311_b13_1 "Battery computer field at bits 13-13; position from firmware, meaning not yet known";
CM_ BO_ 1106 "Vector__XXX ECU message: 0x452; frame length observed on a vehicle bus";
CM_ SG_ 1106 HVBMS_0x452_b0_10 "Battery computer field at bits 0-9; position from firmware, meaning not yet known";
CM_ BO_ 554 "High-voltage processor (pack contactor and isolation controller) message: hvs control; frame length observed on a vehicle bus";
CM_ SG_ 554 HVP_dcLinkVoltageRequest "High-voltage processor (pack contactor and isolation controller): dc link voltage request";
CM_ SG_ 554 HVP_pcsControlRequest "The operating state that the HVP would like the PCS to be in";
CM_ SG_ 554 HVP_pcsChargeHwEnabled "The state of the PCS's charge enable line";
CM_ SG_ 554 HVP_pcsDcdcHwEnabled "The state of the PCS's DCDC enable line";
CM_ SG_ 554 HVP_dcLinkVoltageFiltered "High-voltage processor (pack contactor and isolation controller): dc link voltage filtered; raw 1498 = signal not available (SNA)";
CM_ BO_ 784 "High-voltage processor (pack contactor and isolation controller) message: info; frame length observed on a vehicle bus";
CM_ SG_ 784 HVP_infoIndex "High-voltage processor (pack contactor and isolation controller): info index";
CM_ SG_ 784 HVP_buildType "High-voltage processor (pack contactor and isolation controller): build type";
CM_ SG_ 784 HVP_buildConfigId "High-voltage processor (pack contactor and isolation controller): build config id";
CM_ SG_ 784 HVP_hardwareId "High-voltage processor (pack contactor and isolation controller): hardware id";
CM_ SG_ 784 HVP_componentId "High-voltage processor (pack contactor and isolation controller): component id";
CM_ SG_ 784 HVP_pcbaId "High-voltage processor (pack contactor and isolation controller): pcba id";
CM_ SG_ 784 HVP_assemblyId "HVP's assigned assembly ID";
CM_ SG_ 784 HVP_usageId "HVP's assigned usage ID";
CM_ SG_ 784 HVP_subUsageId "HVP's assigned subusage ID";
CM_ SG_ 784 HVP_platformType "High-voltage processor (pack contactor and isolation controller): platform type";
CM_ SG_ 784 HVP_appCrc "High-voltage processor (pack contactor and isolation controller): app crc";
CM_ SG_ 784 HVP_appGitHash "High-voltage processor (pack contactor and isolation controller): app git hash";
CM_ SG_ 784 HVP_bootGitHash "High-voltage processor (pack contactor and isolation controller): boot git hash";
CM_ SG_ 784 HVP_bootUdsProtoVersion "High-voltage processor (pack contactor and isolation controller): boot uds proto version";
CM_ SG_ 784 HVP_bootCrc "High-voltage processor (pack contactor and isolation controller): boot crc";
CM_ BO_ 1914 "High-voltage processor (pack contactor and isolation controller) message: log1hz; frame length observed on a vehicle bus";
CM_ SG_ 1914 HVP_log1HzIndex "High-voltage processor (pack contactor and isolation controller): log1 hz index";
CM_ SG_ 1914 HVP_bmbAsicType "The BMB Asic type being used by this battery pack for reading brick data";
CM_ SG_ 1914 HVP_shuntCurrentAuxLog "High-voltage processor (pack contactor and isolation controller): shunt current aux log";
CM_ SG_ 1914 HVP_pyroSquibResistance "The pyro resistance measured on attempt to close contactor or by the Pyro selftest; raw 65535 = signal not available (SNA)";
CM_ SG_ 1914 HVP_shuntAsicChipXCoordinate "High-voltage processor (pack contactor and isolation controller): shunt asic chip x coordinate";
CM_ SG_ 1914 HVP_shuntAsicChipYCoordinate "High-voltage processor (pack contactor and isolation controller): shunt asic chip y coordinate";
CM_ SG_ 1914 HVP_hvilCalType "High-voltage processor (pack contactor and isolation controller): hvil cal type";
CM_ SG_ 1914 HVP_gpioPcsDcdcPwmEnable "High-voltage processor (pack contactor and isolation controller): gpio pcs dcdc pwm enable";
CM_ SG_ 1914 HVP_gpioPcsChargePwmEnable "High-voltage processor (pack contactor and isolation controller): gpio pcs charge pwm enable";
CM_ SG_ 1914 HVP_gpioPcsEnable "HVP GPIO control for PCS logic power enable line";
CM_ SG_ 1914 HVP_shuntAsicChipWaferNumber "High-voltage processor (pack contactor and isolation controller): shunt asic chip wafer number";
CM_ SG_ 1914 HVP_energyReserveMin "a lowest energy reserve value measured over sliding window";
CM_ SG_ 1914 HVP_energyReserveMax "a highest energy reserve value measured over sliding window";
CM_ SG_ 1914 HVP_energyReserveAvg "an average energy reserve value measured over sliding window";
CM_ BO_ 941 "ICR ECU message: info; frame length from the layout, not yet observed on a vehicle bus";
CM_ SG_ 941 ICR_infoIndex "ICR ECU: info index";
CM_ SG_ 941 ICR_infoBuildType "ICR ECU: info build type";
CM_ SG_ 941 ICR_infoPcbaId "ICR ECU: info pcba id";
CM_ SG_ 941 ICR_infoAssemblyId "ICR ECU: info assembly id";
CM_ SG_ 941 ICR_infoUsageId "ICR ECU: info usage id";
CM_ SG_ 941 ICR_infoAppCrc "ICR ECU: info app crc";
CM_ SG_ 941 ICR_infoBoardPartNumber17 "ICR ECU: info board part number17";
CM_ SG_ 941 ICR_infoBoardPartNumber814 "ICR ECU: info board part number814";
CM_ SG_ 941 ICR_infoBoardPartNumber1520 "ICR ECU: info board part number1520";
BA_DEF_ "BusType" STRING;
BA_DEF_ "DBName" STRING;
BA_DEF_ "Baudrate" INT 0 1000000;
BA_DEF_ "BaudrateCANFD" INT 0 16000000;
BA_DEF_ "Manufacturer" STRING;
BA_DEF_ "FirmwareVersion" STRING;
BA_DEF_ "VehicleModel" STRING;
BA_DEF_ BU_ "ECU" STRING;
BA_DEF_ BO_ "GenMsgCycleTime" INT 0 3600000;
BA_DEF_ BO_ "GenMsgSendType" ENUM "Cyclic","NotUsed","NotUsed","NotUsed","NotUsed","NotUsed","NotUsed","IfActive","NoMsgSendType","NotUsed";
BA_DEF_ BO_ "VFrameFormat" ENUM "StandardCAN","ExtendedCAN","reserved","J1939PG","reserved","reserved","reserved","reserved","reserved","reserved","reserved","reserved","reserved","reserved","StandardCAN_FD","ExtendedCAN_FD";
BA_DEF_ BO_ "CANFD_BRS" ENUM "0","1";
BA_DEF_ SG_ "GenSigSNA" STRING;
BA_DEF_ SG_ "SystemSignalLongSymbol" STRING;
BA_DEF_ SG_ "Confidence" ENUM "validated","plausible","layout-only","contradicted";
BA_DEF_DEF_ "BusType" "CAN";
BA_DEF_DEF_ "DBName" "";
BA_DEF_DEF_ "Baudrate" 500000;
BA_DEF_DEF_ "BaudrateCANFD" 2000000;
BA_DEF_DEF_ "Manufacturer" "";
BA_DEF_DEF_ "FirmwareVersion" "";
BA_DEF_DEF_ "VehicleModel" "";
BA_DEF_DEF_ "ECU" "";
BA_DEF_DEF_ "GenMsgCycleTime" 0;
BA_DEF_DEF_ "GenMsgSendType" "NoMsgSendType";
BA_DEF_DEF_ "VFrameFormat" "StandardCAN";
BA_DEF_DEF_ "CANFD_BRS" "1";
BA_DEF_DEF_ "GenSigSNA" "";
BA_DEF_DEF_ "SystemSignalLongSymbol" "";
BA_DEF_DEF_ "Confidence" "layout-only";
BA_ "DBName" "AllModels_VEH";
BA_ "Manufacturer" "Tesla";
BA_ "FirmwareVersion" "2025.20.8";
BA_ "VehicleModel" "Model 3 / Model Y";
BA_ "ECU" BU_ BMS "BMS";
BA_ "ECU" BU_ CC "CC";
BA_ "ECU" BU_ CMP "CMP";
BA_ "ECU" BU_ CMPD "CMPD";
BA_ "ECU" BU_ CP "CP";
BA_ "ECU" BU_ DAS "DAS";
BA_ "ECU" BU_ DI "DI";
BA_ "ECU" BU_ DIF "DIF";
BA_ "ECU" BU_ DIR "DIR";
BA_ "ECU" BU_ EPBL "EPBL";
BA_ "ECU" BU_ EPBR "EPBR";
BA_ "ECU" BU_ EVSE "EVSE";
BA_ "ECU" BU_ FC "FC";
BA_ "ECU" BU_ GTW "GTW";
BA_ "ECU" BU_ HCML "HCML";
BA_ "ECU" BU_ HCMR "HCMR";
BA_ "ECU" BU_ HVP "HVP";
BA_ "ECU" BU_ ICR "ICR";
BA_ "ECU" BU_ PCS "PCS";
BA_ "ECU" BU_ PM "PM";
BA_ "ECU" BU_ PMF "PMF";
BA_ "ECU" BU_ PMR "PMR";
BA_ "ECU" BU_ PTC "PTC";
BA_ "ECU" BU_ SCCM "SCCM";
BA_ "ECU" BU_ SCM "SCM";
BA_ "ECU" BU_ SCS "SCS";
BA_ "ECU" BU_ SDCR "SDCR";
BA_ "ECU" BU_ TAS "TAS";
BA_ "ECU" BU_ UMC "UMC";
BA_ "ECU" BU_ VC "VC";
BA_ "ECU" BU_ VCFRONT "VCFRONT";
BA_ "ECU" BU_ VCLEFT "VCLEFT";
BA_ "ECU" BU_ VCRIGHT "VCRIGHT";
BA_ "ECU" BU_ VCSEC "VCSEC";
BA_ "GenMsgCycleTime" BO_ 818 1000;
BA_ "GenMsgSendType" BO_ 818 0;
BA_ "GenMsgCycleTime" BO_ 722 100;
BA_ "GenMsgSendType" BO_ 722 0;
BA_ "GenMsgCycleTime" BO_ 850 2000;
BA_ "GenMsgSendType" BO_ 850 0;
BA_ "GenMsgCycleTime" BO_ 768 1000;
BA_ "GenMsgSendType" BO_ 768 0;
BA_ "GenMsgCycleTime" BO_ 978 1000;
BA_ "GenMsgSendType" BO_ 978 0;
BA_ "GenMsgCycleTime" BO_ 1010 1000;
BA_ "GenMsgSendType" BO_ 1010 0;
BA_ "GenMsgCycleTime" BO_ 1170 1000;
BA_ "GenMsgSendType" BO_ 1170 0;
BA_ "GenMsgCycleTime" BO_ 1132 1000;
BA_ "GenMsgSendType" BO_ 1132 0;
BA_ "GenMsgCycleTime" BO_ 796 100;
BA_ "GenMsgSendType" BO_ 796 0;
BA_ "GenMsgCycleTime" BO_ 812 1000;
BA_ "GenMsgSendType" BO_ 812 0;
BA_ "GenMsgCycleTime" BO_ 870 1000;
BA_ "GenMsgSendType" BO_ 870 0;
BA_ "GenMsgCycleTime" BO_ 679 100;
BA_ "GenMsgSendType" BO_ 679 0;
BA_ "GenMsgCycleTime" BO_ 867 1000;
BA_ "GenMsgSendType" BO_ 867 0;
BA_ "GenMsgCycleTime" BO_ 1342 1000;
BA_ "GenMsgSendType" BO_ 1342 0;
BA_ "GenMsgCycleTime" BO_ 1001 500;
BA_ "GenMsgSendType" BO_ 1001 0;
BA_ "GenMsgCycleTime" BO_ 741 1000;
BA_ "GenMsgSendType" BO_ 741 0;
BA_ "GenMsgCycleTime" BO_ 1367 1000;
BA_ "GenMsgSendType" BO_ 1367 0;
BA_ "GenMsgCycleTime" BO_ 2005 100;
BA_ "GenMsgSendType" BO_ 2005 0;
BA_ "GenMsgCycleTime" BO_ 917 100;
BA_ "GenMsgSendType" BO_ 917 0;
BA_ "GenMsgCycleTime" BO_ 614 1000;
BA_ "GenMsgSendType" BO_ 614 0;
BA_ "GenMsgCycleTime" BO_ 1495 1000;
BA_ "GenMsgSendType" BO_ 1495 0;
BA_ "GenMsgCycleTime" BO_ 2007 100;
BA_ "GenMsgSendType" BO_ 2007 0;
BA_ "GenMsgCycleTime" BO_ 616 100;
BA_ "GenMsgSendType" BO_ 616 0;
BA_ "GenMsgCycleTime" BO_ 1992 1000;
BA_ "GenMsgSendType" BO_ 1992 0;
BA_ "GenMsgCycleTime" BO_ 648 100;
BA_ "GenMsgSendType" BO_ 648 0;
BA_ "GenMsgCycleTime" BO_ 743 1000;
BA_ "GenMsgSendType" BO_ 743 0;
BA_ "GenMsgCycleTime" BO_ 2024 1000;
BA_ "GenMsgSendType" BO_ 2024 0;
BA_ "GenMsgCycleTime" BO_ 552 100;
BA_ "GenMsgSendType" BO_ 552 0;
BA_ "GenMsgCycleTime" BO_ 895 1000;
BA_ "GenMsgSendType" BO_ 895 0;
BA_ "GenMsgCycleTime" BO_ 927 1000;
BA_ "GenMsgSendType" BO_ 927 0;
BA_ "GenMsgCycleTime" BO_ 958 1000;
BA_ "GenMsgSendType" BO_ 958 0;
BA_ "GenMsgCycleTime" BO_ 990 1000;
BA_ "GenMsgSendType" BO_ 990 0;
BA_ "GenMsgCycleTime" BO_ 1117 1000;
BA_ "GenMsgSendType" BO_ 1117 0;
BA_ "GenMsgCycleTime" BO_ 1334 1000;
BA_ "GenMsgSendType" BO_ 1334 0;
BA_ "GenMsgCycleTime" BO_ 1303 1000;
BA_ "GenMsgSendType" BO_ 1303 0;
BA_ "GenMsgCycleTime" BO_ 1310 1000;
BA_ "GenMsgSendType" BO_ 1310 0;
BA_ "GenMsgCycleTime" BO_ 580 100;
BA_ "GenMsgSendType" BO_ 580 0;
BA_ "GenMsgCycleTime" BO_ 702 100;
BA_ "GenMsgSendType" BO_ 702 0;
BA_ "GenMsgCycleTime" BO_ 1345 100;
BA_ "GenMsgSendType" BO_ 1345 0;
BA_ "GenMsgCycleTime" BO_ 1300 1000;
BA_ "GenMsgSendType" BO_ 1300 0;
BA_ "GenMsgCycleTime" BO_ 532 100;
BA_ "GenMsgSendType" BO_ 532 0;
BA_ "GenMsgCycleTime" BO_ 533 1000;
BA_ "GenMsgSendType" BO_ 533 0;
BA_ "GenMsgCycleTime" BO_ 535 1000;
BA_ "GenMsgSendType" BO_ 535 0;
BA_ "GenMsgCycleTime" BO_ 1650 10000;
BA_ "GenMsgSendType" BO_ 1650 0;
BA_ "GenMsgCycleTime" BO_ 1980 10000;
BA_ "GenMsgSendType" BO_ 1980 0;
BA_ "GenMsgCycleTime" BO_ 554 100;
BA_ "GenMsgSendType" BO_ 554 0;
BA_ "GenMsgCycleTime" BO_ 784 10000;
BA_ "GenMsgSendType" BO_ 784 0;
BA_ "GenMsgCycleTime" BO_ 1914 1000;
BA_ "GenMsgSendType" BO_ 1914 0;
BA_ "GenMsgCycleTime" BO_ 941 10000;
BA_ "GenMsgSendType" BO_ 941 0;
BA_ "Confidence" SG_ 818 BMS_bmbMinMaxMultiplexer 1;
BA_ "Confidence" SG_ 818 BMS_thermistorNumTMin 0;
BA_ "Confidence" SG_ 818 BMS_thermistorNumTMax 0;
BA_ "Confidence" SG_ 818 BMS_thermistorTMax 0;
BA_ "Confidence" SG_ 818 BMS_thermistorTMin 0;
BA_ "Confidence" SG_ 818 BMS_thermistorTAvg 0;
BA_ "Confidence" SG_ 818 BMS_brickVoltageMax 0;
BA_ "Confidence" SG_ 818 BMS_brickVoltageMin 0;
BA_ "Confidence" SG_ 818 BMS_brickNumVoltageMax 0;
BA_ "Confidence" SG_ 818 BMS_brickNumVoltageMin 0;
BA_ "Confidence" SG_ 722 BMS_minBusVoltage 0;
BA_ "Confidence" SG_ 722 BMS_maxBusVoltage 0;
BA_ "Confidence" SG_ 722 BMS_maxChargeCurrent 0;
BA_ "Confidence" SG_ 722 BMS_maxDischargeCurrent 0;
BA_ "Confidence" SG_ 850 BMS_energyStatusMultiplexer 1;
BA_ "Confidence" SG_ 850 BMS_nominalFullPackEnergy 0;
BA_ "GenSigSNA" SG_ 850 BMS_nominalFullPackEnergy "65535";
BA_ "Confidence" SG_ 850 BMS_nominalEnergyRemaining 0;
BA_ "GenSigSNA" SG_ 850 BMS_nominalEnergyRemaining "65535";
BA_ "Confidence" SG_ 850 BMS_idealEnergyRemaining 0;
BA_ "GenSigSNA" SG_ 850 BMS_idealEnergyRemaining "65535";
BA_ "Confidence" SG_ 850 BMS_fullChargeComplete 0;
BA_ "Confidence" SG_ 850 BMS_energyBuffer 0;
BA_ "GenSigSNA" SG_ 850 BMS_energyBuffer "65535";
BA_ "Confidence" SG_ 850 BMS_expectedEnergyRemaining 0;
BA_ "GenSigSNA" SG_ 850 BMS_expectedEnergyRemaining "65535";
BA_ "Confidence" SG_ 850 BMS_energyToChargeComplete 0;
BA_ "GenSigSNA" SG_ 850 BMS_energyToChargeComplete "65535";
BA_ "Confidence" SG_ 850 BMS_energyRemainingDisplay 0;
BA_ "GenSigSNA" SG_ 850 BMS_energyRemainingDisplay "65535";
BA_ "Confidence" SG_ 850 BMS_energyRemainingTDisplay 0;
BA_ "GenSigSNA" SG_ 850 BMS_energyRemainingTDisplay "65535";
BA_ "Confidence" SG_ 850 BMS_energyDisplayErrorBlendRate 0;
BA_ "Confidence" SG_ 850 BMS_userFacingSoe 0;
BA_ "GenSigSNA" SG_ 850 BMS_userFacingSoe "2047";
BA_ "Confidence" SG_ 768 BMS_infoIndex 1;
BA_ "Confidence" SG_ 768 BMS_buildType 0;
BA_ "Confidence" SG_ 768 BMS_buildConfigId 0;
BA_ "Confidence" SG_ 768 BMS_hardwareId 0;
BA_ "Confidence" SG_ 768 BMS_componentId 0;
BA_ "Confidence" SG_ 768 BMS_pcbaId 0;
BA_ "Confidence" SG_ 768 BMS_assemblyId 0;
BA_ "Confidence" SG_ 768 BMS_usageId 0;
BA_ "Confidence" SG_ 768 BMS_subUsageId 0;
BA_ "Confidence" SG_ 768 BMS_platformType 0;
BA_ "Confidence" SG_ 768 BMS_appCrc 0;
BA_ "Confidence" SG_ 768 BMS_appGitHash 0;
BA_ "Confidence" SG_ 768 BMS_bootGitHash 0;
BA_ "Confidence" SG_ 768 BMS_bootUdsProtoVersion 0;
BA_ "Confidence" SG_ 768 BMS_bootCrc 0;
BA_ "Confidence" SG_ 978 BMS_kwhDischargeTotal 0;
BA_ "Confidence" SG_ 978 BMS_kwhChargeTotal 0;
BA_ "Confidence" SG_ 1010 BMS_kwhCounter_Id 1;
BA_ "Confidence" SG_ 1010 BMS_acChargerKwhTotal 0;
BA_ "Confidence" SG_ 1010 BMS_dcChargerKwhTotal 0;
BA_ "Confidence" SG_ 1010 BMS_kwhRegenChargeTotal 0;
BA_ "Confidence" SG_ 1010 BMS_kwhDriveDischargeTotal 0;
BA_ "Confidence" SG_ 1010 BMS_kwhDischargeTotalModule1 0;
BA_ "Confidence" SG_ 1010 BMS_kwhChargeTotalModule1 0;
BA_ "Confidence" SG_ 1010 BMS_kwhAcChargeTotalModule1 0;
BA_ "Confidence" SG_ 1010 BMS_kwhDcChargeTotalModule1 0;
BA_ "Confidence" SG_ 1010 BMS_kwhDischargeTotalModule2 0;
BA_ "Confidence" SG_ 1010 BMS_kwhChargeTotalModule2 0;
BA_ "Confidence" SG_ 1010 BMS_kwhAcChargeTotalModule2 0;
BA_ "Confidence" SG_ 1010 BMS_kwhDcChargeTotalModule2 0;
BA_ "Confidence" SG_ 1010 BMS_kwhDischargeTotalModule3 0;
BA_ "Confidence" SG_ 1010 BMS_kwhChargeTotalModule3 0;
BA_ "Confidence" SG_ 1010 BMS_kwhAcChargeTotalModule3 0;
BA_ "Confidence" SG_ 1010 BMS_kwhDcChargeTotalModule3 0;
BA_ "Confidence" SG_ 1010 BMS_kwhDischargeTotalModule4 0;
BA_ "Confidence" SG_ 1010 BMS_kwhChargeTotalModule4 0;
BA_ "Confidence" SG_ 1010 BMS_kwhAcChargeTotalModule4 0;
BA_ "Confidence" SG_ 1010 BMS_kwhDcChargeTotalModule4 0;
BA_ "Confidence" SG_ 1170 BMS_sohEnergyPercent 0;
BA_ "GenSigSNA" SG_ 1170 BMS_sohEnergyPercent "1023";
BA_ "Confidence" SG_ 1170 BMS_userFacingSohTestState 0;
BA_ "Confidence" SG_ 1170 BMS_userFacingSohTestEndMode 0;
BA_ "Confidence" SG_ 1170 BMS_timeSinceSohUpdate 0;
BA_ "GenSigSNA" SG_ 1170 BMS_timeSinceSohUpdate "4095";
BA_ "Confidence" SG_ 1170 BMS_sohTestCycleFlag 0;
BA_ "Confidence" SG_ 1170 BMS_sohTestIsBlocked 0;
BA_ "Confidence" SG_ 1170 BMS_calibratedSohAvailable 0;
BA_ "Confidence" SG_ 1170 BMS_requiredEvsePowerForSoh 0;
BA_ "GenSigSNA" SG_ 1170 BMS_requiredEvsePowerForSoh "255";
BA_ "Confidence" SG_ 1170 BMS_distanceSinceSohUpdate 0;
BA_ "GenSigSNA" SG_ 1170 BMS_distanceSinceSohUpdate "65535";
BA_ "Confidence" SG_ 1116 CC_alertID 1;
BA_ "Confidence" SG_ 1116 CC_alertType 1;
BA_ "Confidence" SG_ 1116 CC_a001_groundResistance 1;
BA_ "GenSigSNA" SG_ 1116 CC_a001_groundResistance "4095";
BA_ "Confidence" SG_ 1116 CC_a003_gfciRmsCurrent 1;
BA_ "Confidence" SG_ 1116 CC_a003_gfciRmsCurrentAvg 1;
BA_ "Confidence" SG_ 1116 CC_a003_dcGfciCurrent 1;
BA_ "Confidence" SG_ 1116 CC_a003_gfciFaultReason 1;
BA_ "GenSigSNA" SG_ 1116 CC_a003_gfciFaultReason "0";
BA_ "Confidence" SG_ 1116 CC_a004_gfciErrorReason 1;
BA_ "GenSigSNA" SG_ 1116 CC_a004_gfciErrorReason "0";
BA_ "Confidence" SG_ 1116 CC_a004_gfciSelfTestDuty 1;
BA_ "Confidence" SG_ 1116 CC_a004_gfciSelfTestCurrent 1;
BA_ "Confidence" SG_ 1116 CC_a006_line1Current 1;
BA_ "Confidence" SG_ 1116 CC_a006_line2Current 1;
BA_ "Confidence" SG_ 1116 CC_a006_line3Current 1;
BA_ "Confidence" SG_ 1116 CC_a007_inputVoltage 1;
BA_ "Confidence" SG_ 1116 CC_a007_inputLineVoltage 1;
BA_ "Confidence" SG_ 1116 CC_a007_inputNeutralVoltage 1;
BA_ "Confidence" SG_ 1116 CC_a008_inputVoltage 1;
BA_ "Confidence" SG_ 1116 CC_a008_inputLineVoltage 1;
BA_ "Confidence" SG_ 1116 CC_a008_inputNeutralVoltage 1;
BA_ "Confidence" SG_ 1116 CC_a010_line1Voltage 1;
BA_ "Confidence" SG_ 1116 CC_a010_line2Voltage 1;
BA_ "Confidence" SG_ 1116 CC_a010_line3Voltage 1;
BA_ "Confidence" SG_ 1116 CC_a011_pcbaTemp 1;
BA_ "Confidence" SG_ 1116 CC_a012_inputThermopile 1;
BA_ "Confidence" SG_ 1116 CC_a012_inputThermopileDvdt 1;
BA_ "Confidence" SG_ 1116 CC_a013_handleTemp 1;
BA_ "Confidence" SG_ 1116 CC_a014_failureCause 1;
BA_ "Confidence" SG_ 1116 CC_a015_pilotHighVolage 1;
BA_ "Confidence" SG_ 1116 CC_a027_handleTemperature 1;
BA_ "Confidence" SG_ 1116 CC_a027_handleTempFaultReason 1;
BA_ "Confidence" SG_ 1116 CC_a033_nominalVoltage 1;
BA_ "Confidence" SG_ 1116 CC_a033_measuredVoltage 1;
BA_ "Confidence" SG_ 1116 CC_a036_line1Voltage 1;
BA_ "Confidence" SG_ 1116 CC_a036_line2Voltage 1;
BA_ "Confidence" SG_ 1116 CC_a036_line3Voltage 1;
BA_ "Confidence" SG_ 1116 CC_a039_intModuleTemperature 1;
BA_ "Confidence" SG_ 1116 CC_a040_handleTemperature 1;
BA_ "Confidence" SG_ 1116 CC_a041_inputThermopile 1;
BA_ "Confidence" SG_ 1116 CC_a041_inputThermopileDvdt 1;
BA_ "Confidence" SG_ 1116 CC_a042_pcbaTemperature 1;
BA_ "Confidence" SG_ 1116 CC_a044_relayCoilVoltage 1;
BA_ "Confidence" SG_ 1116 CC_a044_pcbaTemperature 1;
BA_ "SystemSignalLongSymbol" SG_ 1132 CC_a037_internalModuleWatchdogEx "CC_a037_internalModuleWatchdogExpired";
BA_ "SystemSignalLongSymbol" SG_ 1132 CC_a044_relayCoilVoltageRational "CC_a044_relayCoilVoltageRationality";
BA_ "Confidence" SG_ 796 CC_currentLimit 0;
BA_ "GenSigSNA" SG_ 796 CC_currentLimit "255";
BA_ "Confidence" SG_ 796 CC_pilotState 0;
BA_ "GenSigSNA" SG_ 796 CC_pilotState "3";
BA_ "Confidence" SG_ 796 CC_numPhases 0;
BA_ "GenSigSNA" SG_ 796 CC_numPhases "0";
BA_ "Confidence" SG_ 796 CC_line1Voltage 0;
BA_ "GenSigSNA" SG_ 796 CC_line1Voltage "511";
BA_ "Confidence" SG_ 796 CC_gridGrounding 0;
BA_ "GenSigSNA" SG_ 796 CC_gridGrounding "2";
BA_ "Confidence" SG_ 796 CC_deltaTransformer 0;
BA_ "Confidence" SG_ 796 CC_numVehCharging 0;
BA_ "Confidence" SG_ 796 CC_line2Voltage 0;
BA_ "GenSigSNA" SG_ 796 CC_line2Voltage "511";
BA_ "Confidence" SG_ 796 CC_line3Voltage 0;
BA_ "GenSigSNA" SG_ 796 CC_line3Voltage "511";
BA_ "Confidence" SG_ 796 CC_groundResistance 0;
BA_ "GenSigSNA" SG_ 796 CC_groundResistance "4095";
BA_ "Confidence" SG_ 812 CC_logIndex 1;
BA_ "Confidence" SG_ 812 CC_activeConnectorID 0;
BA_ "Confidence" SG_ 812 CC_temperature1 0;
BA_ "Confidence" SG_ 812 CC_temperature2 0;
BA_ "Confidence" SG_ 812 CC_temperature3 0;
BA_ "Confidence" SG_ 812 CC_contactor1Closed 0;
BA_ "Confidence" SG_ 812 CC_contactor2Closed 0;
BA_ "Confidence" SG_ 812 CC_temperature4 0;
BA_ "Confidence" SG_ 812 CC_conn1Current 0;
BA_ "GenSigSNA" SG_ 812 CC_conn1Current "255";
BA_ "Confidence" SG_ 812 CC_conn2Current 0;
BA_ "GenSigSNA" SG_ 812 CC_conn2Current "255";
BA_ "Confidence" SG_ 812 CC_conn3Current 0;
BA_ "GenSigSNA" SG_ 812 CC_conn3Current "255";
BA_ "Confidence" SG_ 812 CC_conn4Current 0;
BA_ "GenSigSNA" SG_ 812 CC_conn4Current "255";
BA_ "Confidence" SG_ 812 CC_lifetimei2t 0;
BA_ "Confidence" SG_ 812 CC_lifetimeCtrCycles 0;
BA_ "Confidence" SG_ 812 CC_lifetimeCtrCyclesLoaded 0;
BA_ "Confidence" SG_ 812 CC_lifetimeAlertCount 0;
BA_ "Confidence" SG_ 812 CC_lifetimeThermalFoldbacks 0;
BA_ "Confidence" SG_ 812 CC_lifetimeAvgStartupTemp 0;
BA_ "Confidence" SG_ 870 CMPD_infoIndex 1;
BA_ "Confidence" SG_ 870 CMPD_infoBuildType 0;
BA_ "Confidence" SG_ 870 CMPD_infoBuildConfigId 0;
BA_ "Confidence" SG_ 870 CMPD_infoHardwareId 0;
BA_ "Confidence" SG_ 870 CMPD_infoComponentId 0;
BA_ "Confidence" SG_ 870 CMPD_infoPcbaId 0;
BA_ "Confidence" SG_ 870 CMPD_infoAssemblyId 0;
BA_ "GenSigSNA" SG_ 870 CMPD_infoAssemblyId "255";
BA_ "Confidence" SG_ 870 CMPD_infoUsageId 0;
BA_ "Confidence" SG_ 870 CMPD_infoSubUsageId 0;
BA_ "Confidence" SG_ 679 CMPD_speedRPM 0;
BA_ "Confidence" SG_ 679 CMPD_speedDuty 0;
BA_ "Confidence" SG_ 679 CMPD_inputHVPower 0;
BA_ "Confidence" SG_ 679 CMPD_inputHVCurrent 0;
BA_ "Confidence" SG_ 679 CMPD_inputHVVoltage 0;
BA_ "Confidence" SG_ 679 CMPD_2ShuntModeActive 0;
BA_ "Confidence" SG_ 679 CMPD_powerLimitActive 0;
BA_ "Confidence" SG_ 679 CMPD_state 0;
BA_ "GenSigSNA" SG_ 679 CMPD_state "15";
BA_ "Confidence" SG_ 679 CMPD_wasteHeatState 0;
BA_ "Confidence" SG_ 679 CMPD_powerLimitTooLowToStart 0;
BA_ "Confidence" SG_ 679 CMPD_ready 0;
BA_ "Confidence" SG_ 867 CMP_infoIndex 1;
BA_ "Confidence" SG_ 867 CMP_infoBuildType 0;
BA_ "Confidence" SG_ 867 CMP_infoBuildConfigId 0;
BA_ "Confidence" SG_ 867 CMP_infoHardwareId 0;
BA_ "Confidence" SG_ 867 CMP_infoComponentId 0;
BA_ "Confidence" SG_ 867 CMP_infoPcbaId 0;
BA_ "Confidence" SG_ 867 CMP_infoAssemblyId 0;
BA_ "GenSigSNA" SG_ 867 CMP_infoAssemblyId "255";
BA_ "Confidence" SG_ 867 CMP_infoUsageId 0;
BA_ "Confidence" SG_ 867 CMP_infoSubUsageId 0;
BA_ "Confidence" SG_ 867 CMP_infoPlatformType 0;
BA_ "Confidence" SG_ 867 CMP_infoAppCrc 0;
BA_ "Confidence" SG_ 867 CMP_infoBootUdsProtoVersion 0;
BA_ "Confidence" SG_ 867 CMP_infoBootCrc 0;
BA_ "Confidence" SG_ 1342 CP_infoIndex 1;
BA_ "Confidence" SG_ 1342 CP_buildType 0;
BA_ "Confidence" SG_ 1342 CP_buildConfigId 0;
BA_ "Confidence" SG_ 1342 CP_hardwareId 0;
BA_ "Confidence" SG_ 1342 CP_componentId 0;
BA_ "Confidence" SG_ 1342 CP_pcbaId 0;
BA_ "Confidence" SG_ 1342 CP_assemblyId 0;
BA_ "Confidence" SG_ 1342 CP_usageId 0;
BA_ "Confidence" SG_ 1342 CP_subUsageId 0;
BA_ "Confidence" SG_ 1342 CP_platformType 0;
BA_ "Confidence" SG_ 1342 CP_appCrc 0;
BA_ "Confidence" SG_ 1342 CP_appGitHash 0;
BA_ "Confidence" SG_ 1342 CP_bootGitHash 0;
BA_ "Confidence" SG_ 1342 CP_bootUdsProtoVersion 0;
BA_ "Confidence" SG_ 1342 CP_bootCrc 0;
BA_ "Confidence" SG_ 1001 DAS_headlightRequest 0;
BA_ "Confidence" SG_ 1001 DAS_hazardLightRequest 0;
BA_ "GenSigSNA" SG_ 1001 DAS_hazardLightRequest "3";
BA_ "Confidence" SG_ 1001 DAS_wiperSpeed 0;
BA_ "Confidence" SG_ 1001 DAS_turnIndicatorRequest 0;
BA_ "Confidence" SG_ 1001 DAS_highLowBeamDecision 0;
BA_ "GenSigSNA" SG_ 1001 DAS_highLowBeamDecision "3";
BA_ "Confidence" SG_ 1001 DAS_heaterRequest 0;
BA_ "GenSigSNA" SG_ 1001 DAS_heaterRequest "0";
BA_ "Confidence" SG_ 1001 DAS_highLowBeamOffReason 0;
BA_ "GenSigSNA" SG_ 1001 DAS_highLowBeamOffReason "5";
BA_ "Confidence" SG_ 1001 DAS_forwardCamHeaterDutyCycle 0;
BA_ "Confidence" SG_ 1001 DAS_dynamicBrakeLightRequest 0;
BA_ "Confidence" SG_ 1001 DAS_radarHeaterRequest 0;
BA_ "Confidence" SG_ 1001 DAS_ahlbOverride 0;
BA_ "Confidence" SG_ 1001 DAS_mirrorFoldRequest 0;
BA_ "GenSigSNA" SG_ 1001 DAS_mirrorFoldRequest "3";
BA_ "Confidence" SG_ 1001 DAS_wiperWashRequest 0;
BA_ "Confidence" SG_ 1001 DAS_ulcConfirmationRequestActive 0;
BA_ "Confidence" SG_ 1001 DAS_overrideWiperSetting 0;
BA_ "Confidence" SG_ 1001 DAS_autoWiperState 0;
BA_ "GenSigSNA" SG_ 1001 DAS_autoWiperState "5";
BA_ "Confidence" SG_ 1001 DAS_turnIndicatorRequestReason 0;
BA_ "Confidence" SG_ 1001 DAS_forwardRadarPowerRequest 0;
BA_ "Confidence" SG_ 1001 DAS_driverDomeLightRequest 0;
BA_ "Confidence" SG_ 1001 DAS_drivePowerStateRequest 0;
BA_ "Confidence" SG_ 1001 DAS_enableIcrDataCollection 0;
BA_ "Confidence" SG_ 1001 DAS_rPillarCamHeaterDutyCycle 0;
BA_ "Confidence" SG_ 1001 DAS_adaptiveHighBeamIsFaulted 0;
BA_ "Confidence" SG_ 1001 DAS_restrictDoorReleaseLeft 0;
BA_ "Confidence" SG_ 1001 DAS_restrictDoorReleaseRight 0;
BA_ "Confidence" SG_ 1001 DAS_bodyControlsCounter 0;
BA_ "Confidence" SG_ 1001 DAS_bodyControlsChecksum 0;
BA_ "Confidence" SG_ 741 DIF_elecPower 0;
BA_ "GenSigSNA" SG_ 741 DIF_elecPower "1024";
BA_ "Confidence" SG_ 741 DIF_heatPowerOptimal 0;
BA_ "Confidence" SG_ 741 DIF_heatPowerMax 0;
BA_ "Confidence" SG_ 741 DIF_heatPowerActual 0;
BA_ "Confidence" SG_ 741 DIF_excessHeatCommand 0;
BA_ "Confidence" SG_ 741 DIF_drivePowerMax 0;
BA_ "GenSigSNA" SG_ 741 DIF_drivePowerMax "511";
BA_ "Confidence" SG_ 1367 DIF_passiveInletTempReq 0;
BA_ "Confidence" SG_ 1367 DIF_activeInletTempReq 0;
BA_ "Confidence" SG_ 1367 DIF_coolantFlowReq 0;
BA_ "Confidence" SG_ 1367 DIF_oilFlowReq 0;
BA_ "GenSigSNA" SG_ 1367 DIF_oilFlowReq "255";
BA_ "Confidence" SG_ 1367 DIF_criticalFlowReq 0;
BA_ "Confidence" SG_ 1367 DIF_burnInStatus 0;
BA_ "Confidence" SG_ 2005 DIR_debugSelector 1;
BA_ "Confidence" SG_ 2005 DIR_phaseOutBusbarTemp 0;
BA_ "GenSigSNA" SG_ 2005 DIR_phaseOutBusbarTemp "0";
BA_ "Confidence" SG_ 2005 DIR_phaseOutBusbarWeldTemp 0;
BA_ "GenSigSNA" SG_ 2005 DIR_phaseOutBusbarWeldTemp "0";
BA_ "Confidence" SG_ 2005 DIR_phaseOutLugTemp 0;
BA_ "GenSigSNA" SG_ 2005 DIR_phaseOutLugTemp "0";
BA_ "Confidence" SG_ 2005 DIR_dcLinkCapTemp 0;
BA_ "GenSigSNA" SG_ 2005 DIR_dcLinkCapTemp "0";
BA_ "Confidence" SG_ 2005 DIR_hvDcCableTemp 0;
BA_ "GenSigSNA" SG_ 2005 DIR_hvDcCableTemp "0";
BA_ "Confidence" SG_ 2005 DIR_negDcBusbarTemp 0;
BA_ "GenSigSNA" SG_ 2005 DIR_negDcBusbarTemp "0";
BA_ "Confidence" SG_ 2005 DIR_posDcBusbarTemp 0;
BA_ "GenSigSNA" SG_ 2005 DIR_posDcBusbarTemp "0";
BA_ "Confidence" SG_ 2005 DIR_statorEndWindingTemp 0;
BA_ "GenSigSNA" SG_ 2005 DIR_statorEndWindingTemp "0";
BA_ "Confidence" SG_ 2005 DIR_rotorMaxMagnetTemp 0;
BA_ "GenSigSNA" SG_ 2005 DIR_rotorMaxMagnetTemp "0";
BA_ "Confidence" SG_ 2005 DIR_lightSenseV 0;
BA_ "Confidence" SG_ 2005 DIR_pyroSenseV 0;
BA_ "Confidence" SG_ 2005 DIR_statorSlotWindingTemp 0;
BA_ "GenSigSNA" SG_ 2005 DIR_statorSlotWindingTemp "0";
BA_ "Confidence" SG_ 2005 DIR_intervalMaxHvBusV 0;
BA_ "Confidence" SG_ 917 DIR_oilPumpState 0;
BA_ "GenSigSNA" SG_ 917 DIR_oilPumpState "7";
BA_ "Confidence" SG_ 917 DIR_oilPumpFluidTQF 0;
BA_ "Confidence" SG_ 917 DIR_oilPumpLeadAngle 0;
BA_ "Confidence" SG_ 917 DIR_oilPumpFlowTarget 0;
BA_ "GenSigSNA" SG_ 917 DIR_oilPumpFlowTarget "255";
BA_ "Confidence" SG_ 917 DIR_oilPumpFlowActual 0;
BA_ "GenSigSNA" SG_ 917 DIR_oilPumpFlowActual "255";
BA_ "Confidence" SG_ 917 DIR_oilPumpFluidT 0;
BA_ "GenSigSNA" SG_ 917 DIR_oilPumpFluidT "255";
BA_ "Confidence" SG_ 917 DIR_oilPumpPhaseCurrent 0;
BA_ "GenSigSNA" SG_ 917 DIR_oilPumpPhaseCurrent "255";
BA_ "Confidence" SG_ 917 DIR_oilPumpPressureEstimate 0;
BA_ "GenSigSNA" SG_ 917 DIR_oilPumpPressureEstimate "255";
BA_ "Confidence" SG_ 917 DIR_oilPumpPressureExpected 0;
BA_ "GenSigSNA" SG_ 917 DIR_oilPumpPressureExpected "255";
BA_ "Confidence" SG_ 917 DIR_oilPumpPressureResidual 0;
BA_ "GenSigSNA" SG_ 917 DIR_oilPumpPressureResidual "255";
BA_ "Confidence" SG_ 614 DIR_elecPower 0;
BA_ "GenSigSNA" SG_ 614 DIR_elecPower "1024";
BA_ "Confidence" SG_ 614 DIR_heatPowerOptimal 0;
BA_ "Confidence" SG_ 614 DIR_heatPowerMax 0;
BA_ "Confidence" SG_ 614 DIR_heatPowerActual 0;
BA_ "Confidence" SG_ 614 DIR_excessHeatCommand 0;
BA_ "Confidence" SG_ 614 DIR_drivePowerMax 0;
BA_ "GenSigSNA" SG_ 614 DIR_drivePowerMax "511";
BA_ "Confidence" SG_ 1495 DIR_passiveInletTempReq 0;
BA_ "Confidence" SG_ 1495 DIR_activeInletTempReq 0;
BA_ "Confidence" SG_ 1495 DIR_coolantFlowReq 0;
BA_ "Confidence" SG_ 1495 DIR_oilFlowReq 0;
BA_ "GenSigSNA" SG_ 1495 DIR_oilFlowReq "255";
BA_ "Confidence" SG_ 1495 DIR_criticalFlowReq 0;
BA_ "Confidence" SG_ 1495 DIR_burnInStatus 0;
BA_ "Confidence" SG_ 2007 DI_debugSelector 1;
BA_ "Confidence" SG_ 2007 DI_regenBackfillCmd 0;
BA_ "Confidence" SG_ 2007 DI_regenBackfillUnavailableReaso 0;
BA_ "SystemSignalLongSymbol" SG_ 2007 DI_regenBackfillUnavailableReaso "DI_regenBackfillUnavailableReason";
BA_ "Confidence" SG_ 2007 DI_regenBackfillAbsSatState 0;
BA_ "Confidence" SG_ 2007 DI_sysHeatPowerOptimal 0;
BA_ "Confidence" SG_ 2007 DI_sysPostPedalMinTorque 0;
BA_ "Confidence" SG_ 2007 DI_sysPostPedalMaxTorque 0;
BA_ "Confidence" SG_ 2007 DI_systemTorqueCommand 0;
BA_ "Confidence" SG_ 616 DI_sysHeatPowerMax 0;
BA_ "Confidence" SG_ 616 DI_sysHeatPowerActual 0;
BA_ "Confidence" SG_ 616 DI_sysDrivePowerMax 0;
BA_ "GenSigSNA" SG_ 616 DI_sysDrivePowerMax "511";
BA_ "Confidence" SG_ 616 DI_primaryUnitSiliconType 0;
BA_ "Confidence" SG_ 616 DI_sysRegenPowerMax 0;
BA_ "GenSigSNA" SG_ 616 DI_sysRegenPowerMax "255";
BA_ "Confidence" SG_ 1992 EPBL_infoIndex 1;
BA_ "Confidence" SG_ 1992 EPBL_infoBuildType 0;
BA_ "Confidence" SG_ 1992 EPBL_infoBuildConfigId 0;
BA_ "Confidence" SG_ 1992 EPBL_infoHardwareId 0;
BA_ "Confidence" SG_ 1992 EPBL_infoComponentId 0;
BA_ "Confidence" SG_ 1992 EPBL_infoPcbaId 0;
BA_ "Confidence" SG_ 1992 EPBL_infoAssemblyId 0;
BA_ "GenSigSNA" SG_ 1992 EPBL_infoAssemblyId "255";
BA_ "Confidence" SG_ 1992 EPBL_infoUsageId 0;
BA_ "Confidence" SG_ 1992 EPBL_infoSubUsageId 0;
BA_ "Confidence" SG_ 1992 EPBL_infoAppCrc 0;
BA_ "Confidence" SG_ 1992 EPBL_infoAppGitHash 0;
BA_ "Confidence" SG_ 1992 EPBL_infoBootGitHash 0;
BA_ "Confidence" SG_ 1992 EPBL_infoPlatformType 0;
BA_ "Confidence" SG_ 1992 EPBL_infoBootUdsProtoVersion 0;
BA_ "Confidence" SG_ 1992 EPBL_infoBootCrc 0;
BA_ "Confidence" SG_ 648 EPBL_unitStatus 0;
BA_ "Confidence" SG_ 648 EPBL_unitFaultStatus 0;
BA_ "Confidence" SG_ 648 EPBL_summonState 0;
BA_ "Confidence" SG_ 648 EPBL_disconnected 0;
BA_ "Confidence" SG_ 648 EPBL_pistonTouchingRotor 0;
BA_ "Confidence" SG_ 648 EPBL_csmFaultReason 0;
BA_ "Confidence" SG_ 648 EPBL_esmOperationTrigger 0;
BA_ "Confidence" SG_ 648 EPBL_summonFaultReason 0;
BA_ "Confidence" SG_ 648 EPBL_localServiceModeActive 0;
BA_ "Confidence" SG_ 648 EPBL_localCdpState 0;
BA_ "Confidence" SG_ 648 EPBL_chimeRequestLocal 0;
BA_ "Confidence" SG_ 648 EPBL_telltaleLocal 0;
BA_ "GenSigSNA" SG_ 648 EPBL_telltaleLocal "7";
BA_ "Confidence" SG_ 648 EPBL_driverIsLeavingLocal 0;
BA_ "Confidence" SG_ 648 EPBL_driverIsLeavingAnySpeedLoca 0;
BA_ "SystemSignalLongSymbol" SG_ 648 EPBL_driverIsLeavingAnySpeedLoca "EPBL_driverIsLeavingAnySpeedLocal";
BA_ "Confidence" SG_ 648 EPBL_internalCDPRequest 0;
BA_ "Confidence" SG_ 648 EPBL_esmSpeedClass 0;
BA_ "Confidence" SG_ 648 EPBL_learnedEpbConfig 0;
BA_ "Confidence" SG_ 648 EPBL_internalStatusCounter 0;
BA_ "Confidence" SG_ 648 EPBL_internalStatusChecksum 0;
BA_ "Confidence" SG_ 743 EPBL_frontSeatCushionFanCur 0;
BA_ "Confidence" SG_ 743 EPBL_frontSeatBackrestFanCur 0;
BA_ "Confidence" SG_ 743 EPBL_frontSeatCushionFanDuty 0;
BA_ "Confidence" SG_ 743 EPBL_frontSeatCushionFanEn 0;
BA_ "Confidence" SG_ 743 EPBL_frontSeatBackrestFanEn 0;
BA_ "Confidence" SG_ 743 EPBL_frontSeatBackrestFanDuty 0;
BA_ "Confidence" SG_ 2024 EPBR_infoIndex 1;
BA_ "Confidence" SG_ 2024 EPBR_infoBuildType 0;
BA_ "Confidence" SG_ 2024 EPBR_infoBuildConfigId 0;
BA_ "Confidence" SG_ 2024 EPBR_infoHardwareId 0;
BA_ "Confidence" SG_ 2024 EPBR_infoComponentId 0;
BA_ "Confidence" SG_ 2024 EPBR_infoPcbaId 0;
BA_ "Confidence" SG_ 2024 EPBR_infoAssemblyId 0;
BA_ "GenSigSNA" SG_ 2024 EPBR_infoAssemblyId "255";
BA_ "Confidence" SG_ 2024 EPBR_infoUsageId 0;
BA_ "Confidence" SG_ 2024 EPBR_infoSubUsageId 0;
BA_ "Confidence" SG_ 2024 EPBR_infoAppCrc 0;
BA_ "Confidence" SG_ 2024 EPBR_infoAppGitHash 0;
BA_ "Confidence" SG_ 2024 EPBR_infoBootGitHash 0;
BA_ "Confidence" SG_ 2024 EPBR_infoPlatformType 0;
BA_ "Confidence" SG_ 2024 EPBR_infoBootUdsProtoVersion 0;
BA_ "Confidence" SG_ 2024 EPBR_infoBootCrc 0;
BA_ "Confidence" SG_ 552 EPBR_unitStatus 0;
BA_ "Confidence" SG_ 552 EPBR_unitFaultStatus 0;
BA_ "Confidence" SG_ 552 EPBR_summonState 0;
BA_ "Confidence" SG_ 552 EPBR_disconnected 0;
BA_ "Confidence" SG_ 552 EPBR_pistonTouchingRotor 0;
BA_ "Confidence" SG_ 552 EPBR_csmFaultReason 0;
BA_ "Confidence" SG_ 552 EPBR_esmOperationTrigger 0;
BA_ "Confidence" SG_ 552 EPBR_summonFaultReason 0;
BA_ "Confidence" SG_ 552 EPBR_localServiceModeActive 0;
BA_ "Confidence" SG_ 552 EPBR_localCdpState 0;
BA_ "Confidence" SG_ 552 EPBR_chimeRequestLocal 0;
BA_ "Confidence" SG_ 552 EPBR_telltaleLocal 0;
BA_ "GenSigSNA" SG_ 552 EPBR_telltaleLocal "7";
BA_ "Confidence" SG_ 552 EPBR_driverIsLeavingLocal 0;
BA_ "Confidence" SG_ 552 EPBR_driverIsLeavingAnySpeedLoca 0;
BA_ "SystemSignalLongSymbol" SG_ 552 EPBR_driverIsLeavingAnySpeedLoca "EPBR_driverIsLeavingAnySpeedLocal";
BA_ "Confidence" SG_ 552 EPBR_internalCDPRequest 0;
BA_ "Confidence" SG_ 552 EPBR_esmSpeedClass 0;
BA_ "Confidence" SG_ 552 EPBR_learnedEpbConfig 0;
BA_ "Confidence" SG_ 552 EPBR_internalStatusCounter 0;
BA_ "Confidence" SG_ 552 EPBR_internalStatusChecksum 0;
BA_ "Confidence" SG_ 1662 EVSE_isoTpToVehData 0;
BA_ "Confidence" SG_ 1322 FC_alertID 1;
BA_ "Confidence" SG_ 1322 FC_alertType 1;
BA_ "Confidence" SG_ 1322 FC_a146_CA_flybackOnTime 1;
BA_ "Confidence" SG_ 1322 FC_a146_CA_flybackV 1;
BA_ "Confidence" SG_ 1322 FC_a146_CA_flybackTargetV 1;
BA_ "Confidence" SG_ 1117 FC_evseBillingDataSelect 1;
BA_ "Confidence" SG_ 1117 FC_evseBillingEnergy 0;
BA_ "Confidence" SG_ 1117 FC_evseMeterPower 0;
BA_ "Confidence" SG_ 1117 FC_evseMeterCurrent 0;
BA_ "Confidence" SG_ 1117 FC_evseMeterVoltage 0;
BA_ "Confidence" SG_ 1117 FC_evseMeterFwGitHash 0;
BA_ "Confidence" SG_ 1334 FC_evseBilling2DataSelect 1;
BA_ "Confidence" SG_ 1334 FC_evsePpuEnabled 0;
BA_ "Confidence" SG_ 1334 FC_evseBillingEnergyHighRes 0;
BA_ "GenSigSNA" SG_ 1334 FC_evseBillingEnergyHighRes "16777215";
BA_ "Confidence" SG_ 1303 FC_id 0;
BA_ "Confidence" SG_ 1303 FC_sessionId 0;
BA_ "Confidence" SG_ 1310 FC_infoIndex 1;
BA_ "Confidence" SG_ 1310 FC_infoBuildType 0;
BA_ "Confidence" SG_ 1310 FC_infoBuildConfigID 0;
BA_ "Confidence" SG_ 1310 FC_infoHardwareID 0;
BA_ "Confidence" SG_ 1310 FC_infoComponentID 0;
BA_ "Confidence" SG_ 1310 FC_infoPcbaID 0;
BA_ "Confidence" SG_ 1310 FC_infoAssemblyID 0;
BA_ "Confidence" SG_ 1310 FC_infoUsageID 0;
BA_ "Confidence" SG_ 1310 FC_infoSubUsageID 0;
BA_ "Confidence" SG_ 1310 FC_infoApplicationCRC 0;
BA_ "Confidence" SG_ 1310 FC_infoAppGitHashBytes 0;
BA_ "Confidence" SG_ 1310 FC_infoBootGitHashBytes 0;
BA_ "Confidence" SG_ 1310 FC_infoPlatformType 0;
BA_ "Confidence" SG_ 1310 FC_infoMajorVersion 0;
BA_ "Confidence" SG_ 1310 FC_infoBranchOrigin 0;
BA_ "Confidence" SG_ 1310 FC_infoMaturity 0;
BA_ "Confidence" SG_ 1310 FC_infoHardwareRevision 0;
BA_ "Confidence" SG_ 1310 FC_partNumChar01 0;
BA_ "Confidence" SG_ 1310 FC_partNumChar02 0;
BA_ "Confidence" SG_ 1310 FC_partNumChar03 0;
BA_ "Confidence" SG_ 1310 FC_partNumChar04 0;
BA_ "Confidence" SG_ 1310 FC_partNumChar05 0;
BA_ "Confidence" SG_ 1310 FC_partNumChar06 0;
BA_ "Confidence" SG_ 1310 FC_partNumChar07 0;
BA_ "Confidence" SG_ 1310 FC_partNumChar08 0;
BA_ "Confidence" SG_ 1310 FC_partNumChar09 0;
BA_ "Confidence" SG_ 1310 FC_partNumChar10 0;
BA_ "Confidence" SG_ 1310 FC_partNumChar11 0;
BA_ "Confidence" SG_ 1310 FC_partNumChar12 0;
BA_ "Confidence" SG_ 1310 FC_partNumChar13 0;
BA_ "Confidence" SG_ 1310 FC_partNumChar14 0;
BA_ "Confidence" SG_ 1310 FC_partNumChar15 0;
BA_ "Confidence" SG_ 1310 FC_partNumChar16 0;
BA_ "Confidence" SG_ 1310 FC_partNumChar17 0;
BA_ "Confidence" SG_ 1310 FC_partNumChar18 0;
BA_ "Confidence" SG_ 1310 FC_partNumChar19 0;
BA_ "Confidence" SG_ 1310 FC_partNumChar20 0;
BA_ "Confidence" SG_ 580 FC_powerLimit 0;
BA_ "GenSigSNA" SG_ 580 FC_powerLimit "8191";
BA_ "Confidence" SG_ 580 FC_currentLimit 0;
BA_ "GenSigSNA" SG_ 580 FC_currentLimit "8191";
BA_ "Confidence" SG_ 580 FC_maxVoltageLimit 0;
BA_ "GenSigSNA" SG_ 580 FC_maxVoltageLimit "8191";
BA_ "Confidence" SG_ 580 FC_minVoltageLimit 0;
BA_ "GenSigSNA" SG_ 580 FC_minVoltageLimit "8191";
BA_ "Confidence" SG_ 702 FC_powerLimit_value 0;
BA_ "GenSigSNA" SG_ 702 FC_powerLimit_value "32768";
BA_ "Confidence" SG_ 702 FC_currentLimit_value 0;
BA_ "GenSigSNA" SG_ 702 FC_currentLimit_value "32768";
BA_ "Confidence" SG_ 702 FC_minVoltageLimit_value 0;
BA_ "GenSigSNA" SG_ 702 FC_minVoltageLimit_value "32768";
BA_ "Confidence" SG_ 702 FC_powerLimit_exp 0;
BA_ "Confidence" SG_ 702 FC_currentLimit_exp 0;
BA_ "Confidence" SG_ 702 FC_minVoltageLimit_exp 0;
BA_ "Confidence" SG_ 1345 FC_maxPowerLimit 0;
BA_ "GenSigSNA" SG_ 1345 FC_maxPowerLimit "8191";
BA_ "Confidence" SG_ 1345 FC_maxCurrentLimit 0;
BA_ "GenSigSNA" SG_ 1345 FC_maxCurrentLimit "8191";
BA_ "Confidence" SG_ 1300 FC_serialDataSelect 1;
BA_ "Confidence" SG_ 1300 FC_serialChar01 0;
BA_ "Confidence" SG_ 1300 FC_serialChar02 0;
BA_ "Confidence" SG_ 1300 FC_serialChar03 0;
BA_ "Confidence" SG_ 1300 FC_serialChar04 0;
BA_ "Confidence" SG_ 1300 FC_serialChar05 0;
BA_ "Confidence" SG_ 1300 FC_serialChar06 0;
BA_ "Confidence" SG_ 1300 FC_serialChar07 0;
BA_ "Confidence" SG_ 1300 FC_serialChar08 0;
BA_ "Confidence" SG_ 1300 FC_serialChar09 0;
BA_ "Confidence" SG_ 1300 FC_serialChar10 0;
BA_ "Confidence" SG_ 1300 FC_serialChar11 0;
BA_ "Confidence" SG_ 1300 FC_serialChar12 0;
BA_ "Confidence" SG_ 1300 FC_serialChar13 0;
BA_ "Confidence" SG_ 1300 FC_serialChar14 0;
BA_ "Confidence" SG_ 1300 FC_serialChar15 0;
BA_ "Confidence" SG_ 1300 FC_serialChar16 0;
BA_ "Confidence" SG_ 1300 FC_serialChar17 0;
BA_ "Confidence" SG_ 532 FC_protocolVersion 0;
BA_ "Confidence" SG_ 532 FC_statusCode 0;
BA_ "GenSigSNA" SG_ 532 FC_statusCode "0";
BA_ "Confidence" SG_ 532 FC_deprecated1 0;
BA_ "Confidence" SG_ 532 FC_deprecated2 0;
BA_ "Confidence" SG_ 532 FC_deprecated3 0;
BA_ "Confidence" SG_ 532 FC_adapterLocked 0;
BA_ "Confidence" SG_ 532 FC_minCurrentLimit 0;
BA_ "Confidence" SG_ 532 FC_type 0;
BA_ "GenSigSNA" SG_ 532 FC_type "7";
BA_ "Confidence" SG_ 532 FC_dcCurrent 0;
BA_ "Confidence" SG_ 532 FC_postID 0;
BA_ "GenSigSNA" SG_ 532 FC_postID "3";
BA_ "Confidence" SG_ 532 FC_dcVoltage 0;
BA_ "Confidence" SG_ 532 FC_leakageTestNotSupported 0;
BA_ "Confidence" SG_ 532 FC_dischargeSupported 0;
BA_ "Confidence" SG_ 533 FC_externalIsolationResistance 0;
BA_ "GenSigSNA" SG_ 533 FC_externalIsolationResistance "255";
BA_ "Confidence" SG_ 535 FC_status3DataSelect 1;
BA_ "Confidence" SG_ 535 FC_status3DummySig 0;
BA_ "Confidence" SG_ 535 FC_class 0;
BA_ "GenSigSNA" SG_ 535 FC_class "0";
BA_ "Confidence" SG_ 535 FC_brand 0;
BA_ "GenSigSNA" SG_ 535 FC_brand "0";
BA_ "Confidence" SG_ 535 FC_coolingType 0;
BA_ "GenSigSNA" SG_ 535 FC_coolingType "0";
BA_ "Confidence" SG_ 535 FC_uiStopType 0;
BA_ "GenSigSNA" SG_ 535 FC_uiStopType "0";
BA_ "Confidence" SG_ 535 FC_emergencyShutdownSupported 0;
BA_ "Confidence" SG_ 535 FC_generation 0;
BA_ "GenSigSNA" SG_ 535 FC_generation "0";
BA_ "Confidence" SG_ 1650 VC_hcmlInfoIndex 1;
BA_ "Confidence" SG_ 1650 VC_infoHCMLBuildConfigId 0;
BA_ "Confidence" SG_ 1650 VC_leftHeadlampLMMVariant 0;
BA_ "GenSigSNA" SG_ 1650 VC_leftHeadlampLMMVariant "0";
BA_ "Confidence" SG_ 1650 VC_infoHCMLAssemblyId 0;
BA_ "Confidence" SG_ 1650 VC_infoHCMLPcbaId 0;
BA_ "Confidence" SG_ 1650 VC_infoHCMLUsageId 0;
BA_ "Confidence" SG_ 1980 VC_hcmrInfoIndex 1;
BA_ "Confidence" SG_ 1980 VC_infoHCMRBuildConfigId 0;
BA_ "Confidence" SG_ 1980 VC_rightHeadlampLMMVariant 0;
BA_ "GenSigSNA" SG_ 1980 VC_rightHeadlampLMMVariant "0";
BA_ "Confidence" SG_ 1980 VC_infoHCMRAssemblyId 0;
BA_ "Confidence" SG_ 1980 VC_infoHCMRPcbaId 0;
BA_ "Confidence" SG_ 1980 VC_infoHCMRUsageId 0;
BA_ "Confidence" SG_ 554 HVP_dcLinkVoltageRequest 0;
BA_ "Confidence" SG_ 554 HVP_pcsControlRequest 0;
BA_ "Confidence" SG_ 554 HVP_pcsChargeHwEnabled 0;
BA_ "Confidence" SG_ 554 HVP_pcsDcdcHwEnabled 0;
BA_ "Confidence" SG_ 554 HVP_dcLinkVoltageFiltered 0;
BA_ "GenSigSNA" SG_ 554 HVP_dcLinkVoltageFiltered "1498";
BA_ "Confidence" SG_ 784 HVP_infoIndex 1;
BA_ "Confidence" SG_ 784 HVP_buildType 0;
BA_ "Confidence" SG_ 784 HVP_buildConfigId 0;
BA_ "Confidence" SG_ 784 HVP_hardwareId 0;
BA_ "Confidence" SG_ 784 HVP_componentId 0;
BA_ "Confidence" SG_ 784 HVP_pcbaId 0;
BA_ "Confidence" SG_ 784 HVP_assemblyId 0;
BA_ "Confidence" SG_ 784 HVP_usageId 0;
BA_ "Confidence" SG_ 784 HVP_subUsageId 0;
BA_ "Confidence" SG_ 784 HVP_platformType 0;
BA_ "Confidence" SG_ 784 HVP_appCrc 0;
BA_ "Confidence" SG_ 784 HVP_appGitHash 0;
BA_ "Confidence" SG_ 784 HVP_bootGitHash 0;
BA_ "Confidence" SG_ 784 HVP_bootUdsProtoVersion 0;
BA_ "Confidence" SG_ 784 HVP_bootCrc 0;
BA_ "Confidence" SG_ 1914 HVP_log1HzIndex 1;
BA_ "Confidence" SG_ 1914 HVP_bmbAsicType 0;
BA_ "Confidence" SG_ 1914 HVP_shuntCurrentAuxLog 0;
BA_ "Confidence" SG_ 1914 HVP_pyroSquibResistance 0;
BA_ "GenSigSNA" SG_ 1914 HVP_pyroSquibResistance "65535";
BA_ "Confidence" SG_ 1914 HVP_shuntAsicChipXCoordinate 0;
BA_ "Confidence" SG_ 1914 HVP_shuntAsicChipYCoordinate 0;
BA_ "Confidence" SG_ 1914 HVP_hvilCalType 0;
BA_ "Confidence" SG_ 1914 HVP_gpioPcsDcdcPwmEnable 0;
BA_ "Confidence" SG_ 1914 HVP_gpioPcsChargePwmEnable 0;
BA_ "Confidence" SG_ 1914 HVP_gpioPcsEnable 0;
BA_ "Confidence" SG_ 1914 HVP_shuntAsicChipWaferNumber 0;
BA_ "Confidence" SG_ 1914 HVP_energyReserveMin 0;
BA_ "Confidence" SG_ 1914 HVP_energyReserveMax 0;
BA_ "Confidence" SG_ 1914 HVP_energyReserveAvg 0;
BA_ "Confidence" SG_ 941 ICR_infoIndex 1;
BA_ "Confidence" SG_ 941 ICR_infoBuildType 0;
BA_ "Confidence" SG_ 941 ICR_infoPcbaId 0;
BA_ "Confidence" SG_ 941 ICR_infoAssemblyId 0;
BA_ "Confidence" SG_ 941 ICR_infoUsageId 0;
BA_ "Confidence" SG_ 941 ICR_infoAppCrc 0;
BA_ "Confidence" SG_ 941 ICR_infoBoardPartNumber17 0;
BA_ "Confidence" SG_ 941 ICR_infoBoardPartNumber814 0;
BA_ "Confidence" SG_ 941 ICR_infoBoardPartNumber1520 0;
VAL_ 818 BMS_bmbMinMaxMultiplexer 2 "END" 1 "VOLT_MUX1" 0 "THERM_MUX0" ;
VAL_ 850 BMS_energyStatusMultiplexer 2 "Mux2" 1 "Mux1" 0 "Mux0" ;
VAL_ 850 BMS_nominalFullPackEnergy 65535 "SNA" ;
VAL_ 850 BMS_nominalEnergyRemaining 65535 "SNA" ;
VAL_ 850 BMS_idealEnergyRemaining 65535 "SNA" ;
VAL_ 850 BMS_energyBuffer 65535 "SNA" ;
VAL_ 850 BMS_expectedEnergyRemaining 65535 "SNA" ;
VAL_ 850 BMS_energyToChargeComplete 65535 "SNA" ;
VAL_ 850 BMS_energyRemainingDisplay 65535 "SNA" ;
VAL_ 850 BMS_energyRemainingTDisplay 65535 "SNA" ;
VAL_ 850 BMS_userFacingSoe 2047 "SNA" ;
VAL_ 768 BMS_infoIndex 255 "END" 31 "SUBCOMPONENT_GITHASH" 30 "PACKAGE_SN_8_14" 29 "PACKAGE_SN_1_7" 27 "PACKAGE_PN_15_20" 26 "PACKAGE_PN_8_14" 25 "PACKAGE_PN_1_7" 23 "SUBCOMPONENT2" 22 "VARIANTCRC" 20 "UDS_PROTOCOL_BOOTCRC" 19 "VERSION_DEPRECATED" 18 "BOOTLOADER_GITHASH" 17 "APP_GITHASH" 16 "SUBCOMPONENT" 15 "BOOTLOADER_CRC" 14 "BOOTLOADER_SVN" 13 "APP_CRC" 11 "PCBAID_ASSYID_USAGEID" 10 "BUILD_HWID_COMPONENTID" 9 "DEPRECATED_9" 8 "DEPRECATED_8" 7 "DEPRECATED_7" 6 "DEPRECATED_6" 5 "DEPRECATED_5" 4 "DEPRECATED_4" 3 "DEPRECATED_3" 2 "DEPRECATED_2" 1 "DEPRECATED_1" 0 "DEPRECATED_0" ;
VAL_ 768 BMS_buildType 4 "INFO_MFG_BUILD" 3 "INFO_TRACEABLE_CI_BUILD" 2 "INFO_LOCAL_BUILD" 1 "INFO_PLATFORM_BUILD" 0 "INFO_UNKNOWN_BUILD" ;
VAL_ 1010 BMS_kwhCounter_Id 14 "END" 13 "MUX13" 12 "MUX12" 11 "MUX11" 10 "MUX10" 9 "MUX9" 8 "MUX8" 7 "MUX7" 6 "MUX6" 5 "MUX5" 4 "MUX4" 3 "MUX3" 2 "MUX2" 1 "MUX1" 0 "MUX0" ;
VAL_ 1170 BMS_sohEnergyPercent 1023 "SNA" ;
VAL_ 1170 BMS_userFacingSohTestState 5 "CHARGE_REST" 4 "CHARGE" 3 "DISCHARGE_REST" 2 "DISCHARGE" 1 "HEAT_PACK" 0 "NOT_RUNNING" ;
VAL_ 1170 BMS_userFacingSohTestEndMode 5 "TEST_COMPLETE_WITH_SOC_IMBALANCE" 4 "TEST_COMPLETE" 3 "FAILED" 2 "REQUEST_DROPPED" 1 "RUNNING" 0 "NONE" ;
VAL_ 1170 BMS_timeSinceSohUpdate 4095 "SNA" ;
VAL_ 1170 BMS_requiredEvsePowerForSoh 255 "SNA" ;
VAL_ 1170 BMS_distanceSinceSohUpdate 65535 "SNA" ;
VAL_ 1116 CC_alertID 61 "a061_unfinishedCommissioning" 60 "a060_persistenceFault" 57 "a057_chcVitalsRequestFailure" 52 "a052_vRefOutOfRangePWM" 51 "a051_chcCriticalFault" 50 "a050_eFuseFault" 49 "a049_rs485Fault" 48 "a048_ACMDAdapterFault" 47 "a047_MDMotorContFault" 46 "a046_GFCIConfigInvalid" 45 "a045_ACPowerLoss" 44 "a044_relayCoilVoltageRationality" 43 "a043_configurationRequired" 42 "a042_pcbaTempFoldback" 41 "a041_inputWiringFoldback" 40 "a040_handleTempFoldback" 39 "a039_internalModuleOverTemp" 38 "a038_internalModuleMia" 37 "a037_internalModuleWatchdogExpired" 36 "a036_contactorStuckOpen" 35 "a035_CCIDCalibration" 34 "a034_bootAlert" 33 "a033_vRefOutOfRange" 32 "a032_meteringFailure" 31 "a031_pllLockLost" 30 "a030_masterSlaveMismatch" 29 "a029_PilotFFault" 28 "a028_CB_rotarySelect" 27 "a027_vehicleHandleTemp" 26 "a026_wallPlugTemp" 25 "a025_evseTemp" 24 "a024_CB_masterISetTooLow" 23 "a023_CB_tooManySlaves" 22 "a022_CB_tooManyMasters" 21 "a021_CB_noMaster" 20 "a020_3vRailIncorrect" 19 "a019_proxDisconnected" 18 "a018_PilotDFault" 17 "a017_PilotCFault" 16 "a016_PilotBFault" 15 "a015_PilotAFault" 14 "a014_mcuSelfTestFault" 13 "a013_vehConnOT" 12 "a012_wallPlugOT" 11 "a011_ambientOT" 10 "a010_contactorWelded" 9 "a009_inputMiswired" 8 "a008_inputUnderVoltage" 7 "a007_inputOverVoltage" 6 "a006_inputOverCurrent" 5 "a005_groundedNeutral" 4 "a004_CCIDSelfTestFault" 3 "a003_CCIDTripped" 2 "a002_gndMonIntrptLoadSide" 1 "a001_gndMonIntrptLineSide" 0 "ALERT_DO_NOT_USE_ZERO" ;
VAL_ 1116 CC_alertType 1 "SET" 0 "CLEARED" ;
VAL_ 1116 CC_a001_groundResistance 4095 "SNA" 4094 "NO_GROUND" ;
VAL_ 1116 CC_a003_gfciFaultReason 4 "DC_PEAK" 3 "DC_LPF" 2 "AC_PEAK" 1 "AC_LPF" 0 "SNA" ;
VAL_ 1116 CC_a004_gfciErrorReason 5 "TEST_SIGNAL_ERROR" 4 "AC_OFFSET_ERROR" 3 "DC_OFFSET_ERROR" 2 "ASIC_REASON" 1 "IO_ERROR" 0 "SNA" ;
VAL_ 1116 CC_a014_failureCause 4 "DCGFCI_INIT_FAILED" 3 "METER_INIT_FAILED" 2 "CONFIG_NOT_RECEIVED" 1 "OTHER" ;
VAL_ 1116 CC_a027_handleTempFaultReason 5 "CHC_OPEN_CIRCUIT" 4 "CHC_SHORT_CIRCUIT" 3 "CHC_INVALID_VITAL" 2 "NTC_BUTTON_PRESSED" 1 "NTC_OPEN_CIRCUIT" 0 "TEMP_GOOD" ;
VAL_ 796 CC_currentLimit 255 "SNA" ;
VAL_ 796 CC_pilotState 3 "CC_PILOT_STATE_SNA" 2 "CC_PILOT_STATE_FAULTED" 1 "CC_PILOT_STATE_IDLE" 0 "CC_PILOT_STATE_READY" ;
VAL_ 796 CC_numPhases 0 "SNA" ;
VAL_ 796 CC_line1Voltage 511 "SNA" ;
VAL_ 796 CC_gridGrounding 2 "CC_GRID_GROUNDING_SNA" 1 "CC_GRID_GROUNDING_IT_SplitPhase" 0 "CC_GRID_GROUNDING_TN_TT" ;
VAL_ 796 CC_line2Voltage 511 "SNA" ;
VAL_ 796 CC_line3Voltage 511 "SNA" ;
VAL_ 796 CC_groundResistance 4095 "SNA" 4094 "NO_GROUND" ;
VAL_ 812 CC_logIndex 13 "Mux13" 12 "Mux12" 11 "Mux11" 10 "Mux10" 4 "Mux4" 3 "Mux3" 2 "Mux2" 1 "Mux1" 0 "Mux0" ;
VAL_ 812 CC_activeConnectorID 255 "SNA" ;
VAL_ 812 CC_temperature1 127 "SNA" ;
VAL_ 812 CC_temperature2 127 "SNA" ;
VAL_ 812 CC_temperature3 127 "SNA" ;
VAL_ 812 CC_contactor1Closed 3 "CC_CONTACTOR_SNA" 1 "CC_CONTACTOR_CLOSED" 0 "CC_CONTACTOR_OPEN" ;
VAL_ 812 CC_contactor2Closed 3 "CC_CONTACTOR_SNA" 1 "CC_CONTACTOR_CLOSED" 0 "CC_CONTACTOR_OPEN" ;
VAL_ 812 CC_temperature4 127 "SNA" ;
VAL_ 812 CC_conn1Current 255 "SNA" ;
VAL_ 812 CC_conn2Current 255 "SNA" ;
VAL_ 812 CC_conn3Current 255 "SNA" ;
VAL_ 812 CC_conn4Current 255 "SNA" ;
VAL_ 870 CMPD_infoIndex 255 "END" 31 "SUBCOMPONENT_GITHASH" 30 "PACKAGE_SN_8_14" 29 "PACKAGE_SN_1_7" 27 "PACKAGE_PN_15_20" 26 "PACKAGE_PN_8_14" 25 "PACKAGE_PN_1_7" 23 "SUBCOMPONENT2" 22 "VARIANTCRC" 20 "UDS_PROTOCOL_BOOTCRC" 19 "VERSION_DEPRECATED" 18 "BOOTLOADER_GITHASH" 17 "APP_GITHASH" 16 "SUBCOMPONENT" 15 "BOOTLOADER_CRC" 14 "BOOTLOADER_SVN" 13 "APP_CRC" 11 "PCBAID_ASSYID_USAGEID" 10 "BUILD_HWID_COMPONENTID" 9 "DEPRECATED_9" 8 "DEPRECATED_8" 7 "DEPRECATED_7" 6 "DEPRECATED_6" 5 "DEPRECATED_5" 4 "DEPRECATED_4" 3 "DEPRECATED_3" 2 "DEPRECATED_2" 1 "DEPRECATED_1" 0 "DEPRECATED_0" ;
VAL_ 870 CMPD_infoBuildType 4 "INFO_MFG_BUILD" 3 "INFO_TRACEABLE_CI_BUILD" 2 "INFO_LOCAL_BUILD" 1 "INFO_PLATFORM_BUILD" 0 "INFO_UNKNOWN_BUILD" ;
VAL_ 870 CMPD_infoAssemblyId 255 "ASSEMBLY_SNA" 1 "ASSEMBLY1" ;
VAL_ 679 CMPD_state 15 "CMPD_STATE_SNA" 4 "CMPD_STATE_IDLE" 3 "CMPD_STATE_FAULT" 2 "CMPD_STATE_STANDBY" 1 "CMPD_STATE_RUNNING" 0 "CMPD_STATE_INIT" ;
VAL_ 679 CMPD_wasteHeatState 3 "CMPD_WASTE_HEAT_STATE_UNUSED" 2 "CMPD_WASTE_HEAT_STATE_NOT_AVAILABLE" 1 "CMPD_WASTE_HEAT_STATE_ACTIVE" 0 "CMPD_WASTE_HEAT_STATE_OFF" ;
VAL_ 867 CMP_infoIndex 255 "END" 31 "SUBCOMPONENT_GITHASH" 30 "PACKAGE_SN_8_14" 29 "PACKAGE_SN_1_7" 27 "PACKAGE_PN_15_20" 26 "PACKAGE_PN_8_14" 25 "PACKAGE_PN_1_7" 23 "SUBCOMPONENT2" 22 "VARIANTCRC" 20 "UDS_PROTOCOL_BOOTCRC" 19 "VERSION_DEPRECATED" 18 "BOOTLOADER_GITHASH" 17 "APP_GITHASH" 16 "SUBCOMPONENT" 15 "BOOTLOADER_CRC" 14 "BOOTLOADER_SVN" 13 "APP_CRC" 11 "PCBAID_ASSYID_USAGEID" 10 "BUILD_HWID_COMPONENTID" 9 "DEPRECATED_9" 8 "DEPRECATED_8" 7 "DEPRECATED_7" 6 "DEPRECATED_6" 5 "DEPRECATED_5" 4 "DEPRECATED_4" 3 "DEPRECATED_3" 2 "DEPRECATED_2" 1 "DEPRECATED_1" 0 "DEPRECATED_0" ;
VAL_ 867 CMP_infoBuildType 4 "INFO_MFG_BUILD" 3 "INFO_TRACEABLE_CI_BUILD" 2 "INFO_LOCAL_BUILD" 1 "INFO_PLATFORM_BUILD" 0 "INFO_UNKNOWN_BUILD" ;
VAL_ 867 CMP_infoAssemblyId 255 "ASSEMBLY_SNA" 1 "ASSEMBLY1" ;
VAL_ 1342 CP_infoIndex 255 "END" 31 "SUBCOMPONENT_GITHASH" 30 "PACKAGE_SN_8_14" 29 "PACKAGE_SN_1_7" 27 "PACKAGE_PN_15_20" 26 "PACKAGE_PN_8_14" 25 "PACKAGE_PN_1_7" 23 "SUBCOMPONENT2" 22 "VARIANTCRC" 20 "UDS_PROTOCOL_BOOTCRC" 19 "VERSION_DEPRECATED" 18 "BOOTLOADER_GITHASH" 17 "APP_GITHASH" 16 "SUBCOMPONENT" 15 "BOOTLOADER_CRC" 14 "BOOTLOADER_SVN" 13 "APP_CRC" 11 "PCBAID_ASSYID_USAGEID" 10 "BUILD_HWID_COMPONENTID" 9 "DEPRECATED_9" 8 "DEPRECATED_8" 7 "DEPRECATED_7" 6 "DEPRECATED_6" 5 "DEPRECATED_5" 4 "DEPRECATED_4" 3 "DEPRECATED_3" 2 "DEPRECATED_2" 1 "DEPRECATED_1" 0 "DEPRECATED_0" ;
VAL_ 1342 CP_buildType 4 "INFO_MFG_BUILD" 3 "INFO_TRACEABLE_CI_BUILD" 2 "INFO_LOCAL_BUILD" 1 "INFO_PLATFORM_BUILD" 0 "INFO_UNKNOWN_BUILD" ;
VAL_ 1001 DAS_headlightRequest 3 "DAS_HEADLIGHT_REQUEST_INVALID" 2 "DAS_HEADLIGHT_REQUEST_TAIL_LIGHTS_ONLY" 1 "DAS_HEADLIGHT_REQUEST_ON" 0 "DAS_HEADLIGHT_REQUEST_OFF" ;
VAL_ 1001 DAS_hazardLightRequest 3 "DAS_REQUEST_HAZARDS_SNA" 2 "DAS_REQUEST_HAZARDS_ON_FAST" 1 "DAS_REQUEST_HAZARDS_ON" 0 "DAS_REQUEST_HAZARDS_OFF" ;
VAL_ 1001 DAS_wiperSpeed 15 "DAS_WIPER_SPEED_INVALID" 14 "DAS_WIPER_SPEED_14" 13 "DAS_WIPER_SPEED_13" 12 "DAS_WIPER_SPEED_12" 11 "DAS_WIPER_SPEED_11" 10 "DAS_WIPER_SPEED_10" 9 "DAS_WIPER_SPEED_9" 8 "DAS_WIPER_SPEED_8" 7 "DAS_WIPER_SPEED_7" 6 "DAS_WIPER_SPEED_6" 5 "DAS_WIPER_SPEED_5" 4 "DAS_WIPER_SPEED_4" 3 "DAS_WIPER_SPEED_3" 2 "DAS_WIPER_SPEED_2" 1 "DAS_WIPER_SPEED_1" 0 "DAS_WIPER_SPEED_OFF" ;
VAL_ 1001 DAS_turnIndicatorRequest 4 "DAS_TURN_INDICATOR_DEFER" 3 "DAS_TURN_INDICATOR_CANCEL" 2 "DAS_TURN_INDICATOR_RIGHT" 1 "DAS_TURN_INDICATOR_LEFT" 0 "DAS_TURN_INDICATOR_NONE" ;
VAL_ 1001 DAS_highLowBeamDecision 3 "DAS_HIGH_BEAM_SNA" 2 "DAS_HIGH_BEAM_ON" 1 "DAS_HIGH_BEAM_OFF" 0 "DAS_HIGH_BEAM_UNDECIDED" ;
VAL_ 1001 DAS_heaterRequest 2 "DAS_HEATER_ON" 1 "DAS_HEATER_OFF" 0 "DAS_HEATER_SNA" ;
VAL_ 1001 DAS_highLowBeamOffReason 5 "HIGH_BEAM_OFF_REASON_SNA" 4 "HIGH_BEAM_OFF_REASON_HEAD_LIGHT" 3 "HIGH_BEAM_OFF_REASON_AMBIENT_LIGHT" 2 "HIGH_BEAM_OFF_REASON_MOVING_RADAR_TARGET" 1 "HIGH_BEAM_OFF_REASON_MOVING_VISION_TARGET" 0 "HIGH_BEAM_ON" ;
VAL_ 1001 DAS_mirrorFoldRequest 3 "DAS_MIRROR_REQUEST_SNA" 2 "DAS_MIRROR_REQUEST_UNFOLD" 1 "DAS_MIRROR_REQUEST_FOLD" 0 "DAS_MIRROR_REQUEST_NONE" ;
VAL_ 1001 DAS_autoWiperState 5 "DAS_AUTO_WIPER_STATE_SNA" 4 "DAS_AUTO_WIPER_STATE_FAST_CONTINUOUS" 3 "DAS_AUTO_WIPER_STATE_SLOW_CONTINUOUS" 2 "DAS_AUTO_WIPER_STATE_FAST_INTERMITTENT" 1 "DAS_AUTO_WIPER_STATE_SLOW_INTERMITTENT" 0 "DAS_AUTO_WIPER_STATE_OFF" ;
VAL_ 1001 DAS_turnIndicatorRequestReason 24 "DAS_ACTIVE_SIMULTANEOUS_LANE_CHANGE_AVOIDANCE" 23 "DAS_ACTIVE_INFEASIBLE_KINEMATICS_LANE_CHANGE" 22 "DAS_ACTIVE_STAY_OUT_OF_RIGHTMOST_LANE_LANE_CHANGE" 21 "DAS_ACTIVE_AWAY_FROM_MERGE_LANE_CHANGE" 20 "DAS_ACTIVE_EXIT_RIGHT_LANE_LANE_CHANGE" 19 "DAS_ACTIVE_EXIT_PASSING_LANE_LANE_CHANGE" 18 "DAS_ACTIVE_INCORRECT_ROAD_SIDE_LANE_CHANGE" 17 "DAS_ACTIVE_STATIC_OBJECT_LANE_CHANGE" 15 "DAS_CANCEL_MANUAL_BLINKER" 14 "DAS_CANCEL_AUTO_PARK" 13 "DAS_ACTIVE_AUTO_PARK" 12 "DAS_CANCEL_SUMMMON" 11 "DAS_ACTIVE_SUMMMON" 10 "DAS_CANCEL_INTERSECTION" 9 "DAS_ACTIVE_INTERSECTION" 8 "DAS_ACTIVE_COMMANDED_LANE_CHANGE" 7 "DAS_CANCEL_MERGE" 6 "DAS_ACTIVE_MERGE" 5 "DAS_CANCEL_FORK" 4 "DAS_CANCEL_LANE_CHANGE" 3 "DAS_ACTIVE_FORK" 2 "DAS_ACTIVE_SPEED_LANE_CHANGE" 1 "DAS_ACTIVE_NAV_LANE_CHANGE" 0 "DAS_NONE" ;
VAL_ 1001 DAS_restrictDoorReleaseLeft 1 "RESTRICT_DOOR_RELEASE_ACTIVE" 0 "RESTRICT_DOOR_RELEASE_INACTIVE" ;
VAL_ 1001 DAS_restrictDoorReleaseRight 1 "RESTRICT_DOOR_RELEASE_ACTIVE" 0 "RESTRICT_DOOR_RELEASE_INACTIVE" ;
VAL_ 741 DIF_elecPower -1024 "SNA" ;
VAL_ 741 DIF_drivePowerMax 511 "SNA" ;
VAL_ 1367 DIF_oilFlowReq 255 "SNA" ;
VAL_ 1367 DIF_criticalFlowReq 1 "ACTIVE" 0 "NOT_ACTIVE" ;
VAL_ 1367 DIF_burnInStatus 5 "COMPLETE" 4 "ACTIVE" 3 "INCOMPLETE" 2 "UNAVAILABLE" 1 "NOT_REQUIRED" 0 "INIT" ;
VAL_ 2005 DIR_debugSelector 132 "Mux132" 131 "Mux131" 128 "Mux128" 72 "Mux72" 70 "Mux70" 69 "Mux69" 68 "Mux68" 67 "Mux67" 66 "Mux66" 64 "Mux64" 63 "Mux63" 52 "Mux52" 50 "Mux50" 49 "Mux49" 48 "Mux48" 47 "Mux47" 46 "Mux46" 44 "Mux44" 43 "Mux43" 42 "Mux42" 41 "Mux41" 40 "Mux40" 39 "Mux39" 38 "Mux38" 37 "Mux37" 36 "Mux36" 35 "Mux35" 34 "Mux34" 33 "Mux33" 32 "Mux32" ;
VAL_ 2005 DIR_phaseOutBusbarTemp 0 "SNA" ;
VAL_ 2005 DIR_phaseOutBusbarWeldTemp 0 "SNA" ;
VAL_ 2005 DIR_phaseOutLugTemp 0 "SNA" ;
VAL_ 2005 DIR_dcLinkCapTemp 0 "SNA" ;
VAL_ 2005 DIR_hvDcCableTemp 0 "SNA" ;
VAL_ 2005 DIR_negDcBusbarTemp 0 "SNA" ;
VAL_ 2005 DIR_posDcBusbarTemp 0 "SNA" ;
VAL_ 2005 DIR_statorEndWindingTemp 0 "SNA" ;
VAL_ 2005 DIR_rotorMaxMagnetTemp 0 "SNA" ;
VAL_ 2005 DIR_statorSlotWindingTemp 0 "SNA" ;
VAL_ 917 DIR_oilPumpState 7 "OIL_PUMP_SNA" 6 "OIL_PUMP_FAULTED" 2 "OIL_PUMP_COLD_STARTUP" 1 "OIL_PUMP_ENABLE" 0 "OIL_PUMP_STANDBY" ;
VAL_ 917 DIR_oilPumpFluidTQF 1 "OIL_PUMP_FLUIDT_HIGH_CONFIDENCE" 0 "OIL_PUMP_FLUIDT_LOW_CONFIDENCE" ;
VAL_ 917 DIR_oilPumpFlowTarget 255 "SNA" ;
VAL_ 917 DIR_oilPumpFlowActual 255 "SNA" ;
VAL_ 917 DIR_oilPumpFluidT 255 "SNA" ;
VAL_ 917 DIR_oilPumpPhaseCurrent 255 "SNA" ;
VAL_ 917 DIR_oilPumpPressureEstimate 255 "SNA" ;
VAL_ 917 DIR_oilPumpPressureExpected 255 "SNA" ;
VAL_ 917 DIR_oilPumpPressureResidual 255 "SNA" ;
VAL_ 614 DIR_elecPower -1024 "SNA" ;
VAL_ 614 DIR_drivePowerMax 511 "SNA" ;
VAL_ 1495 DIR_oilFlowReq 255 "SNA" ;
VAL_ 1495 DIR_criticalFlowReq 1 "ACTIVE" 0 "NOT_ACTIVE" ;
VAL_ 1495 DIR_burnInStatus 5 "COMPLETE" 4 "ACTIVE" 3 "INCOMPLETE" 2 "UNAVAILABLE" 1 "NOT_REQUIRED" 0 "INIT" ;
VAL_ 2007 DI_debugSelector 75 "longControl" 69 "Mux69" 68 "Mux68" 67 "Mux67" 66 "Mux66" 65 "Mux65" 53 "Mux53" 50 "sysHeat" 45 "aeb" 39 "regenBackfill" 38 "pedalTorque1" 37 "onePedalDriving3" 36 "onePedalDriving2" 35 "onePedalDriving1" 34 "sysPedal" 33 "Mux33" 32 "pwrSat" 2 "Mux2" ;
VAL_ 2007 DI_regenBackfillUnavailableReaso 18 "DI_LATENT_FAULT_TRIP" 17 "EBR_FULL_FAULT" 16 "PM_DISABLE_REQUEST_BPED" 15 "PM_DISABLE_REQUEST_BLEND" 14 "CARBON_CERAMIC_BRAKES" 13 "BRAKE_TEMP" 12 "EBR_FAULT" 11 "PM_DISABLE_REQUEST" 10 "TRACK_MODE_ACTIVE" 9 "VELOCITY_ESTIMATOR_UNAVAILABLE" 8 "TRACTION_CONTROL_UNAVAILABLE" 7 "ACTIVE_DAMPING_UNAVAILABLE" 6 "UI_COASTDOWN_MODE" 5 "SYSTEM_STATE" 4 "NON_DRIVE_GEAR" 3 "EBR_UNAVAILABLE" 2 "UI_DISABLE" 1 "GTW_DISABLE" 0 "NONE" ;
VAL_ 2007 DI_regenBackfillAbsSatState 2 "RAMP_IN" 1 "RAMP_OUT" 0 "IDLE" ;
VAL_ 616 DI_sysDrivePowerMax 511 "SNA" ;
VAL_ 616 DI_primaryUnitSiliconType 1 "IGBT" 0 "MOSFET" ;
VAL_ 616 DI_sysRegenPowerMax 255 "SNA" ;
VAL_ 1992 EPBL_infoIndex 255 "END" 41 "SUBCOMPONENT14" 40 "SUBCOMPONENT13" 39 "SUBCOMPONENT12" 38 "SUBCOMPONENT11" 37 "SUBCOMPONENT10" 36 "SUBCOMPONENT9" 35 "SUBCOMPONENT8" 34 "SUBCOMPONENT7" 33 "SUBCOMPONENT6" 32 "SUBCOMPONENT5" 31 "SUBCOMPONENT4" 24 "SUBCOMPONENT3" 23 "SUBCOMPONENT2" 20 "UDS_PROTOCOL_BOOTCRC" 19 "VERSION_DEPRECATED" 18 "BOOTLOADER_GITHASH" 17 "APP_GITHASH" 16 "SUBCOMPONENT1" 15 "BOOTLOADER_CRC" 14 "BOOTLOADER_SVN" 13 "APP_CRC" 11 "PCBAID_ASSYID_USAGEID" 10 "BUILD_HWID_COMPONENTID" 9 "DEPRECATED_9" 8 "DEPRECATED_8" 7 "DEPRECATED_7" 6 "DEPRECATED_6" 5 "DEPRECATED_5" 4 "DEPRECATED_4" 3 "DEPRECATED_3" 2 "DEPRECATED_2" 1 "DEPRECATED_1" 0 "DEPRECATED_0" ;
VAL_ 1992 EPBL_infoBuildType 4 "INFO_MFG_BUILD" 3 "INFO_TRACEABLE_CI_BUILD" 2 "INFO_LOCAL_BUILD" 1 "INFO_PLATFORM_BUILD" 0 "INFO_UNKNOWN_BUILD" ;
VAL_ 1992 EPBL_infoAssemblyId 255 "ASSEMBLY_SNA" 1 "ASSEMBLY1" ;
VAL_ 648 EPBL_unitStatus 23 "EPB_STATUS_COUNT" 22 "EPB_STATUS_AUTONOMY_OPEN" 21 "EPB_STATUS_FREE_ROLL_MODE" 20 "EPB_STATUS_DYNAMIC_PARKING" 19 "EPB_STATUS_EXTERNAL_PARKING" 18 "EPB_STATUS_RELEASING_FOR_EXTERNAL_PARK" 17 "EPB_STATUS_EXTERNAL_DYNAMIC" 16 "EPB_STATUS_SUMMON_PARKING" 15 "EPB_STATUS_SUMMON_RELEASING" 14 "EPB_STATUS_SUMMON" 13 "EPB_STATUS_WINCHMODE_PENDING" 12 "EPB_STATUS_PARK_PENDING" 11 "EPB_STATUS_SERVICE_RELEASING" 10 "EPB_STATUS_RELEASING" 9 "EPB_STATUS_DYNAMIC_APPLYING" 8 "EPB_STATUS_PARKING" 7 "EPB_STATUS_WINCHMODE_RELEASING" 6 "EPB_STATUS_WINCHMODE" 5 "EPB_STATUS_SERVICE" 4 "EPB_STATUS_START" 3 "EPB_STATUS_PARK" 2 "EPB_STATUS_DYNAMIC" 1 "EPB_STATUS_OPEN" 0 "EPB_STATUS_UNKNOWN" ;
VAL_ 648 EPBL_unitFaultStatus 3 "EPB_STATUS_FAULT_IDLE" 2 "EPB_STATUS_FAULT" 1 "EPB_STATUS_RETRY" 0 "EPB_STATUS_NOMINAL" ;
VAL_ 648 EPBL_summonState 6 "EPB_SUMMON_UNAVAILABLE" 5 "EPB_SUMMON_FAULT" 4 "EPB_SUMMON_COMPLETE" 3 "EPB_SUMMON_ACTIVE" 2 "EPB_SUMMON_ARMED" 1 "EPB_SUMMON_IDLE" 0 "EPB_SUMMON_INIT" ;
VAL_ 648 EPBL_csmFaultReason 23 "CSM_FAULT_REMOTE_MIA" 22 "CSM_FAULT_NVM_MISMATCH" 21 "CSM_FAULT_EPBM_MIA" 20 "CSM_FAULT_MOTOR_NOT_READY" 19 "CSM_FAULT_MOTOR_ACTIVE_FAULT" 18 "CSM_FAULT_MOTOR_IDLE_FAULT" 17 "CSM_FAULT_TIMEOUT_EPBM_START" 16 "CSM_FAULT_TIMEOUT_NO_RAMP" 15 "CSM_FAULT_TIMEOUT_EPBM_CUTOFF" 14 "CSM_FAULT_TIMEOUT_RELEASE_COMPLETE" 13 "CSM_FAULT_TIMEOUT_RELEASE_NO_LOAD" 12 "CSM_FAULT_TIMEOUT_RELEASE_WAIT_FOR_ENDSTOP" 11 "CSM_FAULT_TIMEOUT_RELEASE_INRUSH" 10 "CSM_FAULT_TIMEOUT_EPBM_WAIT_FOR_CLAMP" 9 "CSM_FAULT_TIMEOUT_EPB_WAIT_FOR_CLAMP" 8 "CSM_FAULT_TIMEOUT_APPLY_INRUSH" 7 "CSM_FAULT_TIMEOUT_APPLY_COMPLETE" 6 "CSM_FAULT_RELEASE_BLOCKED" 5 "CSM_FAULT_APPLY_BLOCKED" 4 "CSM_FAULT_TIMEOUT_CALIBRATE" 3 "CSM_FAULT_STATE_MISMATCH" 2 "CSM_FAULT_EPBM_FAULTED" 1 "CSM_FAULT_EPBM_DISABLED" 0 "CSM_FAULT_NONE" ;
VAL_ 648 EPBL_esmOperationTrigger 50 "EPB_TRIGGER_ACTIVE_DECEL_DAS_STATIC" 49 "EPB_TRIGGER_ACTIVE_DECEL_CDP_DOWN" 48 "EPB_TRIGGER_AP_IS_LEAVING" 47 "EPB_TRIGGER_RECOVERY_PARK" 46 "EPB_TRIGGER_SPEED_SOURCES_LOST" 45 "EPB_TRIGGER_ACTIVE_DECEL_OKTOPARK" 44 "EPB_TRIGGER_ACTIVE_DECEL_FAST" 43 "EPB_TRIGGER_STEERING_ACTIVE_DECEL" 42 "EPB_TRIGGER_LV_ACTIVE_DECEL" 41 "EPB_TRIGGER_CDP_PANIC_MODE_READY" 40 "EPB_TRIGGER_CDP_PANIC_MODE_TIMEOUT" 39 "EPB_TRIGGER_DI_PARK" 38 "EPB_TRIGGER_FREE_ROLL_PARK_FOR_HANDLE_PULLED" 37 "EPB_TRIGGER_LOW_BRAKE_FLUID_MODE_DYNAMIC" 36 "EPB_TRIGGER_LOW_BRAKE_FLUID_MODE_DYNAMIC_PARK" 35 "EPB_TRIGGER_LOW_BRAKE_FLUID_MODE_PARK" 34 "EPB_TRIGGER_STATIONARY_DETECT" 33 "EPB_TRIGGER_TOUCHSCREEN_INVALID" 32 "EPB_TRIGGER_UI_DOOR_OPEN_REQUEST" 31 "EPB_TRIGGER_AUTOPARK_END" 30 "EPB_TRIGGER_DRIVER_IS_LEAVING" 29 "EPB_TRIGGER_SYSTEM_APPLY" 28 "EPB_TRIGGER_ACCELERATION" 27 "EPB_TRIGGER_EPBM_DISQUALIFIED" 26 "EPB_TRIGGER_DISQUALIFIED" 25 "EPB_TRIGGER_SUMMON_FAULT" 24 "EPB_TRIGGER_FAULT" 23 "EPB_TRIGGER_SUMMON_COMPLETE" 22 "EPB_TRIGGER_REAPPLY" 21 "EPB_TRIGGER_SAVESTATE_ON_BOOT" 20 "EPB_TRIGGER_TIMEOUT" 19 "EPB_TRIGGER_SPEED_FAST" 18 "EPB_TRIGGER_SPEED_OKAYTOPARK" 17 "EPB_TRIGGER_SPEED_STOPPED" 16 "EPB_TRIGGER_USER_CANCEL" 15 "EPB_TRIGGER_USER_CONFIRMED" 14 "EPB_TRIGGER_DIAG_EXIT" 13 "EPB_TRIGGER_DIAG_OPEN" 12 "EPB_TRIGGER_DIAG_CLOSE" 11 "EPB_TRIGGER_SERVICE" 10 "EPB_TRIGGER_WINCHMODE_UNAVAILABLE" 9 "EPB_TRIGGER_WINCHMODE_ENTER" 8 "EPB_TRIGGER_WINCHMODE_EXIT" 7 "EPB_TRIGGER_TOUCHSCREEN" 6 "EPB_TRIGGER_DI_UNPARK" 5 "EPB_TRIGGER_ACTIVE_PARK_REQUEST" 4 "EPB_TRIGGER_PBUTTON_RELEASED" 3 "EPB_TRIGGER_PBUTTON_PRESSED_UNKNOWN" 2 "EPB_TRIGGER_PBUTTON_PRESSED_FAST" 1 "EPB_TRIGGER_PBUTTON_PRESSED_OKTOPARK" 0 "EPB_TRIGGER_PBUTTON_PRESSED_STOPPED" ;
VAL_ 648 EPBL_summonFaultReason 30 "EPB_SUMMONFAULT_MONITOR_TYPE_UNKNOWN" 29 "EPB_SUMMONFAULT_AP_MONITOR" 28 "EPB_SUMMONFAULT_REMOTE_DID_NOT_START" 27 "EPB_SUMMONFAULT_INVALID_REMOTE_STATE" 26 "EPB_SUMMONFAULT_START_IN_UNAVAILABLE" 25 "EPB_SUMMONFAULT_REMOTE_UNIT_FAULTED" 24 "EPB_SUMMONFAULT_LOCAL_UNIT_FAULTED" 23 "EPB_SUMMONFAULT_REMOTE_SUMMON_FAULTED" 22 "EPB_SUMMONFAULT_EPBREMOTE_MIA" 21 "EPB_SUMMONFAULT_PASSIVE_REQUEST" 20 "EPB_SUMMONFAULT_DI_STATE_INVALID" 19 "EPB_SUMMONFAULT_EPB_FAULT" 18 "EPB_SUMMONFAULT_MISMATCH" 17 "EPB_SUMMONFAULT_OOC" 16 "EPB_SUMMONFAULT_PM_REQUEST" 15 "EPB_SUMMONFAULT_PM_MIA" 14 "EPB_SUMMONFAULT_PARK_MIA" 13 "EPB_SUMMONFAULT_EXTERNAL" 12 "EPB_SUMMONFAULT_SPEED" 11 "EPB_SUMMONFAULT_EPBM_REQUEST" 10 "EPB_SUMMONFAULT_EAC_NOT_ALLOWED" 9 "EPB_SUMMONFAULT_VEH_CAN_FAULT" 8 "EPB_SUMMONFAULT_ESP_FAULT" 7 "EPB_SUMMONFAULT_DAS_FAULT" 6 "EPB_SUMMONFAULT_DI_APC_FAULT" 5 "EPB_SUMMONFAULT_DI_FAULT" 4 "EPB_SUMMONFAULT_EPBM_MIA" 3 "EPB_SUMMONFAULT_ESP_MIA" 2 "EPB_SUMMONFAULT_DAS_MIA" 1 "EPB_SUMMONFAULT_DI_MIA" 0 "EPB_SUMMONFAULT_NONE" ;
VAL_ 648 EPBL_localCdpState 2 "EPB_CDP_STATE_FAULT" 1 "EPB_CDP_STATE_VALID" 0 "EPB_CDP_STATE_UNKNOWN" ;
VAL_ 648 EPBL_chimeRequestLocal 4 "EPB_CHIME_REQUEST_ACTIVE_DECEL" 3 "EPB_CHIME_REQUEST_ABOUT_TO_ACTIVE_DECEL" 2 "EPB_CHIME_REQUEST_GPO" 1 "EPB_CHIME_REQUEST_GENERAL" 0 "EPB_CHIME_REQUEST_NONE" ;
VAL_ 648 EPBL_telltaleLocal 7 "EPB_TELLTALE_SNA" 4 "EPB_TELLTALE_LAMP_RED_FLASH" 3 "EPB_TELLTALE_LAMP_AMBER_ON" 2 "EPB_TELLTALE_LAMP_RED_ON" 1 "EPB_TELLTALE_LAMP_RED_PARKED" 0 "EPB_TELLTALE_LAMP_OFF" ;
VAL_ 648 EPBL_internalCDPRequest 1 "EPB_CDP_REQUESTED" 0 "EPB_CDP_NOT_REQUESTED" ;
VAL_ 648 EPBL_esmSpeedClass 4 "ESM_SPEED_CLASS_UNKNOWN" 3 "ESM_SPEED_CLASS_FAST" 2 "ESM_SPEED_CLASS_USER_APPLY_OK" 1 "ESM_SPEED_CLASS_SYSTEM_APPLY_OK" 0 "ESM_SPEED_CLASS_STOPPED" ;
VAL_ 648 EPBL_learnedEpbConfig 11 "EPB_CONFIG_CT_MANDO" 10 "EPB_CONFIG_MODEL3_ZF" 9 "EPB_CONFIG_MODELS_CERAMIC" 8 "EPB_CONFIG_MODELY_PERFORMANCE_V2" 7 "EPB_CONFIG_MODEL3_PERFORMANCE_V2" 6 "EPB_CONFIG_MODELX_BASE" 5 "EPB_CONFIG_MODELY_PERFORMANCE" 4 "EPB_CONFIG_MODELY_BASE" 3 "EPB_CONFIG_MODELS_BASE" 2 "EPB_CONFIG_MODEL3_PERFORMANCE" 1 "EPB_CONFIG_MODEL3_BASE" 0 "EPB_CONFIG_UNKNOWN" ;
VAL_ 2024 EPBR_infoIndex 255 "END" 41 "SUBCOMPONENT14" 40 "SUBCOMPONENT13" 39 "SUBCOMPONENT12" 38 "SUBCOMPONENT11" 37 "SUBCOMPONENT10" 36 "SUBCOMPONENT9" 35 "SUBCOMPONENT8" 34 "SUBCOMPONENT7" 33 "SUBCOMPONENT6" 32 "SUBCOMPONENT5" 31 "SUBCOMPONENT4" 24 "SUBCOMPONENT3" 23 "SUBCOMPONENT2" 20 "UDS_PROTOCOL_BOOTCRC" 19 "VERSION_DEPRECATED" 18 "BOOTLOADER_GITHASH" 17 "APP_GITHASH" 16 "SUBCOMPONENT1" 15 "BOOTLOADER_CRC" 14 "BOOTLOADER_SVN" 13 "APP_CRC" 11 "PCBAID_ASSYID_USAGEID" 10 "BUILD_HWID_COMPONENTID" 9 "DEPRECATED_9" 8 "DEPRECATED_8" 7 "DEPRECATED_7" 6 "DEPRECATED_6" 5 "DEPRECATED_5" 4 "DEPRECATED_4" 3 "DEPRECATED_3" 2 "DEPRECATED_2" 1 "DEPRECATED_1" 0 "DEPRECATED_0" ;
VAL_ 2024 EPBR_infoBuildType 4 "INFO_MFG_BUILD" 3 "INFO_TRACEABLE_CI_BUILD" 2 "INFO_LOCAL_BUILD" 1 "INFO_PLATFORM_BUILD" 0 "INFO_UNKNOWN_BUILD" ;
VAL_ 2024 EPBR_infoAssemblyId 255 "ASSEMBLY_SNA" 1 "ASSEMBLY1" ;
VAL_ 552 EPBR_unitStatus 23 "EPB_STATUS_COUNT" 22 "EPB_STATUS_AUTONOMY_OPEN" 21 "EPB_STATUS_FREE_ROLL_MODE" 20 "EPB_STATUS_DYNAMIC_PARKING" 19 "EPB_STATUS_EXTERNAL_PARKING" 18 "EPB_STATUS_RELEASING_FOR_EXTERNAL_PARK" 17 "EPB_STATUS_EXTERNAL_DYNAMIC" 16 "EPB_STATUS_SUMMON_PARKING" 15 "EPB_STATUS_SUMMON_RELEASING" 14 "EPB_STATUS_SUMMON" 13 "EPB_STATUS_WINCHMODE_PENDING" 12 "EPB_STATUS_PARK_PENDING" 11 "EPB_STATUS_SERVICE_RELEASING" 10 "EPB_STATUS_RELEASING" 9 "EPB_STATUS_DYNAMIC_APPLYING" 8 "EPB_STATUS_PARKING" 7 "EPB_STATUS_WINCHMODE_RELEASING" 6 "EPB_STATUS_WINCHMODE" 5 "EPB_STATUS_SERVICE" 4 "EPB_STATUS_START" 3 "EPB_STATUS_PARK" 2 "EPB_STATUS_DYNAMIC" 1 "EPB_STATUS_OPEN" 0 "EPB_STATUS_UNKNOWN" ;
VAL_ 552 EPBR_unitFaultStatus 3 "EPB_STATUS_FAULT_IDLE" 2 "EPB_STATUS_FAULT" 1 "EPB_STATUS_RETRY" 0 "EPB_STATUS_NOMINAL" ;
VAL_ 552 EPBR_summonState 6 "EPB_SUMMON_UNAVAILABLE" 5 "EPB_SUMMON_FAULT" 4 "EPB_SUMMON_COMPLETE" 3 "EPB_SUMMON_ACTIVE" 2 "EPB_SUMMON_ARMED" 1 "EPB_SUMMON_IDLE" 0 "EPB_SUMMON_INIT" ;
VAL_ 552 EPBR_csmFaultReason 23 "CSM_FAULT_REMOTE_MIA" 22 "CSM_FAULT_NVM_MISMATCH" 21 "CSM_FAULT_EPBM_MIA" 20 "CSM_FAULT_MOTOR_NOT_READY" 19 "CSM_FAULT_MOTOR_ACTIVE_FAULT" 18 "CSM_FAULT_MOTOR_IDLE_FAULT" 17 "CSM_FAULT_TIMEOUT_EPBM_START" 16 "CSM_FAULT_TIMEOUT_NO_RAMP" 15 "CSM_FAULT_TIMEOUT_EPBM_CUTOFF" 14 "CSM_FAULT_TIMEOUT_RELEASE_COMPLETE" 13 "CSM_FAULT_TIMEOUT_RELEASE_NO_LOAD" 12 "CSM_FAULT_TIMEOUT_RELEASE_WAIT_FOR_ENDSTOP" 11 "CSM_FAULT_TIMEOUT_RELEASE_INRUSH" 10 "CSM_FAULT_TIMEOUT_EPBM_WAIT_FOR_CLAMP" 9 "CSM_FAULT_TIMEOUT_EPB_WAIT_FOR_CLAMP" 8 "CSM_FAULT_TIMEOUT_APPLY_INRUSH" 7 "CSM_FAULT_TIMEOUT_APPLY_COMPLETE" 6 "CSM_FAULT_RELEASE_BLOCKED" 5 "CSM_FAULT_APPLY_BLOCKED" 4 "CSM_FAULT_TIMEOUT_CALIBRATE" 3 "CSM_FAULT_STATE_MISMATCH" 2 "CSM_FAULT_EPBM_FAULTED" 1 "CSM_FAULT_EPBM_DISABLED" 0 "CSM_FAULT_NONE" ;
VAL_ 552 EPBR_esmOperationTrigger 50 "EPB_TRIGGER_ACTIVE_DECEL_DAS_STATIC" 49 "EPB_TRIGGER_ACTIVE_DECEL_CDP_DOWN" 48 "EPB_TRIGGER_AP_IS_LEAVING" 47 "EPB_TRIGGER_RECOVERY_PARK" 46 "EPB_TRIGGER_SPEED_SOURCES_LOST" 45 "EPB_TRIGGER_ACTIVE_DECEL_OKTOPARK" 44 "EPB_TRIGGER_ACTIVE_DECEL_FAST" 43 "EPB_TRIGGER_STEERING_ACTIVE_DECEL" 42 "EPB_TRIGGER_LV_ACTIVE_DECEL" 41 "EPB_TRIGGER_CDP_PANIC_MODE_READY" 40 "EPB_TRIGGER_CDP_PANIC_MODE_TIMEOUT" 39 "EPB_TRIGGER_DI_PARK" 38 "EPB_TRIGGER_FREE_ROLL_PARK_FOR_HANDLE_PULLED" 37 "EPB_TRIGGER_LOW_BRAKE_FLUID_MODE_DYNAMIC" 36 "EPB_TRIGGER_LOW_BRAKE_FLUID_MODE_DYNAMIC_PARK" 35 "EPB_TRIGGER_LOW_BRAKE_FLUID_MODE_PARK" 34 "EPB_TRIGGER_STATIONARY_DETECT" 33 "EPB_TRIGGER_TOUCHSCREEN_INVALID" 32 "EPB_TRIGGER_UI_DOOR_OPEN_REQUEST" 31 "EPB_TRIGGER_AUTOPARK_END" 30 "EPB_TRIGGER_DRIVER_IS_LEAVING" 29 "EPB_TRIGGER_SYSTEM_APPLY" 28 "EPB_TRIGGER_ACCELERATION" 27 "EPB_TRIGGER_EPBM_DISQUALIFIED" 26 "EPB_TRIGGER_DISQUALIFIED" 25 "EPB_TRIGGER_SUMMON_FAULT" 24 "EPB_TRIGGER_FAULT" 23 "EPB_TRIGGER_SUMMON_COMPLETE" 22 "EPB_TRIGGER_REAPPLY" 21 "EPB_TRIGGER_SAVESTATE_ON_BOOT" 20 "EPB_TRIGGER_TIMEOUT" 19 "EPB_TRIGGER_SPEED_FAST" 18 "EPB_TRIGGER_SPEED_OKAYTOPARK" 17 "EPB_TRIGGER_SPEED_STOPPED" 16 "EPB_TRIGGER_USER_CANCEL" 15 "EPB_TRIGGER_USER_CONFIRMED" 14 "EPB_TRIGGER_DIAG_EXIT" 13 "EPB_TRIGGER_DIAG_OPEN" 12 "EPB_TRIGGER_DIAG_CLOSE" 11 "EPB_TRIGGER_SERVICE" 10 "EPB_TRIGGER_WINCHMODE_UNAVAILABLE" 9 "EPB_TRIGGER_WINCHMODE_ENTER" 8 "EPB_TRIGGER_WINCHMODE_EXIT" 7 "EPB_TRIGGER_TOUCHSCREEN" 6 "EPB_TRIGGER_DI_UNPARK" 5 "EPB_TRIGGER_ACTIVE_PARK_REQUEST" 4 "EPB_TRIGGER_PBUTTON_RELEASED" 3 "EPB_TRIGGER_PBUTTON_PRESSED_UNKNOWN" 2 "EPB_TRIGGER_PBUTTON_PRESSED_FAST" 1 "EPB_TRIGGER_PBUTTON_PRESSED_OKTOPARK" 0 "EPB_TRIGGER_PBUTTON_PRESSED_STOPPED" ;
VAL_ 552 EPBR_summonFaultReason 30 "EPB_SUMMONFAULT_MONITOR_TYPE_UNKNOWN" 29 "EPB_SUMMONFAULT_AP_MONITOR" 28 "EPB_SUMMONFAULT_REMOTE_DID_NOT_START" 27 "EPB_SUMMONFAULT_INVALID_REMOTE_STATE" 26 "EPB_SUMMONFAULT_START_IN_UNAVAILABLE" 25 "EPB_SUMMONFAULT_REMOTE_UNIT_FAULTED" 24 "EPB_SUMMONFAULT_LOCAL_UNIT_FAULTED" 23 "EPB_SUMMONFAULT_REMOTE_SUMMON_FAULTED" 22 "EPB_SUMMONFAULT_EPBREMOTE_MIA" 21 "EPB_SUMMONFAULT_PASSIVE_REQUEST" 20 "EPB_SUMMONFAULT_DI_STATE_INVALID" 19 "EPB_SUMMONFAULT_EPB_FAULT" 18 "EPB_SUMMONFAULT_MISMATCH" 17 "EPB_SUMMONFAULT_OOC" 16 "EPB_SUMMONFAULT_PM_REQUEST" 15 "EPB_SUMMONFAULT_PM_MIA" 14 "EPB_SUMMONFAULT_PARK_MIA" 13 "EPB_SUMMONFAULT_EXTERNAL" 12 "EPB_SUMMONFAULT_SPEED" 11 "EPB_SUMMONFAULT_EPBM_REQUEST" 10 "EPB_SUMMONFAULT_EAC_NOT_ALLOWED" 9 "EPB_SUMMONFAULT_VEH_CAN_FAULT" 8 "EPB_SUMMONFAULT_ESP_FAULT" 7 "EPB_SUMMONFAULT_DAS_FAULT" 6 "EPB_SUMMONFAULT_DI_APC_FAULT" 5 "EPB_SUMMONFAULT_DI_FAULT" 4 "EPB_SUMMONFAULT_EPBM_MIA" 3 "EPB_SUMMONFAULT_ESP_MIA" 2 "EPB_SUMMONFAULT_DAS_MIA" 1 "EPB_SUMMONFAULT_DI_MIA" 0 "EPB_SUMMONFAULT_NONE" ;
VAL_ 552 EPBR_localCdpState 2 "EPB_CDP_STATE_FAULT" 1 "EPB_CDP_STATE_VALID" 0 "EPB_CDP_STATE_UNKNOWN" ;
VAL_ 552 EPBR_chimeRequestLocal 4 "EPB_CHIME_REQUEST_ACTIVE_DECEL" 3 "EPB_CHIME_REQUEST_ABOUT_TO_ACTIVE_DECEL" 2 "EPB_CHIME_REQUEST_GPO" 1 "EPB_CHIME_REQUEST_GENERAL" 0 "EPB_CHIME_REQUEST_NONE" ;
VAL_ 552 EPBR_telltaleLocal 7 "EPB_TELLTALE_SNA" 4 "EPB_TELLTALE_LAMP_RED_FLASH" 3 "EPB_TELLTALE_LAMP_AMBER_ON" 2 "EPB_TELLTALE_LAMP_RED_ON" 1 "EPB_TELLTALE_LAMP_RED_PARKED" 0 "EPB_TELLTALE_LAMP_OFF" ;
VAL_ 552 EPBR_internalCDPRequest 1 "EPB_CDP_REQUESTED" 0 "EPB_CDP_NOT_REQUESTED" ;
VAL_ 552 EPBR_esmSpeedClass 4 "ESM_SPEED_CLASS_UNKNOWN" 3 "ESM_SPEED_CLASS_FAST" 2 "ESM_SPEED_CLASS_USER_APPLY_OK" 1 "ESM_SPEED_CLASS_SYSTEM_APPLY_OK" 0 "ESM_SPEED_CLASS_STOPPED" ;
VAL_ 552 EPBR_learnedEpbConfig 11 "EPB_CONFIG_CT_MANDO" 10 "EPB_CONFIG_MODEL3_ZF" 9 "EPB_CONFIG_MODELS_CERAMIC" 8 "EPB_CONFIG_MODELY_PERFORMANCE_V2" 7 "EPB_CONFIG_MODEL3_PERFORMANCE_V2" 6 "EPB_CONFIG_MODELX_BASE" 5 "EPB_CONFIG_MODELY_PERFORMANCE" 4 "EPB_CONFIG_MODELY_BASE" 3 "EPB_CONFIG_MODELS_BASE" 2 "EPB_CONFIG_MODEL3_PERFORMANCE" 1 "EPB_CONFIG_MODEL3_BASE" 0 "EPB_CONFIG_UNKNOWN" ;
VAL_ 1322 FC_alertID 321 "a321_FCAlertPlaceholder" 313 "a313_GB_inputVoltageRailOv" 312 "a312_GB_evseLimitsTimeout" 311 "a311_GB_battParamsTimeout" 310 "a310_GB_unused" 309 "a309_GB_unused" 308 "a308_GB_evseConLockTimeout" 307 "a307_GB_fcContOpenTimeout" 306 "a306_GB_vehReadyDeasserted" 305 "a305_GB_posRecogTimeout" 304 "a304_GB_unused" 303 "a303_GB_negRecogTimeout" 302 "a302_GB_unused" 301 "a301_GB_unused" 300 "a300_GB_unused" 299 "a299_GB_evseReadyTimeout" 298 "a298_GB_bmsCtrCloseTimeout" 297 "a297_GB_unused" 296 "a296_GB_invalidPilotTransitio" 295 "a295_GB_pilotRationality" 294 "a294_GB_unused" 293 "a293_GB_proxRationality" 292 "a292_GB_vehConLockTimeout" 291 "a291_GB_vehDataTimeout" 290 "a290_GB_pilotAcceptTimeout" 289 "a289_GB_proxTimeout" 288 "a288_GB_evseAbnormalStopReq" 287 "a287_GB_vehConnUnlocked" 286 "a286_GB_evseConnUnlocked" 285 "a285_GB_proxDisconnected" 284 "a284_GB_pcbTempHiFoldBk" 283 "a283_GB_posTempHiFoldBk" 282 "a282_GB_negTempHiFoldBk" 281 "a281_GB_evseOutOfService" 280 "a280_GB_retryLimitExceeded" 279 "a279_GB_evseOverCurrent" 278 "a278_GB_timeoutCCS" 277 "a277_GB_posToPcbDeltaLo" 276 "a276_GB_negToPcbDeltaLo" 275 "a275_GB_posToPcbDeltaHi" 274 "a274_GB_negToPcbDeltaHi" 273 "a273_GB_negToPosDeltaLo" 272 "a272_GB_negToPosDeltaHi" 271 "a271_GB_timeoutCRO" 270 "a270_GB_timeoutCML" 269 "a269_GB_timeoutCRM" 268 "a268_GB_pcb_OT" 267 "a267_GB_posPin_OT" 266 "a266_GB_negPin_OT" 265 "a265_GB_bmsIncompatible" 264 "a264_GB_timeoutCHM" 263 "a263_GB_hwProxTrip" 262 "a262_GB_evseRxBufOvf" 261 "a261_GB_evseTxBufOvf" 260 "a260_GB_vehRxBufOvf" 259 "a259_GB_vehTxBufOvf" 258 "a258_GB_evseMia" 257 "a257_GB_bmsMia" 193 "a193_FCAlertPlaceholder" 187 "a187_CA_evseConLockTimeout" 186 "a186_CA_fcContOpenTimeout" 185 "a185_CA_vehReadyDeasserted" 184 "a184_CA_evseBatMalfunc" 183 "a183_CA_evseBatIncompat" 182 "a182_CA_evseChrMalfunc" 181 "a181_CA_vRegBrownout" 180 "a180_CA_chargingProblem" 179 "a179_CA_startupProblem" 178 "a178_CA_evseStartTimeout" 177 "a177_CA_bmsCtrCloseTimeout" 176 "a176_CA_chargingBusTimeout" 175 "a175_CA_evseIsoTestTimeout" 174 "a174_CA_vehReadyTimeout" 173 "a173_CA_evseDataTimeout" 172 "a172_CA_ss2LowTimeout" 171 "a171_CA_vehConLockTimeout" 170 "a170_CA_vehDataTimeout" 169 "a169_CA_pilotAcceptTimeout" 168 "a168_CA_proxTimeout" 167 "a167_CA_isoVoltageLow" 166 "a166_CA_vehConnUnlocked" 165 "a165_CA_evseConnUnlocked" 164 "a164_CA_proxDisconnected" 163 "a163_CA_pcbTempHiFoldBk" 162 "a162_CA_evseTempHiFoldBk" 161 "a161_CA_vehTempHiFoldBk" 160 "a160_CA_ss2Deasserted" 159 "a159_CA_wdtExpired" 158 "a158_CA_evseOverCurrent" 157 "a157_CA_unused" 156 "a156_CA_flybackRunTimeout" 155 "a155_CA_evseToPcbDeltaLo" 154 "a154_CA_vehToPcbDeltaLo" 153 "a153_CA_evseToPcbDeltaHi" 152 "a152_CA_vehToPcbDeltaHi" 151 "a151_CA_vehToEvseDeltaLo" 150 "a150_CA_vehToEvseDeltaHi" 149 "a149_CA_pcb_UT" 148 "a148_CA_evseConn_UT" 147 "a147_CA_vehConn_UT" 146 "a146_CA_flybackBusLoadHi" 145 "a145_CA_flybackDataStale" 144 "a144_CA_flybackUnstable" 143 "a143_CA_pcb_OT" 142 "a142_CA_evseConn_OT" 141 "a141_CA_vehConn_OT" 140 "a140_CA_bmsIncompatible" 139 "a139_CA_ss2NotLow" 138 "a138_CA_hwProxTrip" 137 "a137_CA_evseRxBufOvf" 136 "a136_CA_evseTxBufOvf" 135 "a135_CA_vehRxBufOvf" 134 "a134_CA_vehTxBufOvf" 133 "a133_CA_evseMia" 132 "a132_CA_bmsMia" 131 "a131_CA_flyback_HW_OV" 130 "a130_CA_flyback_SW_OV" 129 "a129_CA_flyback_HW_OC" 0 "ALERT_DO_NOT_USE_ZERO" ;
VAL_ 1322 FC_alertType 1 "FAULT" 0 "WARNING" ;
VAL_ 1117 FC_evseBillingDataSelect 1 "1" 0 "0" ;
VAL_ 1334 FC_evseBilling2DataSelect 0 "FC_EVSEBILLING2_DATASELECT_0" ;
VAL_ 1334 FC_evseBillingEnergyHighRes 16777215 "SNA" ;
VAL_ 1310 FC_infoIndex 255 "END_FC" 27 "PART_NUM_3" 26 "PART_NUM_2" 25 "PART_NUM_1" 22 "VARIANT_CRC_FC" 20 "UDS_PROTOCOL_BOOTCRC_FC" 19 "VERSION_DEPRECATED_FC" 18 "BOOTLOADER_GITHASH_FC" 17 "APP_GITHASH_FC" 16 "SUBCOMPONENT_FC" 15 "BOOTLOADER_CRC_FC" 14 "BOOTLOADER_SVN_FC" 13 "APP_CRC_FC" 11 "PCBAID_ASSYID_USAGEID_FC" 10 "BUILD_HWID_COMPONENTID_FC" 9 "DEPRECATED_9_FC" 8 "DEPRECATED_8_FC" 7 "DEPRECATED_7_FC" 6 "DEPRECATED_6_FC" 5 "DEPRECATED_5_FC" 4 "DEPRECATED_4_FC" 3 "DEPRECATED_3_FC" 2 "DEPRECATED_2_FC" 1 "DEPRECATED_1_FC" 0 "DEPRECATED_0_FC" ;
VAL_ 1310 FC_infoBuildType 4 "INFO_MFG_BUILD_FC" 3 "INFO_TRACEABLE_CI_BUILD_FC" 2 "INFO_LOCAL_BUILD_FC" 1 "INFO_PLATFORM_BUILD_FC" 0 "INFO_UNKNOWN_BUILD_FC" ;
VAL_ 580 FC_powerLimit 8191 "SNA" ;
VAL_ 580 FC_currentLimit 8191 "SNA" ;
VAL_ 580 FC_maxVoltageLimit 8191 "SNA" ;
VAL_ 580 FC_minVoltageLimit 8191 "SNA" ;
VAL_ 702 FC_powerLimit_value -32768 "SNA" ;
VAL_ 702 FC_currentLimit_value -32768 "SNA" ;
VAL_ 702 FC_minVoltageLimit_value -32768 "SNA" ;
VAL_ 1345 FC_maxPowerLimit 8191 "SNA" ;
VAL_ 1345 FC_maxCurrentLimit 8191 "SNA" ;
VAL_ 1300 FC_serialDataSelect 2 "Mux2" 1 "Mux1" 0 "Mux0" ;
VAL_ 532 FC_statusCode 15 "FC_STATUS_NODATA" 14 "FC_STATUS_MALFUNCTION" 13 "FC_STATUS_NOTCOMPATIBLE" 7 "FC_STATUS_POST_OUT_OF_SERVICE" 6 "FC_STATUS_EXT_ISOACTIVE" 5 "FC_STATUS_INT_ISOACTIVE" 4 "FC_STATUS_DEPRECATED_4" 3 "FC_STATUS_DEPRECATED_3" 2 "FC_STATUS_UPDATE_IN_PROGRESS" 1 "FC_STATUS_READY" 0 "FC_STATUS_NOTREADY_SNA" ;
VAL_ 532 FC_type 7 "FC_TYPE_SNA" 6 "FC_TYPE_OTHER" 5 "FC_TYPE_MC_EVSE" 4 "FC_TYPE_COMBO" 3 "FC_TYPE_CC_EVSE" 2 "FC_TYPE_GB" 1 "FC_TYPE_CHADEMO" 0 "FC_TYPE_SUPERCHARGER" ;
VAL_ 532 FC_postID 3 "FC_POST_ID_SNA" 2 "FC_POST_ID_2" 1 "FC_POST_SLAVE" 0 "FC_POST_MASTER" ;
VAL_ 533 FC_externalIsolationResistance 255 "SNA" ;
VAL_ 535 FC_status3DataSelect 1 "Mux1" 0 "Mux0" ;
VAL_ 535 FC_class 2 "FC_CLASS_URBANCHARGER" 1 "FC_CLASS_SUPERCHARGER" 0 "FC_CLASS_SNA" ;
VAL_ 535 FC_brand 1 "TESLA" 0 "SNA" ;
VAL_ 535 FC_coolingType 3 "FC_COOLING_TYPE_IMMERSION" 2 "FC_COOLING_TYPE_CONVECTION" 1 "FC_COOLING_TYPE_LIQUID" 0 "FC_COOLING_TYPE_SNA" ;
VAL_ 535 FC_uiStopType 2 "FC_UI_STOP_TYPE_MOMENTARY" 1 "FC_UI_STOP_TYPE_TOGGLE" 0 "FC_UI_STOP_TYPE_SNA" ;
VAL_ 535 FC_generation 0 "GENERATION_SNA" ;
VAL_ 1650 VC_hcmlInfoIndex 8 "END" 7 "ECULESS_MISC" 6 "ECULESS_LED_VOLTAGES" 5 "ECULESS_IC700_SM_FAULTS" 4 "ECULESS_IC600_DRL_TURN_FAULTS" 3 "ECULESS_IC500_LB_FAULTS" 2 "ECULESS_IC400_HB_FAULTS" 1 "HCML_ASSEMBLY_PCBA_USAGE_ID" 0 "HCML_BUILD_CONFIG_ID_LMM_VARIANT" ;
VAL_ 1650 VC_leftHeadlampLMMVariant 2 "LMM_VARIANT_LMM4" 1 "LMM_VARIANT_NOT_LMM4_OR_UNKNOWN" 0 "LMM_VARIANT_SNA" ;
VAL_ 1980 VC_hcmrInfoIndex 8 "END" 7 "ECULESS_MISC" 6 "ECULESS_LED_VOLTAGES" 5 "ECULESS_IC700_SM_FAULTS" 4 "ECULESS_IC600_DRL_TURN_FAULTS" 3 "ECULESS_IC500_LB_FAULTS" 2 "ECULESS_IC400_HB_FAULTS" 1 "HCMR_ASSEMBLY_PCBA_USAGE_ID" 0 "HCMR_BUILD_CONFIG_ID_LMM_VARIANT" ;
VAL_ 1980 VC_rightHeadlampLMMVariant 2 "LMM_VARIANT_LMM4" 1 "LMM_VARIANT_NOT_LMM4_OR_UNKNOWN" 0 "LMM_VARIANT_SNA" ;
VAL_ 554 HVP_pcsControlRequest 3 "DISCHARGE" 2 "PRECHARGE" 1 "SUPPORT" 0 "SHUTDOWN" ;
VAL_ 554 HVP_dcLinkVoltageFiltered -550 "SNA" ;
VAL_ 784 HVP_infoIndex 255 "END" 31 "SUBCOMPONENT_GITHASH" 30 "PACKAGE_SN_8_14" 29 "PACKAGE_SN_1_7" 27 "PACKAGE_PN_15_20" 26 "PACKAGE_PN_8_14" 25 "PACKAGE_PN_1_7" 23 "SUBCOMPONENT2" 22 "VARIANTCRC" 20 "UDS_PROTOCOL_BOOTCRC" 19 "VERSION_DEPRECATED" 18 "BOOTLOADER_GITHASH" 17 "APP_GITHASH" 16 "SUBCOMPONENT" 15 "BOOTLOADER_CRC" 14 "BOOTLOADER_SVN" 13 "APP_CRC" 11 "PCBAID_ASSYID_USAGEID" 10 "BUILD_HWID_COMPONENTID" 9 "DEPRECATED_9" 8 "DEPRECATED_8" 7 "DEPRECATED_7" 6 "DEPRECATED_6" 5 "DEPRECATED_5" 4 "DEPRECATED_4" 3 "DEPRECATED_3" 2 "DEPRECATED_2" 1 "DEPRECATED_1" 0 "DEPRECATED_0" ;
VAL_ 784 HVP_buildType 4 "INFO_MFG_BUILD" 3 "INFO_TRACEABLE_CI_BUILD" 2 "INFO_LOCAL_BUILD" 1 "INFO_PLATFORM_BUILD" 0 "INFO_UNKNOWN_BUILD" ;
VAL_ 1914 HVP_log1HzIndex 1 "Mux1" 0 "Mux0" ;
VAL_ 1914 HVP_bmbAsicType 3 "BQ796xx" 2 "ADBMS6830" 1 "LTC831" 0 "UNKNOWN" ;
VAL_ 1914 HVP_shuntCurrentAuxLog 8388000 "PACK_CURRENT_SNA" ;
VAL_ 1914 HVP_pyroSquibResistance 65535 "SNA" ;
VAL_ 1914 HVP_hvilCalType 2 "CAN" 1 "LV" 0 "UNKNOWN" ;
VAL_ 941 ICR_infoIndex 255 "END" 31 "SUBCOMPONENT_GITHASH" 30 "PACKAGE_SN_8_14" 29 "PACKAGE_SN_1_7" 27 "PACKAGE_PN_15_20" 26 "PACKAGE_PN_8_14" 25 "PACKAGE_PN_1_7" 23 "SUBCOMPONENT2" 22 "VARIANTCRC" 20 "UDS_PROTOCOL_BOOTCRC" 19 "VERSION_DEPRECATED" 18 "BOOTLOADER_GITHASH" 17 "APP_GITHASH" 16 "SUBCOMPONENT" 15 "BOOTLOADER_CRC" 14 "BOOTLOADER_SVN" 13 "APP_CRC" 11 "PCBAID_ASSYID_USAGEID" 10 "BUILD_HWID_COMPONENTID" 9 "DEPRECATED_9" 8 "DEPRECATED_8" 7 "DEPRECATED_7" 6 "DEPRECATED_6" 5 "DEPRECATED_5" 4 "DEPRECATED_4" 3 "DEPRECATED_3" 2 "DEPRECATED_2" 1 "DEPRECATED_1" 0 "DEPRECATED_0" ;
VAL_ 941 ICR_infoBuildType 4 "INFO_MFG_BUILD" 3 "INFO_TRACEABLE_CI_BUILD" 2 "INFO_LOCAL_BUILD" 1 "INFO_PLATFORM_BUILD" 0 "INFO_UNKNOWN_BUILD" ;
